VERSION ""

NS_ :

BS_:

BU_:

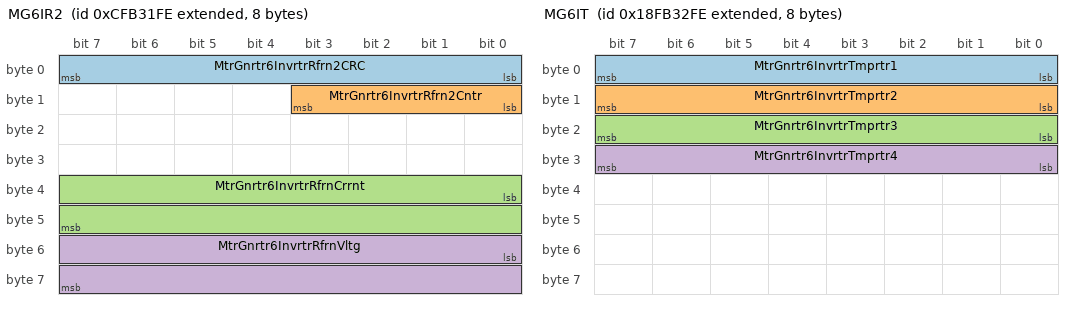
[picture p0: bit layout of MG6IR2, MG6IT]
BO_ 2365272574 MG6IR2: 8 Vector__XXX
 SG_ MtrGnrtr6InvrtrRfrn2CRC : 0|8@1+ (1,0) [0|255] "count" Vector__XXX
 SG_ MtrGnrtr6InvrtrRfrn2Cntr : 8|4@1+ (1,0) [0|15] "" Vector__XXX
 SG_ MtrGnrtr6InvrtrRfrnCrrnt : 32|16@1+ (0.125,0) [0|8031.875] "A" Vector__XXX
 SG_ MtrGnrtr6InvrtrRfrnVltg : 48|16@1+ (0.125,0) [0|8031.875] "V" Vector__XXX

BO_ 2566599422 MG6IT: 8 Vector__XXX
 SG_ MtrGnrtr6InvrtrTmprtr1 : 0|8@1+ (1,-40) [-40|210] "degC" Vector__XXX
 SG_ MtrGnrtr6InvrtrTmprtr2 : 8|8@1+ (1,-40) [-40|210] "degC" Vector__XXX
 SG_ MtrGnrtr6InvrtrTmprtr3 : 16|8@1+ (1,-40) [-40|210] "degC" Vector__XXX
 SG_ MtrGnrtr6InvrtrTmprtr4 : 24|8@1+ (1,-40) [-40|210] "degC" Vector__XXX

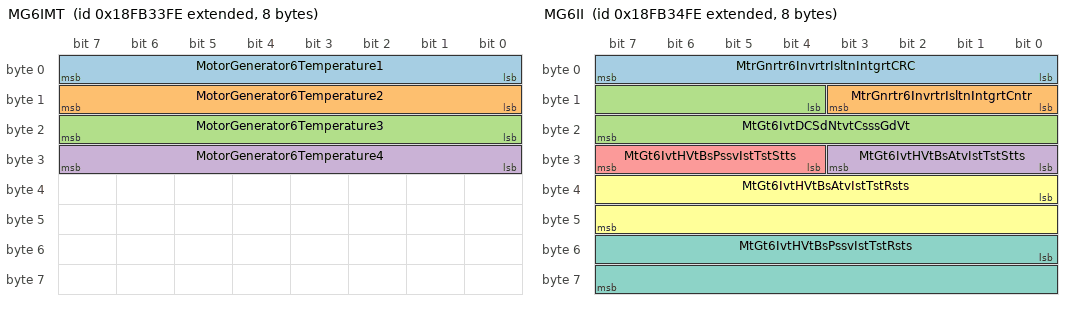
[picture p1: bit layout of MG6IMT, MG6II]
BO_ 2566599678 MG6IMT: 8 Vector__XXX
 SG_ MotorGenerator6Temperature1 : 0|8@1+ (1,-40) [-40|210] "degC" Vector__XXX
 SG_ MotorGenerator6Temperature2 : 8|8@1+ (1,-40) [-40|210] "degC" Vector__XXX
 SG_ MotorGenerator6Temperature3 : 16|8@1+ (1,-40) [-40|210] "degC" Vector__XXX
 SG_ MotorGenerator6Temperature4 : 24|8@1+ (1,-40) [-40|210] "degC" Vector__XXX

BO_ 2566599934 MG6II: 8 Vector__XXX
 SG_ MtrGnrtr6InvrtrIsltnIntgrtCRC : 0|8@1+ (1,0) [0|255] "count" Vector__XXX
 SG_ MtrGnrtr6InvrtrIsltnIntgrtCntr : 8|4@1+ (1,0) [0|15] "" Vector__XXX
 SG_ MtGt6IvtDCSdNtvtCsssGdVt : 12|12@1+ (42370,-125) [-125|125.9375] "%" Vector__XXX
 SG_ MtGt6IvtHVtBsAtvIstTstStts : 24|4@1+ (1,0) [0|15] "" Vector__XXX
 SG_ MtGt6IvtHVtBsPssvIstTstStts : 28|4@1+ (1,0) [0|15] "" Vector__XXX
 SG_ MtGt6IvtHVtBsAtvIstTstRsts : 32|16@1+ (0.1,0) [0|6425.5] "ohm/V" Vector__XXX
 SG_ MtGt6IvtHVtBsPssvIstTstRsts : 48|16@1+ (0.1,0) [0|6425.5] "ohm/V" Vector__XXX

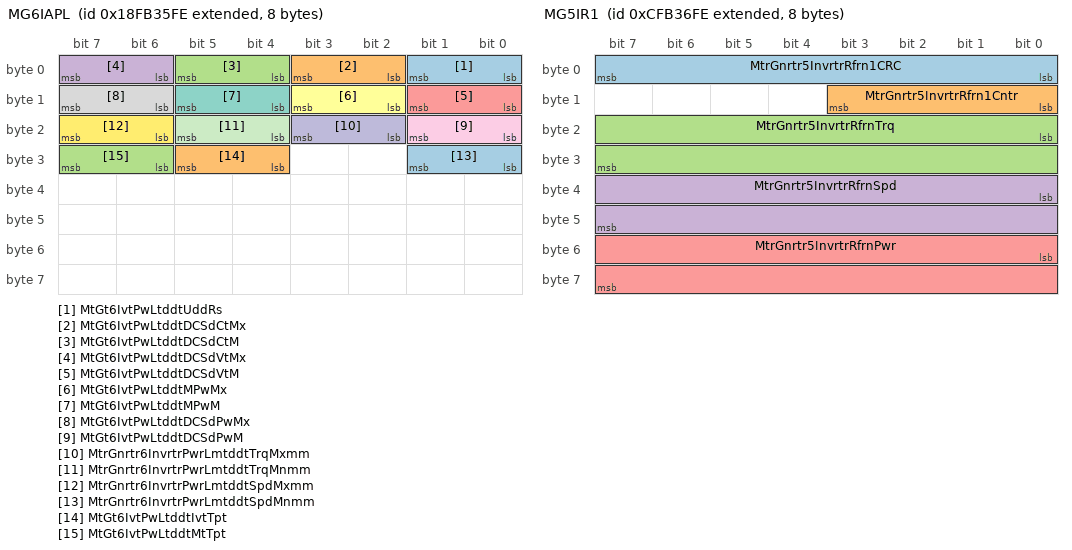
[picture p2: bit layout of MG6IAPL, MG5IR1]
BO_ 2566600190 MG6IAPL: 8 Vector__XXX
 SG_ MtGt6IvtPwLtddtUddRs : 0|2@1+ (1,0) [0|3] "" Vector__XXX
 SG_ MtGt6IvtPwLtddtDCSdCtMx : 2|2@1+ (1,0) [0|3] "" Vector__XXX
 SG_ MtGt6IvtPwLtddtDCSdCtM : 4|2@1+ (1,0) [0|3] "" Vector__XXX
 SG_ MtGt6IvtPwLtddtDCSdVtMx : 6|2@1+ (1,0) [0|3] "" Vector__XXX
 SG_ MtGt6IvtPwLtddtDCSdVtM : 8|2@1+ (1,0) [0|3] "" Vector__XXX
 SG_ MtGt6IvtPwLtddtMPwMx : 10|2@1+ (1,0) [0|3] "" Vector__XXX
 SG_ MtGt6IvtPwLtddtMPwM : 12|2@1+ (1,0) [0|3] "" Vector__XXX
 SG_ MtGt6IvtPwLtddtDCSdPwMx : 14|2@1+ (1,0) [0|3] "" Vector__XXX
 SG_ MtGt6IvtPwLtddtDCSdPwM : 16|2@1+ (1,0) [0|3] "" Vector__XXX
 SG_ MtrGnrtr6InvrtrPwrLmtddtTrqMxmm : 18|2@1+ (1,0) [0|3] "" Vector__XXX
 SG_ MtrGnrtr6InvrtrPwrLmtddtTrqMnmm : 20|2@1+ (1,0) [0|3] "" Vector__XXX
 SG_ MtrGnrtr6InvrtrPwrLmtddtSpdMxmm : 22|2@1+ (1,0) [0|3] "" Vector__XXX
 SG_ MtrGnrtr6InvrtrPwrLmtddtSpdMnmm : 24|2@1+ (1,0) [0|3] "" Vector__XXX
 SG_ MtGt6IvtPwLtddtIvtTpt : 28|2@1+ (1,0) [0|3] "" Vector__XXX
 SG_ MtGt6IvtPwLtddtMtTpt : 30|2@1+ (1,0) [0|3] "" Vector__XXX

BO_ 2365273854 MG5IR1: 8 Vector__XXX
 SG_ MtrGnrtr5InvrtrRfrn1CRC : 0|8@1+ (1,0) [0|255] "count" Vector__XXX
 SG_ MtrGnrtr5InvrtrRfrn1Cntr : 8|4@1+ (1,0) [0|15] "" Vector__XXX
 SG_ MtrGnrtr5InvrtrRfrnTrq : 16|16@1+ (0.5,0) [0|32127.5] "Nm" Vector__XXX
 SG_ MtrGnrtr5InvrtrRfrnSpd : 32|16@1+ (4,0) [0|257020] "rpm" Vector__XXX
 SG_ MtrGnrtr5InvrtrRfrnPwr : 48|16@1+ (0.0625,0) [0|4015.9375] "kW" Vector__XXX

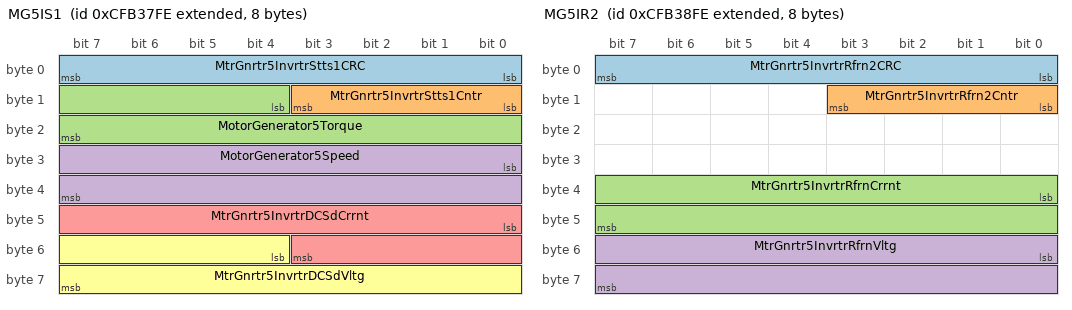
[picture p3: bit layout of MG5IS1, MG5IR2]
BO_ 2365274110 MG5IS1: 8 Vector__XXX
 SG_ MtrGnrtr5InvrtrStts1CRC : 0|8@1+ (1,0) [0|255] "count" Vector__XXX
 SG_ MtrGnrtr5InvrtrStts1Cntr : 8|4@1+ (1,0) [0|15] "" Vector__XXX
 SG_ MotorGenerator5Torque : 12|12@1+ (42370,-125) [-125|125.9375] "%" Vector__XXX
 SG_ MotorGenerator5Speed : 24|16@1+ (0.00390625,-125) [-125|125.99609375] "%" Vector__XXX
 SG_ MtrGnrtr5InvrtrDCSdCrrnt : 40|12@1+ (42370,-125) [-125|125.9375] "%" Vector__XXX
 SG_ MtrGnrtr5InvrtrDCSdVltg : 52|12@1+ (42370,-125) [-125|125.9375] "%" Vector__XXX

BO_ 2365274366 MG5IR2: 8 Vector__XXX
 SG_ MtrGnrtr5InvrtrRfrn2CRC : 0|8@1+ (1,0) [0|255] "count" Vector__XXX
 SG_ MtrGnrtr5InvrtrRfrn2Cntr : 8|4@1+ (1,0) [0|15] "" Vector__XXX
 SG_ MtrGnrtr5InvrtrRfrnCrrnt : 32|16@1+ (0.125,0) [0|8031.875] "A" Vector__XXX
 SG_ MtrGnrtr5InvrtrRfrnVltg : 48|16@1+ (0.125,0) [0|8031.875] "V" Vector__XXX

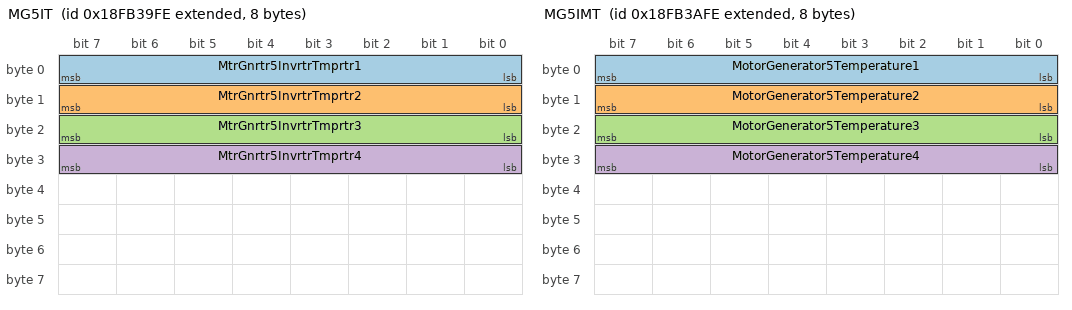
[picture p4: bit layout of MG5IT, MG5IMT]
BO_ 2566601214 MG5IT: 8 Vector__XXX
 SG_ MtrGnrtr5InvrtrTmprtr1 : 0|8@1+ (1,-40) [-40|210] "degC" Vector__XXX
 SG_ MtrGnrtr5InvrtrTmprtr2 : 8|8@1+ (1,-40) [-40|210] "degC" Vector__XXX
 SG_ MtrGnrtr5InvrtrTmprtr3 : 16|8@1+ (1,-40) [-40|210] "degC" Vector__XXX
 SG_ MtrGnrtr5InvrtrTmprtr4 : 24|8@1+ (1,-40) [-40|210] "degC" Vector__XXX

BO_ 2566601470 MG5IMT: 8 Vector__XXX
 SG_ MotorGenerator5Temperature1 : 0|8@1+ (1,-40) [-40|210] "degC" Vector__XXX
 SG_ MotorGenerator5Temperature2 : 8|8@1+ (1,-40) [-40|210] "degC" Vector__XXX
 SG_ MotorGenerator5Temperature3 : 16|8@1+ (1,-40) [-40|210] "degC" Vector__XXX
 SG_ MotorGenerator5Temperature4 : 24|8@1+ (1,-40) [-40|210] "degC" Vector__XXX

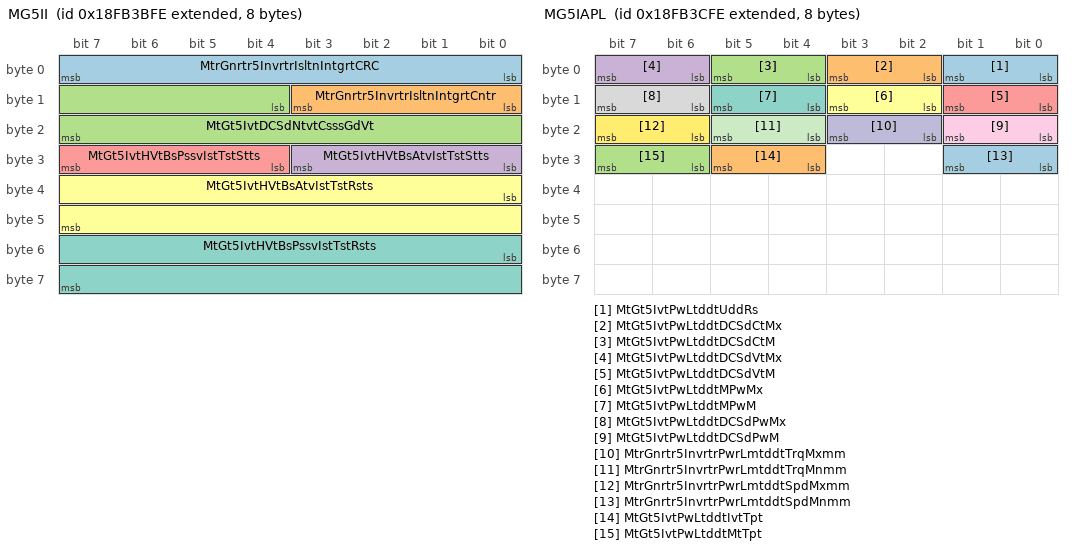
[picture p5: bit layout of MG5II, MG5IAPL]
BO_ 2566601726 MG5II: 8 Vector__XXX
 SG_ MtrGnrtr5InvrtrIsltnIntgrtCRC : 0|8@1+ (1,0) [0|255] "count" Vector__XXX
 SG_ MtrGnrtr5InvrtrIsltnIntgrtCntr : 8|4@1+ (1,0) [0|15] "" Vector__XXX
 SG_ MtGt5IvtDCSdNtvtCsssGdVt : 12|12@1+ (42370,-125) [-125|125.9375] "%" Vector__XXX
 SG_ MtGt5IvtHVtBsAtvIstTstStts : 24|4@1+ (1,0) [0|15] "" Vector__XXX
 SG_ MtGt5IvtHVtBsPssvIstTstStts : 28|4@1+ (1,0) [0|15] "" Vector__XXX
 SG_ MtGt5IvtHVtBsAtvIstTstRsts : 32|16@1+ (0.1,0) [0|6425.5] "ohm/V" Vector__XXX
 SG_ MtGt5IvtHVtBsPssvIstTstRsts : 48|16@1+ (0.1,0) [0|6425.5] "ohm/V" Vector__XXX

BO_ 2566601982 MG5IAPL: 8 Vector__XXX
 SG_ MtGt5IvtPwLtddtUddRs : 0|2@1+ (1,0) [0|3] "" Vector__XXX
 SG_ MtGt5IvtPwLtddtDCSdCtMx : 2|2@1+ (1,0) [0|3] "" Vector__XXX
 SG_ MtGt5IvtPwLtddtDCSdCtM : 4|2@1+ (1,0) [0|3] "" Vector__XXX
 SG_ MtGt5IvtPwLtddtDCSdVtMx : 6|2@1+ (1,0) [0|3] "" Vector__XXX
 SG_ MtGt5IvtPwLtddtDCSdVtM : 8|2@1+ (1,0) [0|3] "" Vector__XXX
 SG_ MtGt5IvtPwLtddtMPwMx : 10|2@1+ (1,0) [0|3] "" Vector__XXX
 SG_ MtGt5IvtPwLtddtMPwM : 12|2@1+ (1,0) [0|3] "" Vector__XXX
 SG_ MtGt5IvtPwLtddtDCSdPwMx : 14|2@1+ (1,0) [0|3] "" Vector__XXX
 SG_ MtGt5IvtPwLtddtDCSdPwM : 16|2@1+ (1,0) [0|3] "" Vector__XXX
 SG_ MtrGnrtr5InvrtrPwrLmtddtTrqMxmm : 18|2@1+ (1,0) [0|3] "" Vector__XXX
 SG_ MtrGnrtr5InvrtrPwrLmtddtTrqMnmm : 20|2@1+ (1,0) [0|3] "" Vector__XXX
 SG_ MtrGnrtr5InvrtrPwrLmtddtSpdMxmm : 22|2@1+ (1,0) [0|3] "" Vector__XXX
 SG_ MtrGnrtr5InvrtrPwrLmtddtSpdMnmm : 24|2@1+ (1,0) [0|3] "" Vector__XXX
 SG_ MtGt5IvtPwLtddtIvtTpt : 28|2@1+ (1,0) [0|3] "" Vector__XXX
 SG_ MtGt5IvtPwLtddtMtTpt : 30|2@1+ (1,0) [0|3] "" Vector__XXX

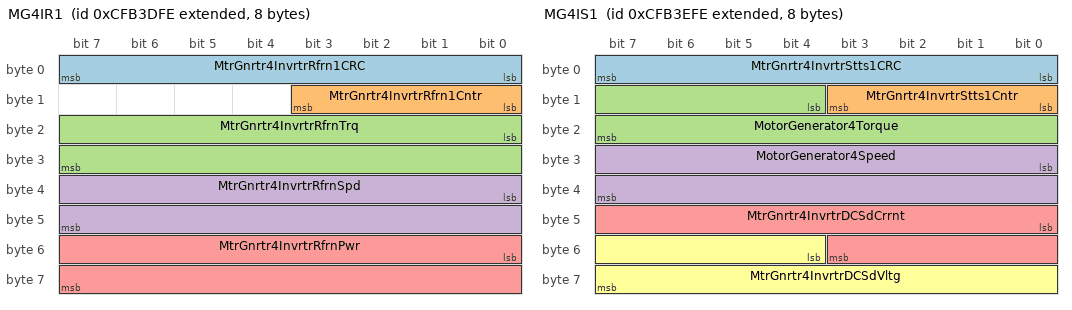
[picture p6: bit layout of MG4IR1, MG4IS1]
BO_ 2365275646 MG4IR1: 8 Vector__XXX
 SG_ MtrGnrtr4InvrtrRfrn1CRC : 0|8@1+ (1,0) [0|255] "count" Vector__XXX
 SG_ MtrGnrtr4InvrtrRfrn1Cntr : 8|4@1+ (1,0) [0|15] "" Vector__XXX
 SG_ MtrGnrtr4InvrtrRfrnTrq : 16|16@1+ (0.5,0) [0|32127.5] "Nm" Vector__XXX
 SG_ MtrGnrtr4InvrtrRfrnSpd : 32|16@1+ (4,0) [0|257020] "rpm" Vector__XXX
 SG_ MtrGnrtr4InvrtrRfrnPwr : 48|16@1+ (0.0625,0) [0|4015.9375] "kW" Vector__XXX

BO_ 2365275902 MG4IS1: 8 Vector__XXX
 SG_ MtrGnrtr4InvrtrStts1CRC : 0|8@1+ (1,0) [0|255] "count" Vector__XXX
 SG_ MtrGnrtr4InvrtrStts1Cntr : 8|4@1+ (1,0) [0|15] "" Vector__XXX
 SG_ MotorGenerator4Torque : 12|12@1+ (42370,-125) [-125|125.9375] "%" Vector__XXX
 SG_ MotorGenerator4Speed : 24|16@1+ (0.00390625,-125) [-125|125.99609375] "%" Vector__XXX
 SG_ MtrGnrtr4InvrtrDCSdCrrnt : 40|12@1+ (42370,-125) [-125|125.9375] "%" Vector__XXX
 SG_ MtrGnrtr4InvrtrDCSdVltg : 52|12@1+ (42370,-125) [-125|125.9375] "%" Vector__XXX

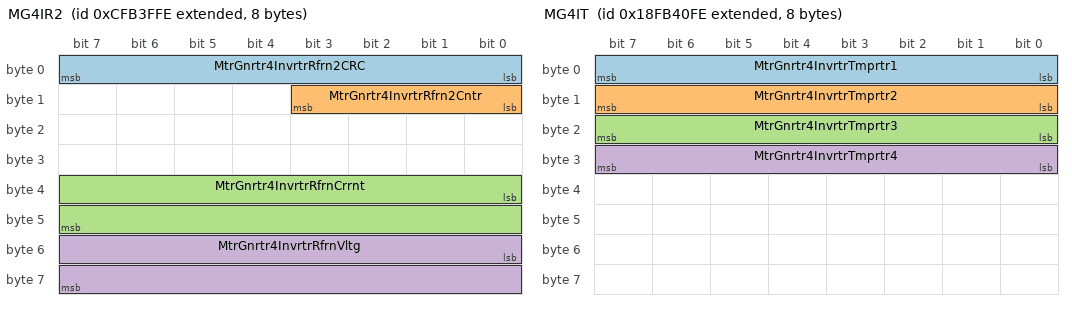
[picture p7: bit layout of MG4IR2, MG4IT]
BO_ 2365276158 MG4IR2: 8 Vector__XXX
 SG_ MtrGnrtr4InvrtrRfrn2CRC : 0|8@1+ (1,0) [0|255] "count" Vector__XXX
 SG_ MtrGnrtr4InvrtrRfrn2Cntr : 8|4@1+ (1,0) [0|15] "" Vector__XXX
 SG_ MtrGnrtr4InvrtrRfrnCrrnt : 32|16@1+ (0.125,0) [0|8031.875] "A" Vector__XXX
 SG_ MtrGnrtr4InvrtrRfrnVltg : 48|16@1+ (0.125,0) [0|8031.875] "V" Vector__XXX

BO_ 2566603006 MG4IT: 8 Vector__XXX
 SG_ MtrGnrtr4InvrtrTmprtr1 : 0|8@1+ (1,-40) [-40|210] "degC" Vector__XXX
 SG_ MtrGnrtr4InvrtrTmprtr2 : 8|8@1+ (1,-40) [-40|210] "degC" Vector__XXX
 SG_ MtrGnrtr4InvrtrTmprtr3 : 16|8@1+ (1,-40) [-40|210] "degC" Vector__XXX
 SG_ MtrGnrtr4InvrtrTmprtr4 : 24|8@1+ (1,-40) [-40|210] "degC" Vector__XXX

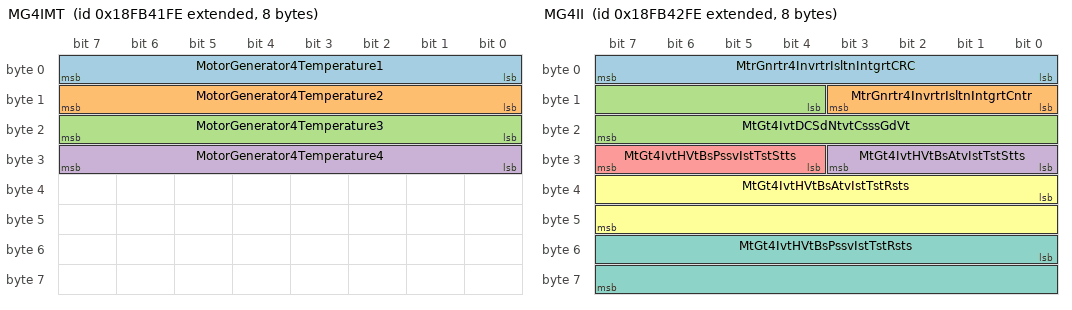
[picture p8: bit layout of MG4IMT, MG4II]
BO_ 2566603262 MG4IMT: 8 Vector__XXX
 SG_ MotorGenerator4Temperature1 : 0|8@1+ (1,-40) [-40|210] "degC" Vector__XXX
 SG_ MotorGenerator4Temperature2 : 8|8@1+ (1,-40) [-40|210] "degC" Vector__XXX
 SG_ MotorGenerator4Temperature3 : 16|8@1+ (1,-40) [-40|210] "degC" Vector__XXX
 SG_ MotorGenerator4Temperature4 : 24|8@1+ (1,-40) [-40|210] "degC" Vector__XXX

BO_ 2566603518 MG4II: 8 Vector__XXX
 SG_ MtrGnrtr4InvrtrIsltnIntgrtCRC : 0|8@1+ (1,0) [0|255] "count" Vector__XXX
 SG_ MtrGnrtr4InvrtrIsltnIntgrtCntr : 8|4@1+ (1,0) [0|15] "" Vector__XXX
 SG_ MtGt4IvtDCSdNtvtCsssGdVt : 12|12@1+ (42370,-125) [-125|125.9375] "%" Vector__XXX
 SG_ MtGt4IvtHVtBsAtvIstTstStts : 24|4@1+ (1,0) [0|15] "" Vector__XXX
 SG_ MtGt4IvtHVtBsPssvIstTstStts : 28|4@1+ (1,0) [0|15] "" Vector__XXX
 SG_ MtGt4IvtHVtBsAtvIstTstRsts : 32|16@1+ (0.1,0) [0|6425.5] "ohm/V" Vector__XXX
 SG_ MtGt4IvtHVtBsPssvIstTstRsts : 48|16@1+ (0.1,0) [0|6425.5] "ohm/V" Vector__XXX

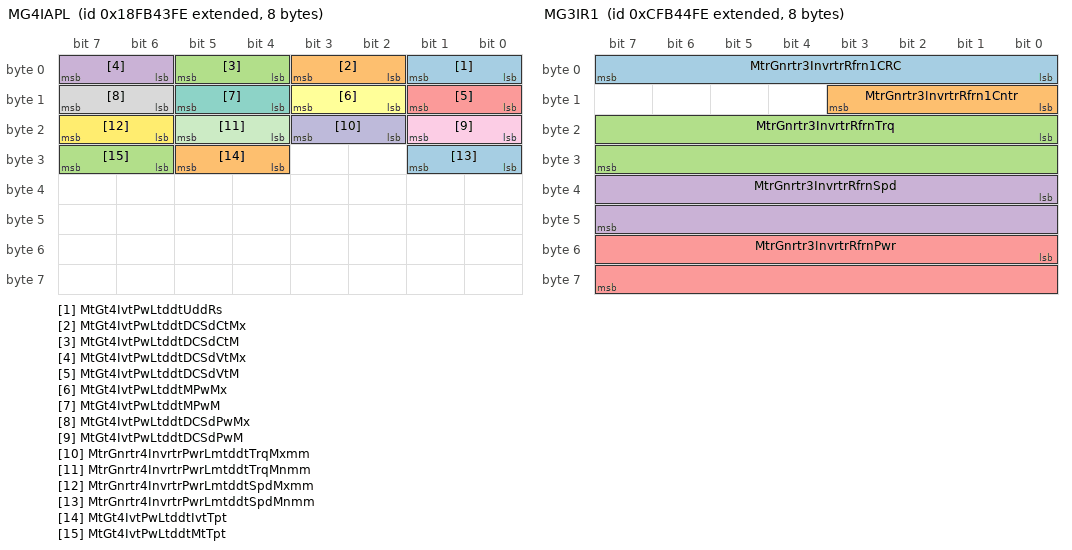
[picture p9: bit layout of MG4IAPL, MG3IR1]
BO_ 2566603774 MG4IAPL: 8 Vector__XXX
 SG_ MtGt4IvtPwLtddtUddRs : 0|2@1+ (1,0) [0|3] "" Vector__XXX
 SG_ MtGt4IvtPwLtddtDCSdCtMx : 2|2@1+ (1,0) [0|3] "" Vector__XXX
 SG_ MtGt4IvtPwLtddtDCSdCtM : 4|2@1+ (1,0) [0|3] "" Vector__XXX
 SG_ MtGt4IvtPwLtddtDCSdVtMx : 6|2@1+ (1,0) [0|3] "" Vector__XXX
 SG_ MtGt4IvtPwLtddtDCSdVtM : 8|2@1+ (1,0) [0|3] "" Vector__XXX
 SG_ MtGt4IvtPwLtddtMPwMx : 10|2@1+ (1,0) [0|3] "" Vector__XXX
 SG_ MtGt4IvtPwLtddtMPwM : 12|2@1+ (1,0) [0|3] "" Vector__XXX
 SG_ MtGt4IvtPwLtddtDCSdPwMx : 14|2@1+ (1,0) [0|3] "" Vector__XXX
 SG_ MtGt4IvtPwLtddtDCSdPwM : 16|2@1+ (1,0) [0|3] "" Vector__XXX
 SG_ MtrGnrtr4InvrtrPwrLmtddtTrqMxmm : 18|2@1+ (1,0) [0|3] "" Vector__XXX
 SG_ MtrGnrtr4InvrtrPwrLmtddtTrqMnmm : 20|2@1+ (1,0) [0|3] "" Vector__XXX
 SG_ MtrGnrtr4InvrtrPwrLmtddtSpdMxmm : 22|2@1+ (1,0) [0|3] "" Vector__XXX
 SG_ MtrGnrtr4InvrtrPwrLmtddtSpdMnmm : 24|2@1+ (1,0) [0|3] "" Vector__XXX
 SG_ MtGt4IvtPwLtddtIvtTpt : 28|2@1+ (1,0) [0|3] "" Vector__XXX
 SG_ MtGt4IvtPwLtddtMtTpt : 30|2@1+ (1,0) [0|3] "" Vector__XXX

BO_ 2365277438 MG3IR1: 8 Vector__XXX
 SG_ MtrGnrtr3InvrtrRfrn1CRC : 0|8@1+ (1,0) [0|255] "count" Vector__XXX
 SG_ MtrGnrtr3InvrtrRfrn1Cntr : 8|4@1+ (1,0) [0|15] "" Vector__XXX
 SG_ MtrGnrtr3InvrtrRfrnTrq : 16|16@1+ (0.5,0) [0|32127.5] "Nm" Vector__XXX
 SG_ MtrGnrtr3InvrtrRfrnSpd : 32|16@1+ (4,0) [0|257020] "rpm" Vector__XXX
 SG_ MtrGnrtr3InvrtrRfrnPwr : 48|16@1+ (0.0625,0) [0|4015.9375] "kW" Vector__XXX

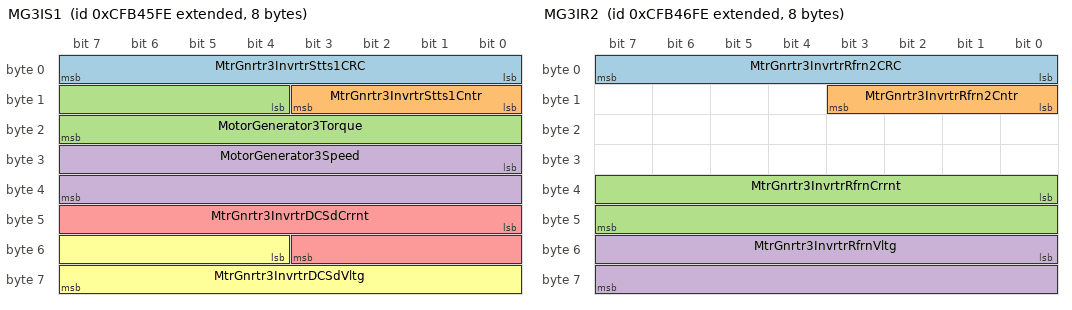
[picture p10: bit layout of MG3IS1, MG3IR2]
BO_ 2365277694 MG3IS1: 8 Vector__XXX
 SG_ MtrGnrtr3InvrtrStts1CRC : 0|8@1+ (1,0) [0|255] "count" Vector__XXX
 SG_ MtrGnrtr3InvrtrStts1Cntr : 8|4@1+ (1,0) [0|15] "" Vector__XXX
 SG_ MotorGenerator3Torque : 12|12@1+ (42370,-125) [-125|125.9375] "%" Vector__XXX
 SG_ MotorGenerator3Speed : 24|16@1+ (0.00390625,-125) [-125|125.99609375] "%" Vector__XXX
 SG_ MtrGnrtr3InvrtrDCSdCrrnt : 40|12@1+ (42370,-125) [-125|125.9375] "%" Vector__XXX
 SG_ MtrGnrtr3InvrtrDCSdVltg : 52|12@1+ (42370,-125) [-125|125.9375] "%" Vector__XXX

BO_ 2365277950 MG3IR2: 8 Vector__XXX
 SG_ MtrGnrtr3InvrtrRfrn2CRC : 0|8@1+ (1,0) [0|255] "count" Vector__XXX
 SG_ MtrGnrtr3InvrtrRfrn2Cntr : 8|4@1+ (1,0) [0|15] "" Vector__XXX
 SG_ MtrGnrtr3InvrtrRfrnCrrnt : 32|16@1+ (0.125,0) [0|8031.875] "A" Vector__XXX
 SG_ MtrGnrtr3InvrtrRfrnVltg : 48|16@1+ (0.125,0) [0|8031.875] "V" Vector__XXX

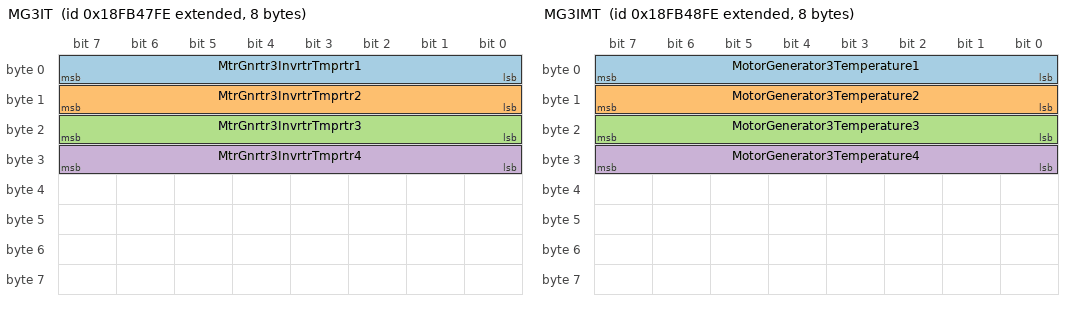
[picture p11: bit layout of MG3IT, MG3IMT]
BO_ 2566604798 MG3IT: 8 Vector__XXX
 SG_ MtrGnrtr3InvrtrTmprtr1 : 0|8@1+ (1,-40) [-40|210] "degC" Vector__XXX
 SG_ MtrGnrtr3InvrtrTmprtr2 : 8|8@1+ (1,-40) [-40|210] "degC" Vector__XXX
 SG_ MtrGnrtr3InvrtrTmprtr3 : 16|8@1+ (1,-40) [-40|210] "degC" Vector__XXX
 SG_ MtrGnrtr3InvrtrTmprtr4 : 24|8@1+ (1,-40) [-40|210] "degC" Vector__XXX

BO_ 2566605054 MG3IMT: 8 Vector__XXX
 SG_ MotorGenerator3Temperature1 : 0|8@1+ (1,-40) [-40|210] "degC" Vector__XXX
 SG_ MotorGenerator3Temperature2 : 8|8@1+ (1,-40) [-40|210] "degC" Vector__XXX
 SG_ MotorGenerator3Temperature3 : 16|8@1+ (1,-40) [-40|210] "degC" Vector__XXX
 SG_ MotorGenerator3Temperature4 : 24|8@1+ (1,-40) [-40|210] "degC" Vector__XXX

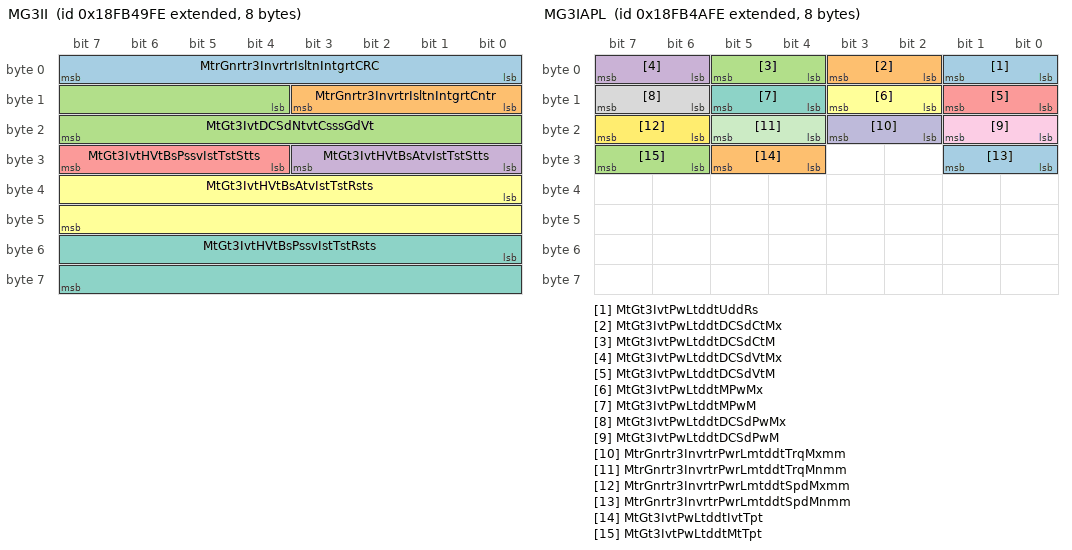
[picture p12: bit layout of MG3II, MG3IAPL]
BO_ 2566605310 MG3II: 8 Vector__XXX
 SG_ MtrGnrtr3InvrtrIsltnIntgrtCRC : 0|8@1+ (1,0) [0|255] "count" Vector__XXX
 SG_ MtrGnrtr3InvrtrIsltnIntgrtCntr : 8|4@1+ (1,0) [0|15] "" Vector__XXX
 SG_ MtGt3IvtDCSdNtvtCsssGdVt : 12|12@1+ (42370,-125) [-125|125.9375] "%" Vector__XXX
 SG_ MtGt3IvtHVtBsAtvIstTstStts : 24|4@1+ (1,0) [0|15] "" Vector__XXX
 SG_ MtGt3IvtHVtBsPssvIstTstStts : 28|4@1+ (1,0) [0|15] "" Vector__XXX
 SG_ MtGt3IvtHVtBsAtvIstTstRsts : 32|16@1+ (0.1,0) [0|6425.5] "ohm/V" Vector__XXX
 SG_ MtGt3IvtHVtBsPssvIstTstRsts : 48|16@1+ (0.1,0) [0|6425.5] "ohm/V" Vector__XXX

BO_ 2566605566 MG3IAPL: 8 Vector__XXX
 SG_ MtGt3IvtPwLtddtUddRs : 0|2@1+ (1,0) [0|3] "" Vector__XXX
 SG_ MtGt3IvtPwLtddtDCSdCtMx : 2|2@1+ (1,0) [0|3] "" Vector__XXX
 SG_ MtGt3IvtPwLtddtDCSdCtM : 4|2@1+ (1,0) [0|3] "" Vector__XXX
 SG_ MtGt3IvtPwLtddtDCSdVtMx : 6|2@1+ (1,0) [0|3] "" Vector__XXX
 SG_ MtGt3IvtPwLtddtDCSdVtM : 8|2@1+ (1,0) [0|3] "" Vector__XXX
 SG_ MtGt3IvtPwLtddtMPwMx : 10|2@1+ (1,0) [0|3] "" Vector__XXX
 SG_ MtGt3IvtPwLtddtMPwM : 12|2@1+ (1,0) [0|3] "" Vector__XXX
 SG_ MtGt3IvtPwLtddtDCSdPwMx : 14|2@1+ (1,0) [0|3] "" Vector__XXX
 SG_ MtGt3IvtPwLtddtDCSdPwM : 16|2@1+ (1,0) [0|3] "" Vector__XXX
 SG_ MtrGnrtr3InvrtrPwrLmtddtTrqMxmm : 18|2@1+ (1,0) [0|3] "" Vector__XXX
 SG_ MtrGnrtr3InvrtrPwrLmtddtTrqMnmm : 20|2@1+ (1,0) [0|3] "" Vector__XXX
 SG_ MtrGnrtr3InvrtrPwrLmtddtSpdMxmm : 22|2@1+ (1,0) [0|3] "" Vector__XXX
 SG_ MtrGnrtr3InvrtrPwrLmtddtSpdMnmm : 24|2@1+ (1,0) [0|3] "" Vector__XXX
 SG_ MtGt3IvtPwLtddtIvtTpt : 28|2@1+ (1,0) [0|3] "" Vector__XXX
 SG_ MtGt3IvtPwLtddtMtTpt : 30|2@1+ (1,0) [0|3] "" Vector__XXX

BO_ 2566605822 ADSF: 8 Vector__XXX
 SG_ SAddssCtDvTSC1CtPpsP7 : 0|8@1+ (1,0) [0|255] "SA" Vector__XXX
 SG_ TSC1CntrlPrpsP7RdnssStts : 8|2@1+ (1,0) [0|3] "" Vector__XXX

BO_ 2566606078 CCSI2: 8 Vector__XXX
 SG_ CabHeaterPower : 0|16@1+ (2,0) [0|128510] "W" Vector__XXX

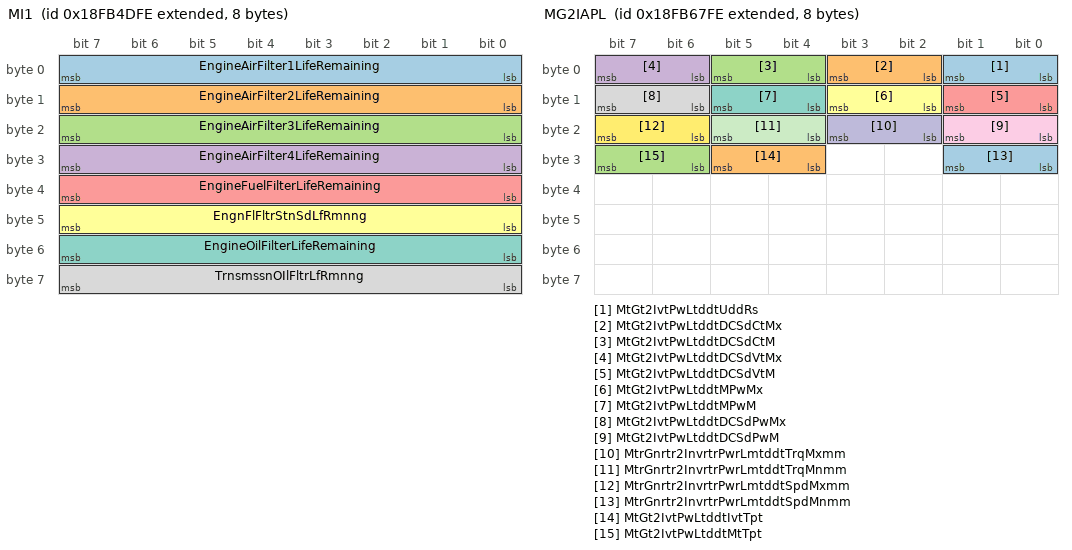
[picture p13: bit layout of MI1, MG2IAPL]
BO_ 2566606334 MI1: 8 Vector__XXX
 SG_ EngineAirFilter1LifeRemaining : 0|8@1+ (0.4,0) [0|100] "%" Vector__XXX
 SG_ EngineAirFilter2LifeRemaining : 8|8@1+ (0.4,0) [0|100] "%" Vector__XXX
 SG_ EngineAirFilter3LifeRemaining : 16|8@1+ (0.4,0) [0|100] "%" Vector__XXX
 SG_ EngineAirFilter4LifeRemaining : 24|8@1+ (0.4,0) [0|100] "%" Vector__XXX
 SG_ EngineFuelFilterLifeRemaining : 32|8@1+ (0.4,0) [0|100] "%" Vector__XXX
 SG_ EngnFlFltrStnSdLfRmnng : 40|8@1+ (0.4,0) [0|100] "%" Vector__XXX
 SG_ EngineOilFilterLifeRemaining : 48|8@1+ (0.4,0) [0|100] "%" Vector__XXX
 SG_ TrnsmssnOIlFltrLfRmnng : 56|8@1+ (0.4,0) [0|100] "%" Vector__XXX

BO_ 2499497726 HCI1: 8 Vector__XXX
 SG_ HoistLeverPosition : 0|16@1+ (0.005,-150) [-150|171.275] "%" Vector__XXX
 SG_ HoistLeverDetentPositionStatus : 16|2@1+ (1,0) [0|3] "" Vector__XXX

BO_ 2633715710 HVESP6HIST: 200 Vector__XXX
 SG_ HVESP6StateofHealth : 0|8@1+ (0.4,0) [0|100] "%" Vector__XXX
 SG_ HVESP6CnttrOpnUndrLdCnt : 8|16@1+ (1,0) [0|64255] "count" Vector__XXX
 SG_ HVESP6TotalEnergyThroughput : 24|32@1+ (100,0) [0|421108121500] "Watt-hour" Vector__XXX
 SG_ HVESP6TotalAccumulatedCharge : 56|32@1+ (100,0) [0|421108121500] "Ah" Vector__XXX

BO_ 2566607102 HVESP6CFG: 200 Vector__XXX
 SG_ HVESP6NominalVoltage : 0|16@1+ (0.05,0) [0|3212.75] "V" Vector__XXX
 SG_ HVESP6RmmnddMnmmOprtngVltg : 16|16@1+ (0.05,0) [0|3212.75] "V" Vector__XXX
 SG_ HVESP6RmmnddMxmmOprtngVltg : 32|16@1+ (0.05,0) [0|3212.75] "V" Vector__XXX
 SG_ HVESP6RmmnddMnmmSttOfChrg : 48|16@1+ (0.0015625,0) [0|100.3984375] "%" Vector__XXX
 SG_ HVESP6RmmnddMxmmSttOfChrg : 64|16@1+ (0.0015625,0) [0|100.3984375] "%" Vector__XXX
 SG_ HVESP6RmmnddMxmmOprtngTmprtr : 80|16@1+ (0.03125,-273) [-273|1734.96875] "degC" Vector__XXX
 SG_ HVESP6RmmnddMnmmOprtngTmprtr : 96|16@1+ (0.03125,-273) [-273|1734.96875] "degC" Vector__XXX
 SG_ HVESP6CellMaximumVoltageLimit : 112|8@1+ (0.02044,0) [0|5.11] "V" Vector__XXX
 SG_ HVESP6CellMinimumVoltageLimit : 120|8@1+ (0.02044,0) [0|5.11] "V" Vector__XXX

BO_ 2633716222 HVESP5HIST: 200 Vector__XXX
 SG_ HVESP5StateofHealth : 0|8@1+ (0.4,0) [0|100] "%" Vector__XXX
 SG_ HVESP5CnttrOpnUndrLdCnt : 8|16@1+ (1,0) [0|64255] "count" Vector__XXX
 SG_ HVESP5TotalEnergyThroughput : 24|32@1+ (100,0) [0|421108121500] "Watt-hour" Vector__XXX
 SG_ HVESP5TotalAccumulatedCharge : 56|32@1+ (100,0) [0|421108121500] "Ah" Vector__XXX

BO_ 2566607614 HVESP5CFG: 200 Vector__XXX
 SG_ HVESP5NominalVoltage : 0|16@1+ (0.05,0) [0|3212.75] "V" Vector__XXX
 SG_ HVESP5RmmnddMnmmOprtngVltg : 16|16@1+ (0.05,0) [0|3212.75] "V" Vector__XXX
 SG_ HVESP5RmmnddMxmmOprtngVltg : 32|16@1+ (0.05,0) [0|3212.75] "V" Vector__XXX
 SG_ HVESP5RmmnddMnmmSttOfChrg : 48|16@1+ (0.0015625,0) [0|100.3984375] "%" Vector__XXX
 SG_ HVESP5RmmnddMxmmSttOfChrg : 64|16@1+ (0.0015625,0) [0|100.3984375] "%" Vector__XXX
 SG_ HVESP5RmmnddMxmmOprtngTmprtr : 80|16@1+ (0.03125,-273) [-273|1734.96875] "degC" Vector__XXX
 SG_ HVESP5RmmnddMnmmOprtngTmprtr : 96|16@1+ (0.03125,-273) [-273|1734.96875] "degC" Vector__XXX
 SG_ HVESP5CellMaximumVoltageLimit : 112|8@1+ (0.02044,0) [0|5.11] "V" Vector__XXX
 SG_ HVESP5CellMinimumVoltageLimit : 120|8@1+ (0.02044,0) [0|5.11] "V" Vector__XXX

BO_ 2633716734 HVESP4HIST: 200 Vector__XXX
 SG_ HVESP4StateofHealth : 0|8@1+ (0.4,0) [0|100] "%" Vector__XXX
 SG_ HVESP4CnttrOpnUndrLdCnt : 8|16@1+ (1,0) [0|64255] "count" Vector__XXX
 SG_ HVESP4TotalEnergyThroughput : 24|32@1+ (100,0) [0|421108121500] "Watt-hour" Vector__XXX
 SG_ HVESP4TotalAccumulatedCharge : 56|32@1+ (100,0) [0|421108121500] "Ah" Vector__XXX

BO_ 2566608126 HVESP4CFG: 200 Vector__XXX
 SG_ HVESP4NominalVoltage : 0|16@1+ (0.05,0) [0|3212.75] "V" Vector__XXX
 SG_ HVESP4RmmnddMnmmOprtngVltg : 16|16@1+ (0.05,0) [0|3212.75] "V" Vector__XXX
 SG_ HVESP4RmmnddMxmmOprtngVltg : 32|16@1+ (0.05,0) [0|3212.75] "V" Vector__XXX
 SG_ HVESP4RmmnddMnmmSttOfChrg : 48|16@1+ (0.0015625,0) [0|100.3984375] "%" Vector__XXX
 SG_ HVESP4RmmnddMxmmSttOfChrg : 64|16@1+ (0.0015625,0) [0|100.3984375] "%" Vector__XXX
 SG_ HVESP4RmmnddMxmmOprtngTmprtr : 80|16@1+ (0.03125,-273) [-273|1734.96875] "degC" Vector__XXX
 SG_ HVESP4RmmnddMnmmOprtngTmprtr : 96|16@1+ (0.03125,-273) [-273|1734.96875] "degC" Vector__XXX
 SG_ HVESP4CellMaximumVoltageLimit : 112|8@1+ (0.02044,0) [0|5.11] "V" Vector__XXX
 SG_ HVESP4CellMinimumVoltageLimit : 120|8@1+ (0.02044,0) [0|5.11] "V" Vector__XXX

BO_ 2633717246 HVESP3HIST: 200 Vector__XXX
 SG_ HVESP3StateofHealth : 0|8@1+ (0.4,0) [0|100] "%" Vector__XXX
 SG_ HVESP3CnttrOpnUndrLdCnt : 8|16@1+ (1,0) [0|64255] "count" Vector__XXX
 SG_ HVESP3TotalEnergyThroughput : 24|32@1+ (100,0) [0|421108121500] "Watt-hour" Vector__XXX
 SG_ HVESP3TotalAccumulatedCharge : 56|32@1+ (100,0) [0|421108121500] "Ah" Vector__XXX

BO_ 2566608638 HVESP3CFG: 200 Vector__XXX
 SG_ HVESP3NominalVoltage : 0|16@1+ (0.05,0) [0|3212.75] "V" Vector__XXX
 SG_ HVESP3RmmnddMnmmOprtngVltg : 16|16@1+ (0.05,0) [0|3212.75] "V" Vector__XXX
 SG_ HVESP3RmmnddMxmmOprtngVltg : 32|16@1+ (0.05,0) [0|3212.75] "V" Vector__XXX
 SG_ HVESP3RmmnddMnmmSttOfChrg : 48|16@1+ (0.0015625,0) [0|100.3984375] "%" Vector__XXX
 SG_ HVESP3RmmnddMxmmSttOfChrg : 64|16@1+ (0.0015625,0) [0|100.3984375] "%" Vector__XXX
 SG_ HVESP3RmmnddMxmmOprtngTmprtr : 80|16@1+ (0.03125,-273) [-273|1734.96875] "degC" Vector__XXX
 SG_ HVESP3RmmnddMnmmOprtngTmprtr : 96|16@1+ (0.03125,-273) [-273|1734.96875] "degC" Vector__XXX
 SG_ HVESP3CellMaximumVoltageLimit : 112|8@1+ (0.02044,0) [0|5.11] "V" Vector__XXX
 SG_ HVESP3CellMinimumVoltageLimit : 120|8@1+ (0.02044,0) [0|5.11] "V" Vector__XXX

BO_ 2633717758 HVESP2HIST: 200 Vector__XXX
 SG_ HVESP2StateofHealth : 0|8@1+ (0.4,0) [0|100] "%" Vector__XXX
 SG_ HVESP2CnttrOpnUndrLdCnt : 8|16@1+ (1,0) [0|64255] "count" Vector__XXX
 SG_ HVESP2TotalEnergyThroughput : 24|32@1+ (100,0) [0|421108121500] "Watt-hour" Vector__XXX
 SG_ HVESP2TotalAccumulatedCharge : 56|32@1+ (100,0) [0|421108121500] "Ah" Vector__XXX

BO_ 2566609150 HVESP2CFG: 200 Vector__XXX
 SG_ HVESP2NominalVoltage : 0|16@1+ (0.05,0) [0|3212.75] "V" Vector__XXX
 SG_ HVESP2RmmnddMnmmOprtngVltg : 16|16@1+ (0.05,0) [0|3212.75] "V" Vector__XXX
 SG_ HVESP2RmmnddMxmmOprtngVltg : 32|16@1+ (0.05,0) [0|3212.75] "V" Vector__XXX
 SG_ HVESP2RmmnddMnmmSttOfChrg : 48|16@1+ (0.0015625,0) [0|100.3984375] "%" Vector__XXX
 SG_ HVESP2RmmnddMxmmSttOfChrg : 64|16@1+ (0.0015625,0) [0|100.3984375] "%" Vector__XXX
 SG_ HVESP2RmmnddMxmmOprtngTmprtr : 80|16@1+ (0.03125,-273) [-273|1734.96875] "degC" Vector__XXX
 SG_ HVESP2RmmnddMnmmOprtngTmprtr : 96|16@1+ (0.03125,-273) [-273|1734.96875] "degC" Vector__XXX
 SG_ HVESP2CellMaximumVoltageLimit : 112|8@1+ (0.02044,0) [0|5.11] "V" Vector__XXX
 SG_ HVESP2CellMinimumVoltageLimit : 120|8@1+ (0.02044,0) [0|5.11] "V" Vector__XXX

BO_ 2633718270 HVESP1HIST: 200 Vector__XXX
 SG_ HVESP1StateofHealth : 0|8@1+ (0.4,0) [0|100] "%" Vector__XXX
 SG_ HVESP1CnttrOpnUndrLdCnt : 8|16@1+ (1,0) [0|64255] "count" Vector__XXX
 SG_ HVESP1TotalEnergyThroughput : 24|32@1+ (100,0) [0|421108121500] "Watt-hour" Vector__XXX
 SG_ HVESP1TotalAccumulatedCharge : 56|32@1+ (100,0) [0|421108121500] "Ah" Vector__XXX

BO_ 2566609662 HVESP1CFG: 200 Vector__XXX
 SG_ HVESP1NominalVoltage : 0|16@1+ (0.05,0) [0|3212.75] "V" Vector__XXX
 SG_ HVESP1RmmnddMnmmOprtngVltg : 16|16@1+ (0.05,0) [0|3212.75] "V" Vector__XXX
 SG_ HVESP1RmmnddMxmmOprtngVltg : 32|16@1+ (0.05,0) [0|3212.75] "V" Vector__XXX
 SG_ HVESP1RmmnddMnmmSttOfChrg : 48|16@1+ (0.0015625,0) [0|100.3984375] "%" Vector__XXX
 SG_ HVESP1RmmnddMxmmSttOfChrg : 64|16@1+ (0.0015625,0) [0|100.3984375] "%" Vector__XXX
 SG_ HVESP1RmmnddMxmmOprtngTmprtr : 80|16@1+ (0.03125,-273) [-273|1734.96875] "degC" Vector__XXX
 SG_ HVESP1RmmnddMnmmOprtngTmprtr : 96|16@1+ (0.03125,-273) [-273|1734.96875] "degC" Vector__XXX
 SG_ HVESP1CellMaximumVoltageLimit : 112|8@1+ (0.02044,0) [0|5.11] "V" Vector__XXX
 SG_ HVESP1CellMinimumVoltageLimit : 120|8@1+ (0.02044,0) [0|5.11] "V" Vector__XXX

BO_ 2633718782 VFSSM1DET: 24 Vector__XXX
 SG_ VFSSMdl1Dttr1DttrTp : 0|4@1+ (1,0) [0|15] "" Vector__XXX
 SG_ VFSSMdl1Dttr1DttrDtSLOT : 4|4@1+ (1,0) [0|15] "" Vector__XXX
 SG_ VFSSMdl1Dttr2DttrTp : 24|4@1+ (1,0) [0|15] "" Vector__XXX
 SG_ VFSSMdl1Dttr2DttrDtSLOT : 28|4@1+ (1,0) [0|15] "" Vector__XXX
 SG_ VFSSMdl1Dttr3DttrTp : 48|4@1+ (1,0) [0|15] "" Vector__XXX
 SG_ VFSSMdl1Dttr3DttrDtSLOT : 52|4@1+ (1,0) [0|15] "" Vector__XXX
 SG_ VFSSMdl1Dttr4DttrTp : 72|4@1+ (1,0) [0|15] "" Vector__XXX
 SG_ VFSSMdl1Dttr4DttrDtSLOT : 76|4@1+ (1,0) [0|15] "" Vector__XXX
 SG_ VFSSMdl1Dttr5DttrTp : 96|4@1+ (1,0) [0|15] "" Vector__XXX
 SG_ VFSSMdl1Dttr5DttrDtSLOT : 100|4@1+ (1,0) [0|15] "" Vector__XXX
 SG_ VFSSMdl1Dttr6DttrTp : 120|4@1+ (1,0) [0|15] "" Vector__XXX
 SG_ VFSSMdl1Dttr6DttrDtSLOT : 124|4@1+ (1,0) [0|15] "" Vector__XXX
 SG_ VFSSMdl1Dttr7DttrTp : 144|4@1+ (1,0) [0|15] "" Vector__XXX
 SG_ VFSSMdl1Dttr7DttrDtSLOT : 148|4@1+ (1,0) [0|15] "" Vector__XXX
 SG_ VFSSMdl1Dttr8DttrTp : 168|4@1+ (1,0) [0|15] "" Vector__XXX
 SG_ VFSSMdl1Dttr8DttrDtSLOT : 172|4@1+ (1,0) [0|15] "" Vector__XXX

BO_ 2633719038 VFSSM2DET: 24 Vector__XXX
 SG_ VFSSMdl2Dttr1DttrTp : 0|4@1+ (1,0) [0|15] "" Vector__XXX
 SG_ VFSSMdl2Dttr1DttrDtSLOT : 4|4@1+ (1,0) [0|15] "" Vector__XXX
 SG_ VFSSMdl2Dttr2DttrTp : 24|4@1+ (1,0) [0|15] "" Vector__XXX
 SG_ VFSSMdl2Dttr2DttrDtSLOT : 28|4@1+ (1,0) [0|15] "" Vector__XXX
 SG_ VFSSMdl2Dttr3DttrTp : 48|4@1+ (1,0) [0|15] "" Vector__XXX
 SG_ VFSSMdl2Dttr3DttrDtSLOT : 52|4@1+ (1,0) [0|15] "" Vector__XXX
 SG_ VFSSMdl2Dttr4DttrTp : 72|4@1+ (1,0) [0|15] "" Vector__XXX
 SG_ VFSSMdl2Dttr4DttrDtSLOT : 76|4@1+ (1,0) [0|15] "" Vector__XXX
 SG_ VFSSMdl2Dttr5DttrTp : 96|4@1+ (1,0) [0|15] "" Vector__XXX
 SG_ VFSSMdl2Dttr5DttrDtSLOT : 100|4@1+ (1,0) [0|15] "" Vector__XXX
 SG_ VFSSMdl2Dttr6DttrTp : 120|4@1+ (1,0) [0|15] "" Vector__XXX
 SG_ VFSSMdl2Dttr6DttrDtSLOT : 124|4@1+ (1,0) [0|15] "" Vector__XXX
 SG_ VFSSMdl2Dttr7DttrTp : 144|4@1+ (1,0) [0|15] "" Vector__XXX
 SG_ VFSSMdl2Dttr7DttrDtSLOT : 148|4@1+ (1,0) [0|15] "" Vector__XXX
 SG_ VFSSMdl2Dttr8DttrTp : 168|4@1+ (1,0) [0|15] "" Vector__XXX
 SG_ VFSSMdl2Dttr8DttrDtSLOT : 172|4@1+ (1,0) [0|15] "" Vector__XXX

BO_ 2633719294 VFSSM3DET: 24 Vector__XXX
 SG_ VFSSMdl3Dttr1DttrTp : 0|4@1+ (1,0) [0|15] "" Vector__XXX
 SG_ VFSSMdl3Dttr1DttrDtSLOT : 4|4@1+ (1,0) [0|15] "" Vector__XXX
 SG_ VFSSMdl3Dttr2DttrTp : 24|4@1+ (1,0) [0|15] "" Vector__XXX
 SG_ VFSSMdl3Dttr2DttrDtSLOT : 28|4@1+ (1,0) [0|15] "" Vector__XXX
 SG_ VFSSMdl3Dttr3DttrTp : 48|4@1+ (1,0) [0|15] "" Vector__XXX
 SG_ VFSSMdl3Dttr3DttrDtSLOT : 52|4@1+ (1,0) [0|15] "" Vector__XXX
 SG_ VFSSMdl3Dttr4DttrTp : 72|4@1+ (1,0) [0|15] "" Vector__XXX
 SG_ VFSSMdl3Dttr4DttrDtSLOT : 76|4@1+ (1,0) [0|15] "" Vector__XXX
 SG_ VFSSMdl3Dttr5DttrTp : 96|4@1+ (1,0) [0|15] "" Vector__XXX
 SG_ VFSSMdl3Dttr5DttrDtSLOT : 100|4@1+ (1,0) [0|15] "" Vector__XXX
 SG_ VFSSMdl3Dttr6DttrTp : 120|4@1+ (1,0) [0|15] "" Vector__XXX
 SG_ VFSSMdl3Dttr6DttrDtSLOT : 124|4@1+ (1,0) [0|15] "" Vector__XXX
 SG_ VFSSMdl3Dttr7DttrTp : 144|4@1+ (1,0) [0|15] "" Vector__XXX
 SG_ VFSSMdl3Dttr7DttrDtSLOT : 148|4@1+ (1,0) [0|15] "" Vector__XXX
 SG_ VFSSMdl3Dttr8DttrTp : 168|4@1+ (1,0) [0|15] "" Vector__XXX
 SG_ VFSSMdl3Dttr8DttrDtSLOT : 172|4@1+ (1,0) [0|15] "" Vector__XXX

BO_ 2633719550 VFSSM4DET: 24 Vector__XXX
 SG_ VFSSMdl4Dttr1DttrTp : 0|4@1+ (1,0) [0|15] "" Vector__XXX
 SG_ VFSSMdl4Dttr1DttrDtSLOT : 4|4@1+ (1,0) [0|15] "" Vector__XXX
 SG_ VFSSMdl4Dttr2DttrTp : 24|4@1+ (1,0) [0|15] "" Vector__XXX
 SG_ VFSSMdl4Dttr2DttrDtSLOT : 28|4@1+ (1,0) [0|15] "" Vector__XXX
 SG_ VFSSMdl4Dttr3DttrTp : 48|4@1+ (1,0) [0|15] "" Vector__XXX
 SG_ VFSSMdl4Dttr3DttrDtSLOT : 52|4@1+ (1,0) [0|15] "" Vector__XXX
 SG_ VFSSMdl4Dttr4DttrTp : 72|4@1+ (1,0) [0|15] "" Vector__XXX
 SG_ VFSSMdl4Dttr4DttrDtSLOT : 76|4@1+ (1,0) [0|15] "" Vector__XXX
 SG_ VFSSMdl4Dttr5DttrTp : 96|4@1+ (1,0) [0|15] "" Vector__XXX
 SG_ VFSSMdl4Dttr5DttrDtSLOT : 100|4@1+ (1,0) [0|15] "" Vector__XXX
 SG_ VFSSMdl4Dttr6DttrTp : 120|4@1+ (1,0) [0|15] "" Vector__XXX
 SG_ VFSSMdl4Dttr6DttrDtSLOT : 124|4@1+ (1,0) [0|15] "" Vector__XXX
 SG_ VFSSMdl4Dttr7DttrTp : 144|4@1+ (1,0) [0|15] "" Vector__XXX
 SG_ VFSSMdl4Dttr7DttrDtSLOT : 148|4@1+ (1,0) [0|15] "" Vector__XXX
 SG_ VFSSMdl4Dttr8DttrTp : 168|4@1+ (1,0) [0|15] "" Vector__XXX
 SG_ VFSSMdl4Dttr8DttrDtSLOT : 172|4@1+ (1,0) [0|15] "" Vector__XXX

BO_ 2633719806 VFSSM1AUX: 16 Vector__XXX
 SG_ VFSSModule1HeatZone1Data : 0|16@1+ (0.01,0) [0|642.55] "V" Vector__XXX
 SG_ VFSSModule1HeatZone2Data : 16|16@1+ (0.01,0) [0|642.55] "V" Vector__XXX
 SG_ VFSSModule1ReleaseZone1Data : 32|16@1+ (0.01,0) [0|642.55] "V" Vector__XXX
 SG_ VFSSModule1ReleaseZone2Data : 48|16@1+ (0.01,0) [0|642.55] "V" Vector__XXX
 SG_ VFSSModule1PressureSwitch1Data : 64|16@1+ (0.01,0) [0|642.55] "V" Vector__XXX
 SG_ VFSSModule1PressureSwitch2Data : 80|16@1+ (0.01,0) [0|642.55] "V" Vector__XXX
 SG_ VFSSModule1PrimaryPowerVoltage : 96|16@1+ (0.01,0) [0|642.55] "V" Vector__XXX
 SG_ VFSSMdl1SndrPwrVltg : 112|16@1+ (0.01,0) [0|642.55] "V" Vector__XXX

BO_ 2633720062 VFSSM2AUX: 16 Vector__XXX
 SG_ VFSSModule2HeatZone1Data : 0|16@1+ (0.01,0) [0|642.55] "V" Vector__XXX
 SG_ VFSSModule2HeatZone2Data : 16|16@1+ (0.01,0) [0|642.55] "V" Vector__XXX
 SG_ VFSSModule2ReleaseZone1Data : 32|16@1+ (0.01,0) [0|642.55] "V" Vector__XXX
 SG_ VFSSModule2ReleaseZone2Data : 48|16@1+ (0.01,0) [0|642.55] "V" Vector__XXX
 SG_ VFSSModule2PressureSwitch1Data : 64|16@1+ (0.01,0) [0|642.55] "V" Vector__XXX
 SG_ VFSSModule2PressureSwitch2Data : 80|16@1+ (0.01,0) [0|642.55] "V" Vector__XXX
 SG_ VFSSModule2PrimaryPowerVoltage : 96|16@1+ (0.01,0) [0|642.55] "V" Vector__XXX
 SG_ VFSSMdl2SndrPwrVltg : 112|16@1+ (0.01,0) [0|642.55] "V" Vector__XXX

BO_ 2633720318 VFSSM3AUX: 16 Vector__XXX
 SG_ VFSSModule3HeatZone1Data : 0|16@1+ (0.01,0) [0|642.55] "V" Vector__XXX
 SG_ VFSSModule3HeatZone2Data : 16|16@1+ (0.01,0) [0|642.55] "V" Vector__XXX
 SG_ VFSSModule3ReleaseZone1Data : 32|16@1+ (0.01,0) [0|642.55] "V" Vector__XXX
 SG_ VFSSModule3ReleaseZone2Data : 48|16@1+ (0.01,0) [0|642.55] "V" Vector__XXX
 SG_ VFSSModule3PressureSwitch1Data : 64|16@1+ (0.01,0) [0|642.55] "V" Vector__XXX
 SG_ VFSSModule3PressureSwitch2Data : 80|16@1+ (0.01,0) [0|642.55] "V" Vector__XXX
 SG_ VFSSModule3PrimaryPowerVoltage : 96|16@1+ (0.01,0) [0|642.55] "V" Vector__XXX
 SG_ VFSSMdl3SndrPwrVltg : 112|16@1+ (0.01,0) [0|642.55] "V" Vector__XXX

BO_ 2633720574 VFSSM4AUX: 16 Vector__XXX
 SG_ VFSSModule4HeatZone1Data : 0|16@1+ (0.01,0) [0|642.55] "V" Vector__XXX
 SG_ VFSSModule4HeatZone2Data : 16|16@1+ (0.01,0) [0|642.55] "V" Vector__XXX
 SG_ VFSSModule4ReleaseZone1Data : 32|16@1+ (0.01,0) [0|642.55] "V" Vector__XXX
 SG_ VFSSModule4ReleaseZone2Data : 48|16@1+ (0.01,0) [0|642.55] "V" Vector__XXX
 SG_ VFSSModule4PressureSwitch1Data : 64|16@1+ (0.01,0) [0|642.55] "V" Vector__XXX
 SG_ VFSSModule4PressureSwitch2Data : 80|16@1+ (0.01,0) [0|642.55] "V" Vector__XXX
 SG_ VFSSModule4PrimaryPowerVoltage : 96|16@1+ (0.01,0) [0|642.55] "V" Vector__XXX
 SG_ VFSSMdl4SndrPwrVltg : 112|16@1+ (0.01,0) [0|642.55] "V" Vector__XXX

BO_ 2633720830 VFSSM1NAMES: 104 Vector__XXX
 SG_ VFSSModule1Name : 0|64@1+ (1,0) [0|255] "ASCII" Vector__XXX
 SG_ VFSSModule1DetectorZone1Name : 64|64@1+ (1,0) [0|255] "ASCII" Vector__XXX
 SG_ VFSSModule1DetectorZone2Name : 128|64@1+ (1,0) [0|255] "ASCII" Vector__XXX
 SG_ VFSSModule1DetectorZone3Name : 192|64@1+ (1,0) [0|255] "ASCII" Vector__XXX
 SG_ VFSSModule1DetectorZone4Name : 256|64@1+ (1,0) [0|255] "ASCII" Vector__XXX
 SG_ VFSSModule1DetectorZone5Name : 320|64@1+ (1,0) [0|255] "ASCII" Vector__XXX
 SG_ VFSSModule1DetectorZone6Name : 384|64@1+ (1,0) [0|255] "ASCII" Vector__XXX
 SG_ VFSSModule1DetectorZone7Name : 448|64@1+ (1,0) [0|255] "ASCII" Vector__XXX
 SG_ VFSSModule1DetectorZone8Name : 512|64@1+ (1,0) [0|255] "ASCII" Vector__XXX
 SG_ VFSSModule1HeatZone1Name : 576|64@1+ (1,0) [0|255] "ASCII" Vector__XXX
 SG_ VFSSModule1HeatZone2Name : 640|64@1+ (1,0) [0|255] "ASCII" Vector__XXX
 SG_ VFSSModule1ReleaseZone1Name : 704|64@1+ (1,0) [0|255] "ASCII" Vector__XXX
 SG_ VFSSModule1ReleaseZone2Name : 768|64@1+ (1,0) [0|255] "ASCII" Vector__XXX

BO_ 2633721086 VFSSM2NAMES: 104 Vector__XXX
 SG_ VFSSModule2Name : 0|64@1+ (1,0) [0|255] "ASCII" Vector__XXX
 SG_ VFSSModule2DetectorZone1Name : 64|64@1+ (1,0) [0|255] "ASCII" Vector__XXX
 SG_ VFSSModule2DetectorZone2Name : 128|64@1+ (1,0) [0|255] "ASCII" Vector__XXX
 SG_ VFSSModule2DetectorZone3Name : 192|64@1+ (1,0) [0|255] "ASCII" Vector__XXX
 SG_ VFSSModule2DetectorZone4Name : 256|64@1+ (1,0) [0|255] "ASCII" Vector__XXX
 SG_ VFSSModule2DetectorZone5Name : 320|64@1+ (1,0) [0|255] "ASCII" Vector__XXX
 SG_ VFSSModule2DetectorZone6Name : 384|64@1+ (1,0) [0|255] "ASCII" Vector__XXX
 SG_ VFSSModule2DetectorZone7Name : 448|64@1+ (1,0) [0|255] "ASCII" Vector__XXX
 SG_ VFSSModule2DetectorZone8Name : 512|64@1+ (1,0) [0|255] "ASCII" Vector__XXX
 SG_ VFSSModule2HeatZone1Name : 576|64@1+ (1,0) [0|255] "ASCII" Vector__XXX
 SG_ VFSSModule2HeatZone2Name : 640|64@1+ (1,0) [0|255] "ASCII" Vector__XXX
 SG_ VFSSModule2ReleaseZone1Name : 704|64@1+ (1,0) [0|255] "ASCII" Vector__XXX
 SG_ VFSSModule2ReleaseZone2Name : 768|64@1+ (1,0) [0|255] "ASCII" Vector__XXX

BO_ 2633721342 VFSSM3NAMES: 104 Vector__XXX
 SG_ VFSSModule3Name : 0|64@1+ (1,0) [0|255] "ASCII" Vector__XXX
 SG_ VFSSModule3DetectorZone1Name : 64|64@1+ (1,0) [0|255] "ASCII" Vector__XXX
 SG_ VFSSModule3DetectorZone2Name : 128|64@1+ (1,0) [0|255] "ASCII" Vector__XXX
 SG_ VFSSModule3DetectorZone3Name : 192|64@1+ (1,0) [0|255] "ASCII" Vector__XXX
 SG_ VFSSModule3DetectorZone4Name : 256|64@1+ (1,0) [0|255] "ASCII" Vector__XXX
 SG_ VFSSModule3DetectorZone5Name : 320|64@1+ (1,0) [0|255] "ASCII" Vector__XXX
 SG_ VFSSModule3DetectorZone6Name : 384|64@1+ (1,0) [0|255] "ASCII" Vector__XXX
 SG_ VFSSModule3DetectorZone7Name : 448|64@1+ (1,0) [0|255] "ASCII" Vector__XXX
 SG_ VFSSModule3DetectorZone8Name : 512|64@1+ (1,0) [0|255] "ASCII" Vector__XXX
 SG_ VFSSModule3HeatZone1Name : 576|64@1+ (1,0) [0|255] "ASCII" Vector__XXX
 SG_ VFSSModule3HeatZone2Name : 640|64@1+ (1,0) [0|255] "ASCII" Vector__XXX
 SG_ VFSSModule3ReleaseZone1Name : 704|64@1+ (1,0) [0|255] "ASCII" Vector__XXX
 SG_ VFSSModule3ReleaseZone2Name : 768|64@1+ (1,0) [0|255] "ASCII" Vector__XXX

BO_ 2633721598 VFSSM4NAMES: 104 Vector__XXX
 SG_ VFSSModule4Name : 0|64@1+ (1,0) [0|255] "ASCII" Vector__XXX
 SG_ VFSSModule4DetectorZone1Name : 64|64@1+ (1,0) [0|255] "ASCII" Vector__XXX
 SG_ VFSSModule4DetectorZone2Name : 128|64@1+ (1,0) [0|255] "ASCII" Vector__XXX
 SG_ VFSSModule4DetectorZone3Name : 192|64@1+ (1,0) [0|255] "ASCII" Vector__XXX
 SG_ VFSSModule4DetectorZone4Name : 256|64@1+ (1,0) [0|255] "ASCII" Vector__XXX
 SG_ VFSSModule4DetectorZone5Name : 320|64@1+ (1,0) [0|255] "ASCII" Vector__XXX
 SG_ VFSSModule4DetectorZone6Name : 384|64@1+ (1,0) [0|255] "ASCII" Vector__XXX
 SG_ VFSSModule4DetectorZone7Name : 448|64@1+ (1,0) [0|255] "ASCII" Vector__XXX
 SG_ VFSSModule4DetectorZone8Name : 512|64@1+ (1,0) [0|255] "ASCII" Vector__XXX
 SG_ VFSSModule4HeatZone1Name : 576|64@1+ (1,0) [0|255] "ASCII" Vector__XXX
 SG_ VFSSModule4HeatZone2Name : 640|64@1+ (1,0) [0|255] "ASCII" Vector__XXX
 SG_ VFSSModule4ReleaseZone1Name : 704|64@1+ (1,0) [0|255] "ASCII" Vector__XXX
 SG_ VFSSModule4ReleaseZone2Name : 768|64@1+ (1,0) [0|255] "ASCII" Vector__XXX

BO_ 2566612990 MG2IAPL: 8 Vector__XXX
 SG_ MtGt2IvtPwLtddtUddRs : 0|2@1+ (1,0) [0|3] "" Vector__XXX
 SG_ MtGt2IvtPwLtddtDCSdCtMx : 2|2@1+ (1,0) [0|3] "" Vector__XXX
 SG_ MtGt2IvtPwLtddtDCSdCtM : 4|2@1+ (1,0) [0|3] "" Vector__XXX
 SG_ MtGt2IvtPwLtddtDCSdVtMx : 6|2@1+ (1,0) [0|3] "" Vector__XXX
 SG_ MtGt2IvtPwLtddtDCSdVtM : 8|2@1+ (1,0) [0|3] "" Vector__XXX
 SG_ MtGt2IvtPwLtddtMPwMx : 10|2@1+ (1,0) [0|3] "" Vector__XXX
 SG_ MtGt2IvtPwLtddtMPwM : 12|2@1+ (1,0) [0|3] "" Vector__XXX
 SG_ MtGt2IvtPwLtddtDCSdPwMx : 14|2@1+ (1,0) [0|3] "" Vector__XXX
 SG_ MtGt2IvtPwLtddtDCSdPwM : 16|2@1+ (1,0) [0|3] "" Vector__XXX
 SG_ MtrGnrtr2InvrtrPwrLmtddtTrqMxmm : 18|2@1+ (1,0) [0|3] "" Vector__XXX
 SG_ MtrGnrtr2InvrtrPwrLmtddtTrqMnmm : 20|2@1+ (1,0) [0|3] "" Vector__XXX
 SG_ MtrGnrtr2InvrtrPwrLmtddtSpdMxmm : 22|2@1+ (1,0) [0|3] "" Vector__XXX
 SG_ MtrGnrtr2InvrtrPwrLmtddtSpdMnmm : 24|2@1+ (1,0) [0|3] "" Vector__XXX
 SG_ MtGt2IvtPwLtddtIvtTpt : 28|2@1+ (1,0) [0|3] "" Vector__XXX
 SG_ MtGt2IvtPwLtddtMtTpt : 30|2@1+ (1,0) [0|3] "" Vector__XXX

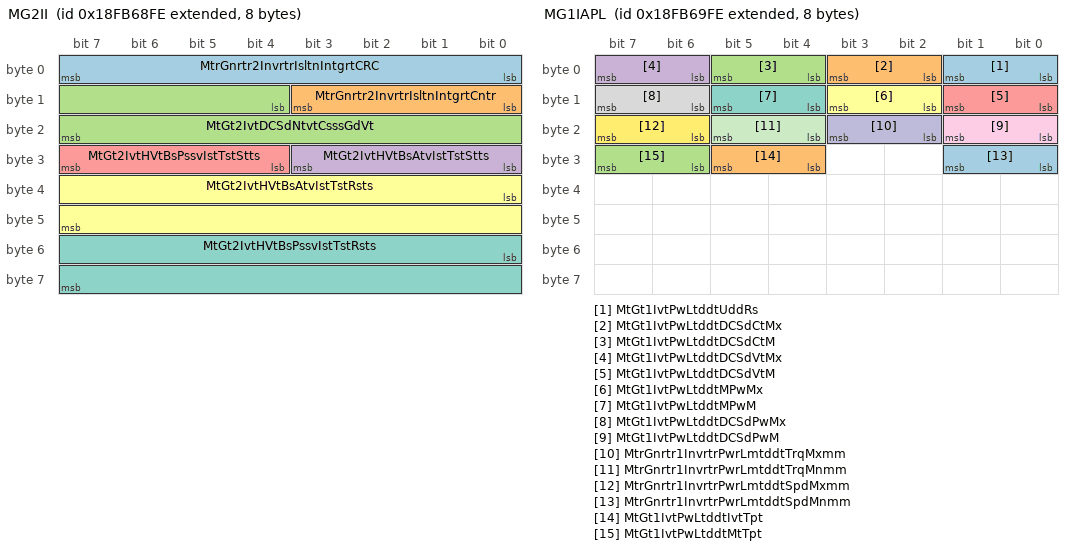
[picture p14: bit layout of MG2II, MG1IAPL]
BO_ 2566613246 MG2II: 8 Vector__XXX
 SG_ MtrGnrtr2InvrtrIsltnIntgrtCRC : 0|8@1+ (1,0) [0|255] "count" Vector__XXX
 SG_ MtrGnrtr2InvrtrIsltnIntgrtCntr : 8|4@1+ (1,0) [0|15] "" Vector__XXX
 SG_ MtGt2IvtDCSdNtvtCsssGdVt : 12|12@1+ (42370,-125) [-125|125.9375] "%" Vector__XXX
 SG_ MtGt2IvtHVtBsAtvIstTstStts : 24|4@1+ (1,0) [0|15] "" Vector__XXX
 SG_ MtGt2IvtHVtBsPssvIstTstStts : 28|4@1+ (1,0) [0|15] "" Vector__XXX
 SG_ MtGt2IvtHVtBsAtvIstTstRsts : 32|16@1+ (0.1,0) [0|6425.5] "ohm/V" Vector__XXX
 SG_ MtGt2IvtHVtBsPssvIstTstRsts : 48|16@1+ (0.1,0) [0|6425.5] "ohm/V" Vector__XXX

BO_ 2566613502 MG1IAPL: 8 Vector__XXX
 SG_ MtGt1IvtPwLtddtUddRs : 0|2@1+ (1,0) [0|3] "" Vector__XXX
 SG_ MtGt1IvtPwLtddtDCSdCtMx : 2|2@1+ (1,0) [0|3] "" Vector__XXX
 SG_ MtGt1IvtPwLtddtDCSdCtM : 4|2@1+ (1,0) [0|3] "" Vector__XXX
 SG_ MtGt1IvtPwLtddtDCSdVtMx : 6|2@1+ (1,0) [0|3] "" Vector__XXX
 SG_ MtGt1IvtPwLtddtDCSdVtM : 8|2@1+ (1,0) [0|3] "" Vector__XXX
 SG_ MtGt1IvtPwLtddtMPwMx : 10|2@1+ (1,0) [0|3] "" Vector__XXX
 SG_ MtGt1IvtPwLtddtMPwM : 12|2@1+ (1,0) [0|3] "" Vector__XXX
 SG_ MtGt1IvtPwLtddtDCSdPwMx : 14|2@1+ (1,0) [0|3] "" Vector__XXX
 SG_ MtGt1IvtPwLtddtDCSdPwM : 16|2@1+ (1,0) [0|3] "" Vector__XXX
 SG_ MtrGnrtr1InvrtrPwrLmtddtTrqMxmm : 18|2@1+ (1,0) [0|3] "" Vector__XXX
 SG_ MtrGnrtr1InvrtrPwrLmtddtTrqMnmm : 20|2@1+ (1,0) [0|3] "" Vector__XXX
 SG_ MtrGnrtr1InvrtrPwrLmtddtSpdMxmm : 22|2@1+ (1,0) [0|3] "" Vector__XXX
 SG_ MtrGnrtr1InvrtrPwrLmtddtSpdMnmm : 24|2@1+ (1,0) [0|3] "" Vector__XXX
 SG_ MtGt1IvtPwLtddtIvtTpt : 28|2@1+ (1,0) [0|3] "" Vector__XXX
 SG_ MtGt1IvtPwLtddtMtTpt : 30|2@1+ (1,0) [0|3] "" Vector__XXX

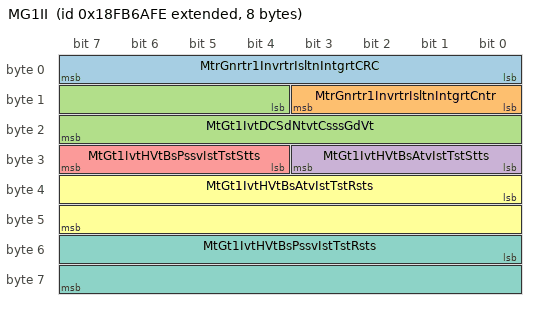
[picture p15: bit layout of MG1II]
BO_ 2566613758 MG1II: 8 Vector__XXX
 SG_ MtrGnrtr1InvrtrIsltnIntgrtCRC : 0|8@1+ (1,0) [0|255] "count" Vector__XXX
 SG_ MtrGnrtr1InvrtrIsltnIntgrtCntr : 8|4@1+ (1,0) [0|15] "" Vector__XXX
 SG_ MtGt1IvtDCSdNtvtCsssGdVt : 12|12@1+ (42370,-125) [-125|125.9375] "%" Vector__XXX
 SG_ MtGt1IvtHVtBsAtvIstTstStts : 24|4@1+ (1,0) [0|15] "" Vector__XXX
 SG_ MtGt1IvtHVtBsPssvIstTstStts : 28|4@1+ (1,0) [0|15] "" Vector__XXX
 SG_ MtGt1IvtHVtBsAtvIstTstRsts : 32|16@1+ (0.1,0) [0|6425.5] "ohm/V" Vector__XXX
 SG_ MtGt1IvtHVtBsPssvIstTstRsts : 48|16@1+ (0.1,0) [0|6425.5] "ohm/V" Vector__XXX

BO_ 2566614014 HVBI: 8 Vector__XXX
 SG_ HighVoltageDCBusAvailability : 0|4@1+ (1,0) [0|15] "" Vector__XXX

CM_ BO_ 2365272574 "Motor/Generator 6 Inverter Reference 2";
CM_ SG_ 2365272574 MtrGnrtr6InvrtrRfrn2CRC "Motor/Generator 6 Inverter Reference 2 CRC: The CRC is defined as follows: • Length: 8 bits • Polynomial: x^8+x^5+x^3+x^2+x+1 • Initial Value: FFh • Input Data Reflection: Not reflected • Result Data Reflection: Not reflected • XOR value: FFhSAE make...";
CM_ SG_ 2365272574 MtrGnrtr6InvrtrRfrn2Cntr "Motor/Generator 6 Inverter Reference 2 Counter: The message counter is used to detect situations where the transmitting ECU malfunction repeats the same frame all the time. The receiver of the information may use the counter parameter to detect this ...";
CM_ SG_ 2365272574 MtrGnrtr6InvrtrRfrnCrrnt "Motor/Generator 6 Inverter Reference Current: This value is used for converting inverter current in percent to units of Amps (RMS or DC).(Value in Amps) = (Percent Value)/(100%) * (Reference Current)For example, if this parameter has a value of 200 A...";
CM_ SG_ 2365272574 MtrGnrtr6InvrtrRfrnVltg "Motor/Generator 6 Inverter Reference Voltage: This value is used for converting inverter voltage in percent to units of Volts (RMS or DC).(Value in Volts) = (Percent Value)/(100%) * (Reference Voltage)For example, if this parameter has a value of 400...";
CM_ BO_ 2566599422 "Motor/Generator 6 Inverter Temperature";
CM_ SG_ 2566599422 MtrGnrtr6InvrtrTmprtr1 "Motor/Generator 6 Inverter Temperature 1: The exact location of this temperature can be defined by the manufacturer.  It is intended to be located somewhere on the inverter. ";
CM_ SG_ 2566599422 MtrGnrtr6InvrtrTmprtr2 "Motor/Generator 6 Inverter Temperature 2: The exact location of this temperature can be defined by the manufacturer.  It is intended to be located somewhere on the inverter. ";
CM_ SG_ 2566599422 MtrGnrtr6InvrtrTmprtr3 "Motor/Generator 6 Inverter Temperature 3: The exact location of this temperature can be defined by the manufacturer.  It is intended to be located somewhere on the inverter. ";
CM_ SG_ 2566599422 MtrGnrtr6InvrtrTmprtr4 "Motor/Generator 6 Inverter Temperature 4: The exact location of this temperature can be defined by the manufacturer.  It is intended to be located somewhere on the inverter. ";
CM_ BO_ 2566599678 "Motor/Generator 6 Inverter Motor Temperature";
CM_ SG_ 2566599678 MotorGenerator6Temperature1 "Motor/Generator 6 Temperature 1: The exact location of this temperature can be defined by the manufacturer.  It is intended to located somewhere on the motor.";
CM_ SG_ 2566599678 MotorGenerator6Temperature2 "Motor/Generator 6 Temperature 2: The exact location of this temperature can be defined by the manufacturer.  It is intended to located somewhere on the motor. ";
CM_ SG_ 2566599678 MotorGenerator6Temperature3 "Motor/Generator 6 Temperature 3: The exact location of this temperature can be defined by the manufacturer.  It is intended to located somewhere on the motor. ";
CM_ SG_ 2566599678 MotorGenerator6Temperature4 "Motor/Generator 6 Temperature 4: The exact location of this temperature can be defined by the manufacturer.  It is intended to located somewhere on the motor. ";
CM_ BO_ 2566599934 "Motor/Generator 6 Inverter Isolation Integrity";
CM_ SG_ 2566599934 MtrGnrtr6InvrtrIsltnIntgrtCRC "Motor/Generator 6 Inverter Isolation Integrity CRC: The CRC is defined as follows:• Length: 8 bits• Polynomial: x^8+x^5+x^3+x^2+x+1• Initial Value: FFh• Input Data Reflection: Not reflected• Result Data Reflection: Not reflected• XOR value: FFhSAE ma...";
CM_ SG_ 2566599934 MtrGnrtr6InvrtrIsltnIntgrtCntr "Motor/Generator 6 Inverter Isolation Integrity Counter: The message counter is used to detect situations where the transmitting ECU malfunction repeats the same frame all the time. The receiver of the information may use the counter parameter to dete...";
CM_ SG_ 2566599934 MtGt6IvtDCSdNtvtCsssGdVt "Motor/Generator 6 Inverter DC Side Negative to Chassis Ground Voltage: The voltage level of the high voltage DC side, as measured by the inverter between the negative side of the High Voltage DC Side input and the chassis of the inverter enclosure.  ...";
CM_ SG_ 2566599934 MtGt6IvtHVtBsAtvIstTstStts "Motor/Generator 6 Inverter High-Voltage Bus Active Isolation Test Status: Status of the high-voltage bus electrical active isolation test as performed by this instance of the Motor/Generator.0000b = No test requested / No test in process0001b = Test ...";
CM_ SG_ 2566599934 MtGt6IvtHVtBsPssvIstTstStts "Motor/Generator 6 Inverter High-Voltage Bus Passive Isolation Test Status: Status of the high-voltage bus electrical passive isolation test as performed by this instance of the Motor/Generator.0000b = No test requested / No test in process0001b = Tes...";
CM_ SG_ 2566599934 MtGt6IvtHVtBsAtvIstTstRsts "Motor/Generator 6 Inverter High-Voltage Bus Active Isolation Test Results: The isolation resistance that resulted from the High-Voltage Bus Active Isolation Test.See SPN 12239 [High-Voltage Bus Active Isolation Test Status] for test status and SPN 12...";
CM_ SG_ 2566599934 MtGt6IvtHVtBsPssvIstTstRsts "Motor/Generator 6 Inverter High-Voltage Bus Passive Isolation Test Results: The isolation resistance that resulted from the High-Voltage Bus Passive Isolation Test.See SPN 12240 [High-Voltage Bus Passive Isolation Test Status] for test status and SPN...";
CM_ BO_ 2566600190 "Motor/Generator 6 Inverter Active Power Limits";
CM_ SG_ 2566600190 MtGt6IvtPwLtddtUddRs "Motor/Generator 6 Inverter Power Limited due to Undefined Reason: Output power is being limited due to an undefined reason.00b = No power limit for this reason01b = Power limited for this reason10b = Error11b = Not Available";
CM_ SG_ 2566600190 MtGt6IvtPwLtddtDCSdCtMx "Motor/Generator 6 Inverter Power Limited due to DC Side Current Maximum: Output power is being limited due to SPN 12180 [Inverter DC Side Current] approaching or exceeding the SPN 12219 [Inverter Limits Active DC Side Current Maximum].00b = No power ...";
CM_ SG_ 2566600190 MtGt6IvtPwLtddtDCSdCtM "Motor/Generator 6 Inverter Power Limited due to DC Side Current Minimum: Output power is being limited due to SPN 12180 [Inverter DC Side Current] approaching or falling below the SPN 12220 [Inverter Limits Active DC Side Current Minimum].00b = No po...";
CM_ SG_ 2566600190 MtGt6IvtPwLtddtDCSdVtMx "Motor/Generator 6 Inverter Power Limited due to DC Side Voltage Maximum: Output power is being limited due to SPN 12158 [Inverter DC Side Voltage] approaching or exceeding the SPN 12217 [Inverter Limits Active DC Side Voltage Maximum].00b = No power ...";
CM_ SG_ 2566600190 MtGt6IvtPwLtddtDCSdVtM "Motor/Generator 6 Inverter Power Limited due to DC Side Voltage Minimum: Output power is being limited due to SPN 12158 [Inverter DC Side Voltage] approaching or falling below the SPN 12218 [Inverter Limits Active DC Side Voltage Minimum].00b = No po...";
CM_ SG_ 2566600190 MtGt6IvtPwLtddtMPwMx "Motor/Generator 6 Inverter Power Limited due to Mechanical Power Maximum: Output power is being limited due to Mechanical Power (product of SPN 12157 [Torque] and SPN 12155 [Speed]) approaching or exceeding the SPN 12189 [Inverter Limits Active Mecha...";
CM_ SG_ 2566600190 MtGt6IvtPwLtddtMPwM "Motor/Generator 6 Inverter Power Limited due to Mechanical Power Minimum: Output power is being limited due to Mechanical Power (product of SPN 12157 [Torque] and SPN 12155 [Speed]) approaching or falling below the SPN 12190 [Inverter Limits Active M...";
CM_ SG_ 2566600190 MtGt6IvtPwLtddtDCSdPwMx "Motor/Generator 6 Inverter Power Limited due to DC Side Power Maximum: Output power is being limited due to DC Side Power (product of SPN 12180 [Inverter DC Side Current] and SPN 12158 [Inverter DC Side Voltage]) approaching or exceeding the SPN 1219...";
CM_ SG_ 2566600190 MtGt6IvtPwLtddtDCSdPwM "Motor/Generator 6 Inverter Power Limited due to DC Side Power Minimum: Output power is being limited due to DC Side Power (product of SPN 12180 [Inverter DC Side Current] and SPN 12158 [Inverter DC Side Voltage]) approaching or falling below the SPN ...";
CM_ SG_ 2566600190 MtrGnrtr6InvrtrPwrLmtddtTrqMxmm "Motor/Generator 6 Inverter Power Limited due to Torque Maximum: Output power is being limited due to SPN 12157 [Torque] approaching or exceeding the SPN 12201 [Inverter Limits Active Torque Maximum].00b = No power limit for this reason01b = Power lim...";
CM_ SG_ 2566600190 MtrGnrtr6InvrtrPwrLmtddtTrqMnmm "Motor/Generator 6 Inverter Power Limited due to Torque Minimum: Output power is being limited due to SPN 12157 [Torque] approaching or falling below the SPN 12202 [Inverter Limits Active Torque Minimum].00b = No power limit for this reason01b = Power...";
CM_ SG_ 2566600190 MtrGnrtr6InvrtrPwrLmtddtSpdMxmm "Motor/Generator 6 Inverter Power Limited due to Speed Maximum: Output power is being limited due to SPN 12155 [Speed] approaching or exceeding the SPN 12203 [Inverter Limits Active Speed Maximum].00b = No power limit for this reason01b = Power limite...";
CM_ SG_ 2566600190 MtrGnrtr6InvrtrPwrLmtddtSpdMnmm "Motor/Generator 6 Inverter Power Limited due to Speed Minimum: Output power is being limited due to SPN 12155 [Speed] approaching or falling below the SPN 12204 [Inverter Limits Active Speed Minimum].00b = No power limit for this reason01b = Power li...";
CM_ SG_ 2566600190 MtGt6IvtPwLtddtIvtTpt "Motor/Generator 6 Inverter Power Limited due to Inverter Temperature: Output power is being limited due to one or more inverter temperature(s), see SPNs 12221 through 12224 [Inverter Temperature 1-4] approaching or exceeding internally defined limit(...";
CM_ SG_ 2566600190 MtGt6IvtPwLtddtMtTpt "Motor/Generator 6 Inverter Power Limited due to Motor Temperature: Output power is being limited due to one or more motor temperature(s), see SPNs 12156 and 12225 through 12227 [Motor Temperature 1-4] approaching or exceeding internally defined limit...";
CM_ BO_ 2365273854 "Motor/Generator 5 Inverter Reference 1";
CM_ SG_ 2365273854 MtrGnrtr5InvrtrRfrn1CRC "Motor/Generator 5 Inverter Reference 1 CRC: The CRC is defined as follows: • Length: 8 bits • Polynomial: x^8+x^5+x^3+x^2+x+1 • Initial Value: FFh • Input Data Reflection: Not reflected • Result Data Reflection: Not reflected • XOR value: FFhSAE make...";
CM_ SG_ 2365273854 MtrGnrtr5InvrtrRfrn1Cntr "Motor/Generator 5 Inverter Reference 1 Counter: The message counter is used to detect situations where the transmitting ECU malfunction repeats the same frame all the time. The receiver of the information may use the counter parameter to detect this ...";
CM_ SG_ 2365273854 MtrGnrtr5InvrtrRfrnTrq "Motor/Generator 5 Inverter Reference Torque: This value is used for converting torque in percent to units of Nm.Value in Nm = (Percent Value)/(100%) * (Reference Torque)For example, if this parameter has a value of 400 Nm and the percent value is equ...";
CM_ SG_ 2365273854 MtrGnrtr5InvrtrRfrnSpd "Motor/Generator 5 Inverter Reference Speed: This value is used for converting Speed in percent to units of rpm.Value in rpm = (Percent Value)/(100%) * (Reference Speed)For example, if this parameter has a value of 8192 rpm and the percent value is eq...";
CM_ SG_ 2365273854 MtrGnrtr5InvrtrRfrnPwr "Motor/Generator 5 Inverter Reference Power: This value is used for converting power in percent to units of kW.  It is applicable to both mechanical and electrical power.(Value in kW) = (Percent Value)/(100%) * (Reference Power)For example, if this pa...";
CM_ BO_ 2365274110 "Motor/Generator 5 Inverter Status 1";
CM_ SG_ 2365274110 MtrGnrtr5InvrtrStts1CRC "Motor/Generator 5 Inverter Status 1 CRC: The CRC is defined as follows: • Length: 8 bits • Polynomial: x^8+x^5+x^3+x^2+x+1 • Initial Value: FFh • Input Data Reflection: Not reflected • Result Data Reflection: Not reflected • XOR value: FFhSAE makes n...";
CM_ SG_ 2365274110 MtrGnrtr5InvrtrStts1Cntr "Motor/Generator 5 Inverter Status 1 Counter: The message counter is used to detect situations where the transmitting ECU malfunction repeats the same frame all the time. The receiver of the information may use the counter parameter to detect this sit...";
CM_ SG_ 2365274110 MotorGenerator5Torque "Motor/Generator 5 Torque: The measured or estimated motor torque.  This refers to the motor rotor output and excludes any gearbox that may be attached to the motor.Refer to SPN 12057 [Reference Torque] to convert % to Nm.The motor is generating when ...";
CM_ SG_ 2365274110 MotorGenerator5Speed "Motor/Generator 5 Speed: The measured or estimated motor speed.  This refers to the motor rotor output and excludes any gearbox that may be attached to the motor.   Refer to SPN 12058 [Reference Speed] to convert % to rpm.";
CM_ SG_ 2365274110 MtrGnrtr5InvrtrDCSdCrrnt "Motor/Generator 5 Inverter DC Side Current: This is the DC side current of the inverter.Refer to SPN 12089 [Reference Current] to convert % to Amps.While motoring, the current is defined as positive.  For example, in a hybrid propulsion system, posit...";
CM_ SG_ 2365274110 MtrGnrtr5InvrtrDCSdVltg "Motor/Generator 5 Inverter DC Side Voltage: The measured or estimated DC side voltage.  Refer to SPN 12090 [Reference Voltage] to convert % to Volts.";
CM_ BO_ 2365274366 "Motor/Generator 5 Inverter Reference 2";
CM_ SG_ 2365274366 MtrGnrtr5InvrtrRfrn2CRC "Motor/Generator 5 Inverter Reference 2 CRC: The CRC is defined as follows: • Length: 8 bits • Polynomial: x^8+x^5+x^3+x^2+x+1 • Initial Value: FFh • Input Data Reflection: Not reflected • Result Data Reflection: Not reflected • XOR value: FFhSAE make...";
CM_ SG_ 2365274366 MtrGnrtr5InvrtrRfrn2Cntr "Motor/Generator 5 Inverter Reference 2 Counter: The message counter is used to detect situations where the transmitting ECU malfunction repeats the same frame all the time. The receiver of the information may use the counter parameter to detect this ...";
CM_ SG_ 2365274366 MtrGnrtr5InvrtrRfrnCrrnt "Motor/Generator 5 Inverter Reference Current: This value is used for converting inverter current in percent to units of Amps (RMS or DC).(Value in Amps) = (Percent Value)/(100%) * (Reference Current)For example, if this parameter has a value of 200 A...";
CM_ SG_ 2365274366 MtrGnrtr5InvrtrRfrnVltg "Motor/Generator 5 Inverter Reference Voltage: This value is used for converting inverter voltage in percent to units of Volts (RMS or DC).(Value in Volts) = (Percent Value)/(100%) * (Reference Voltage)For example, if this parameter has a value of 400...";
CM_ BO_ 2566601214 "Motor/Generator 5 Inverter Temperature";
CM_ SG_ 2566601214 MtrGnrtr5InvrtrTmprtr1 "Motor/Generator 5 Inverter Temperature 1: The exact location of this temperature can be defined by the manufacturer.  It is intended to be located somewhere on the inverter. ";
CM_ SG_ 2566601214 MtrGnrtr5InvrtrTmprtr2 "Motor/Generator 5 Inverter Temperature 2: The exact location of this temperature can be defined by the manufacturer.  It is intended to be located somewhere on the inverter. ";
CM_ SG_ 2566601214 MtrGnrtr5InvrtrTmprtr3 "Motor/Generator 5 Inverter Temperature 3: The exact location of this temperature can be defined by the manufacturer.  It is intended to be located somewhere on the inverter. ";
CM_ SG_ 2566601214 MtrGnrtr5InvrtrTmprtr4 "Motor/Generator 5 Inverter Temperature 4: The exact location of this temperature can be defined by the manufacturer.  It is intended to be located somewhere on the inverter. ";
CM_ BO_ 2566601470 "Motor/Generator 5 Inverter Motor Temperature";
CM_ SG_ 2566601470 MotorGenerator5Temperature1 "Motor/Generator 5 Temperature 1: The exact location of this temperature can be defined by the manufacturer.  It is intended to located somewhere on the motor.";
CM_ SG_ 2566601470 MotorGenerator5Temperature2 "Motor/Generator 5 Temperature 2: The exact location of this temperature can be defined by the manufacturer.  It is intended to located somewhere on the motor. ";
CM_ SG_ 2566601470 MotorGenerator5Temperature3 "Motor/Generator 5 Temperature 3: The exact location of this temperature can be defined by the manufacturer.  It is intended to located somewhere on the motor. ";
CM_ SG_ 2566601470 MotorGenerator5Temperature4 "Motor/Generator 5 Temperature 4: The exact location of this temperature can be defined by the manufacturer.  It is intended to located somewhere on the motor. ";
CM_ BO_ 2566601726 "Motor/Generator 5 Inverter Isolation Integrity";
CM_ SG_ 2566601726 MtrGnrtr5InvrtrIsltnIntgrtCRC "Motor/Generator 5 Inverter Isolation Integrity CRC: The CRC is defined as follows:• Length: 8 bits• Polynomial: x^8+x^5+x^3+x^2+x+1• Initial Value: FFh• Input Data Reflection: Not reflected• Result Data Reflection: Not reflected• XOR value: FFhSAE ma...";
CM_ SG_ 2566601726 MtrGnrtr5InvrtrIsltnIntgrtCntr "Motor/Generator 5 Inverter Isolation Integrity Counter: The message counter is used to detect situations where the transmitting ECU malfunction repeats the same frame all the time. The receiver of the information may use the counter parameter to dete...";
CM_ SG_ 2566601726 MtGt5IvtDCSdNtvtCsssGdVt "Motor/Generator 5 Inverter DC Side Negative to Chassis Ground Voltage: The voltage level of the high voltage DC side, as measured by the inverter between the negative side of the High Voltage DC Side input and the chassis of the inverter enclosure.  ...";
CM_ SG_ 2566601726 MtGt5IvtHVtBsAtvIstTstStts "Motor/Generator 5 Inverter High-Voltage Bus Active Isolation Test Status: Status of the high-voltage bus electrical active isolation test as performed by this instance of the Motor/Generator.0000b = No test requested / No test in process0001b = Test ...";
CM_ SG_ 2566601726 MtGt5IvtHVtBsPssvIstTstStts "Motor/Generator 5 Inverter High-Voltage Bus Passive Isolation Test Status: Status of the high-voltage bus electrical passive isolation test as performed by this instance of the Motor/Generator.0000b = No test requested / No test in process0001b = Tes...";
CM_ SG_ 2566601726 MtGt5IvtHVtBsAtvIstTstRsts "Motor/Generator 5 Inverter High-Voltage Bus Active Isolation Test Results: The isolation resistance that resulted from the High-Voltage Bus Active Isolation Test.See SPN 12121 [High-Voltage Bus Active Isolation Test Status] for test status and SPN 12...";
CM_ SG_ 2566601726 MtGt5IvtHVtBsPssvIstTstRsts "Motor/Generator 5 Inverter High-Voltage Bus Passive Isolation Test Results: The isolation resistance that resulted from the High-Voltage Bus Passive Isolation Test.See SPN 12122 [High-Voltage Bus Passive Isolation Test Status] for test status and SPN...";
CM_ BO_ 2566601982 "Motor/Generator 5 Inverter Active Power Limits";
CM_ SG_ 2566601982 MtGt5IvtPwLtddtUddRs "Motor/Generator 5 Inverter Power Limited due to Undefined Reason: Output power is being limited due to an undefined reason.00b = No power limit for this reason01b = Power limited for this reason10b = Error11b = Not Available";
CM_ SG_ 2566601982 MtGt5IvtPwLtddtDCSdCtMx "Motor/Generator 5 Inverter Power Limited due to DC Side Current Maximum: Output power is being limited due to SPN 12062 [Inverter DC Side Current] approaching or exceeding the SPN 12101 [Inverter Limits Active DC Side Current Maximum].00b = No power ...";
CM_ SG_ 2566601982 MtGt5IvtPwLtddtDCSdCtM "Motor/Generator 5 Inverter Power Limited due to DC Side Current Minimum: Output power is being limited due to SPN 12062 [Inverter DC Side Current] approaching or falling below the SPN 12102 [Inverter Limits Active DC Side Current Minimum].00b = No po...";
CM_ SG_ 2566601982 MtGt5IvtPwLtddtDCSdVtMx "Motor/Generator 5 Inverter Power Limited due to DC Side Voltage Maximum: Output power is being limited due to SPN 12040 [Inverter DC Side Voltage] approaching or exceeding the SPN 12099 [Inverter Limits Active DC Side Voltage Maximum].00b = No power ...";
CM_ SG_ 2566601982 MtGt5IvtPwLtddtDCSdVtM "Motor/Generator 5 Inverter Power Limited due to DC Side Voltage Minimum: Output power is being limited due to SPN 12040 [Inverter DC Side Voltage] approaching or falling below the SPN 12100 [Inverter Limits Active DC Side Voltage Minimum].00b = No po...";
CM_ SG_ 2566601982 MtGt5IvtPwLtddtMPwMx "Motor/Generator 5 Inverter Power Limited due to Mechanical Power Maximum: Output power is being limited due to Mechanical Power (product of SPN 12039 [Torque] and SPN 12037 [Speed]) approaching or exceeding the SPN 12071 [Inverter Limits Active Mecha...";
CM_ SG_ 2566601982 MtGt5IvtPwLtddtMPwM "Motor/Generator 5 Inverter Power Limited due to Mechanical Power Minimum: Output power is being limited due to Mechanical Power (product of SPN 12039 [Torque] and SPN 12037 [Speed]) approaching or falling below the SPN 12072 [Inverter Limits Active M...";
CM_ SG_ 2566601982 MtGt5IvtPwLtddtDCSdPwMx "Motor/Generator 5 Inverter Power Limited due to DC Side Power Maximum: Output power is being limited due to DC Side Power (product of SPN 12062 [Inverter DC Side Current] and SPN 12040 [Inverter DC Side Voltage]) approaching or exceeding the SPN 1207...";
CM_ SG_ 2566601982 MtGt5IvtPwLtddtDCSdPwM "Motor/Generator 5 Inverter Power Limited due to DC Side Power Minimum: Output power is being limited due to DC Side Power (product of SPN 12062 [Inverter DC Side Current] and SPN 12040 [Inverter DC Side Voltage]) approaching or falling below the SPN ...";
CM_ SG_ 2566601982 MtrGnrtr5InvrtrPwrLmtddtTrqMxmm "Motor/Generator 5 Inverter Power Limited due to Torque Maximum: Output power is being limited due to SPN 12039 [Torque] approaching or exceeding the SPN 12083 [Inverter Limits Active Torque Maximum].00b = No power limit for this reason01b = Power lim...";
CM_ SG_ 2566601982 MtrGnrtr5InvrtrPwrLmtddtTrqMnmm "Motor/Generator 5 Inverter Power Limited due to Torque Minimum: Output power is being limited due to SPN 12039 [Torque] approaching or falling below the SPN 12084 [Inverter Limits Active Torque Minimum].00b = No power limit for this reason01b = Power...";
CM_ SG_ 2566601982 MtrGnrtr5InvrtrPwrLmtddtSpdMxmm "Motor/Generator 5 Inverter Power Limited due to Speed Maximum: Output power is being limited due to SPN 12037 [Speed] approaching or exceeding the SPN 12085 [Inverter Limits Active Speed Maximum].00b = No power limit for this reason01b = Power limite...";
CM_ SG_ 2566601982 MtrGnrtr5InvrtrPwrLmtddtSpdMnmm "Motor/Generator 5 Inverter Power Limited due to Speed Minimum: Output power is being limited due to SPN 12037 [Speed] approaching or falling below the SPN 12086 [Inverter Limits Active Speed Minimum].00b = No power limit for this reason01b = Power li...";
CM_ SG_ 2566601982 MtGt5IvtPwLtddtIvtTpt "Motor/Generator 5 Inverter Power Limited due to Inverter Temperature: Output power is being limited due to one or more inverter temperature(s), see SPNs 12103 through 12106 [Inverter Temperature 1-4] approaching or exceeding internally defined limit(...";
CM_ SG_ 2566601982 MtGt5IvtPwLtddtMtTpt "Motor/Generator 5 Inverter Power Limited due to Motor Temperature: Output power is being limited due to one or more motor temperature(s), see SPNs 12038 and 12107 through 12109 [Motor Temperature 1-4] approaching or exceeding internally defined limit...";
CM_ BO_ 2365275646 "Motor/Generator 4 Inverter Reference 1";
CM_ SG_ 2365275646 MtrGnrtr4InvrtrRfrn1CRC "Motor/Generator 4 Inverter Reference 1 CRC: The CRC is defined as follows: • Length: 8 bits • Polynomial: x^8+x^5+x^3+x^2+x+1 • Initial Value: FFh • Input Data Reflection: Not reflected • Result Data Reflection: Not reflected • XOR value: FFhSAE make...";
CM_ SG_ 2365275646 MtrGnrtr4InvrtrRfrn1Cntr "Motor/Generator 4 Inverter Reference 1 Counter: The message counter is used to detect situations where the transmitting ECU malfunction repeats the same frame all the time. The receiver of the information may use the counter parameter to detect this ...";
CM_ SG_ 2365275646 MtrGnrtr4InvrtrRfrnTrq "Motor/Generator 4 Inverter Reference Torque: This value is used for converting torque in percent to units of Nm.Value in Nm = (Percent Value)/(100%) * (Reference Torque)For example, if this parameter has a value of 400 Nm and the percent value is equ...";
CM_ SG_ 2365275646 MtrGnrtr4InvrtrRfrnSpd "Motor/Generator 4 Inverter Reference Speed: This value is used for converting Speed in percent to units of rpm.Value in rpm = (Percent Value)/(100%) * (Reference Speed)For example, if this parameter has a value of 8192 rpm and the percent value is eq...";
CM_ SG_ 2365275646 MtrGnrtr4InvrtrRfrnPwr "Motor/Generator 4 Inverter Reference Power: This value is used for converting power in percent to units of kW.  It is applicable to both mechanical and electrical power.(Value in kW) = (Percent Value)/(100%) * (Reference Power)For example, if this pa...";
CM_ BO_ 2365275902 "Motor/Generator 4 Inverter Status 1";
CM_ SG_ 2365275902 MtrGnrtr4InvrtrStts1CRC "Motor/Generator 4 Inverter Status 1 CRC: The CRC is defined as follows: • Length: 8 bits • Polynomial: x^8+x^5+x^3+x^2+x+1 • Initial Value: FFh • Input Data Reflection: Not reflected • Result Data Reflection: Not reflected • XOR value: FFhSAE makes n...";
CM_ SG_ 2365275902 MtrGnrtr4InvrtrStts1Cntr "Motor/Generator 4 Inverter Status 1 Counter: The message counter is used to detect situations where the transmitting ECU malfunction repeats the same frame all the time. The receiver of the information may use the counter parameter to detect this sit...";
CM_ SG_ 2365275902 MotorGenerator4Torque "Motor/Generator 4 Torque: The measured or estimated motor torque.  This refers to the motor rotor output and excludes any gearbox that may be attached to the motor.Refer to SPN 11939 [Reference Torque] to convert % to Nm.The motor is generating when ...";
CM_ SG_ 2365275902 MotorGenerator4Speed "Motor/Generator 4 Speed: The measured or estimated motor speed.  This refers to the motor rotor output and excludes any gearbox that may be attached to the motor.   Refer to SPN 11940 [Reference Speed] to convert % to rpm.";
CM_ SG_ 2365275902 MtrGnrtr4InvrtrDCSdCrrnt "Motor/Generator 4 Inverter DC Side Current: This is the DC side current of the inverter.Refer to SPN 11971 [Reference Current] to convert % to Amps.While motoring, the current is defined as positive.  For example, in a hybrid propulsion system, posit...";
CM_ SG_ 2365275902 MtrGnrtr4InvrtrDCSdVltg "Motor/Generator 4 Inverter DC Side Voltage: The measured or estimated DC side voltage.  Refer to SPN 11972 [Reference Voltage] to convert % to Volts.";
CM_ BO_ 2365276158 "Motor/Generator 4 Inverter Reference 2";
CM_ SG_ 2365276158 MtrGnrtr4InvrtrRfrn2CRC "Motor/Generator 4 Inverter Reference 2 CRC: The CRC is defined as follows: • Length: 8 bits • Polynomial: x^8+x^5+x^3+x^2+x+1 • Initial Value: FFh • Input Data Reflection: Not reflected • Result Data Reflection: Not reflected • XOR value: FFhSAE make...";
CM_ SG_ 2365276158 MtrGnrtr4InvrtrRfrn2Cntr "Motor/Generator 4 Inverter Reference 2 Counter: The message counter is used to detect situations where the transmitting ECU malfunction repeats the same frame all the time. The receiver of the information may use the counter parameter to detect this ...";
CM_ SG_ 2365276158 MtrGnrtr4InvrtrRfrnCrrnt "Motor/Generator 4 Inverter Reference Current: This value is used for converting inverter current in percent to units of Amps (RMS or DC).(Value in Amps) = (Percent Value)/(100%) * (Reference Current)For example, if this parameter has a value of 200 A...";
CM_ SG_ 2365276158 MtrGnrtr4InvrtrRfrnVltg "Motor/Generator 4 Inverter Reference Voltage: This value is used for converting inverter voltage in percent to units of Volts (RMS or DC).(Value in Volts) = (Percent Value)/(100%) * (Reference Voltage)For example, if this parameter has a value of 400...";
CM_ BO_ 2566603006 "Motor/Generator 4 Inverter Temperature";
CM_ SG_ 2566603006 MtrGnrtr4InvrtrTmprtr1 "Motor/Generator 4 Inverter Temperature 1: The exact location of this temperature can be defined by the manufacturer.  It is intended to be located somewhere on the inverter. ";
CM_ SG_ 2566603006 MtrGnrtr4InvrtrTmprtr2 "Motor/Generator 4 Inverter Temperature 2: The exact location of this temperature can be defined by the manufacturer.  It is intended to be located somewhere on the inverter. ";
CM_ SG_ 2566603006 MtrGnrtr4InvrtrTmprtr3 "Motor/Generator 4 Inverter Temperature 3: The exact location of this temperature can be defined by the manufacturer.  It is intended to be located somewhere on the inverter. ";
CM_ SG_ 2566603006 MtrGnrtr4InvrtrTmprtr4 "Motor/Generator 4 Inverter Temperature 4: The exact location of this temperature can be defined by the manufacturer.  It is intended to be located somewhere on the inverter. ";
CM_ BO_ 2566603262 "Motor/Generator 4 Inverter Motor Temperature";
CM_ SG_ 2566603262 MotorGenerator4Temperature1 "Motor/Generator 4 Temperature 1: The exact location of this temperature can be defined by the manufacturer.  It is intended to located somewhere on the motor.";
CM_ SG_ 2566603262 MotorGenerator4Temperature2 "Motor/Generator 4 Temperature 2: The exact location of this temperature can be defined by the manufacturer.  It is intended to located somewhere on the motor. ";
CM_ SG_ 2566603262 MotorGenerator4Temperature3 "Motor/Generator 4 Temperature 3: The exact location of this temperature can be defined by the manufacturer.  It is intended to located somewhere on the motor. ";
CM_ SG_ 2566603262 MotorGenerator4Temperature4 "Motor/Generator 4 Temperature 4: The exact location of this temperature can be defined by the manufacturer.  It is intended to located somewhere on the motor. ";
CM_ BO_ 2566603518 "Motor/Generator 4 Inverter Isolation Integrity";
CM_ SG_ 2566603518 MtrGnrtr4InvrtrIsltnIntgrtCRC "Motor/Generator 4 Inverter Isolation Integrity CRC: The CRC is defined as follows:• Length: 8 bits• Polynomial: x^8+x^5+x^3+x^2+x+1• Initial Value: FFh• Input Data Reflection: Not reflected• Result Data Reflection: Not reflected• XOR value: FFhSAE ma...";
CM_ SG_ 2566603518 MtrGnrtr4InvrtrIsltnIntgrtCntr "Motor/Generator 4 Inverter Isolation Integrity Counter: The message counter is used to detect situations where the transmitting ECU malfunction repeats the same frame all the time. The receiver of the information may use the counter parameter to dete...";
CM_ SG_ 2566603518 MtGt4IvtDCSdNtvtCsssGdVt "Motor/Generator 4 Inverter DC Side Negative to Chassis Ground Voltage: The voltage level of the high voltage DC side, as measured by the inverter between the negative side of the High Voltage DC Side input and the chassis of the inverter enclosure.  ...";
CM_ SG_ 2566603518 MtGt4IvtHVtBsAtvIstTstStts "Motor/Generator 4 Inverter High-Voltage Bus Active Isolation Test Status: Status of the high-voltage bus electrical active isolation test as performed by this instance of the Motor/Generator.0000b = No test requested / No test in process0001b = Test ...";
CM_ SG_ 2566603518 MtGt4IvtHVtBsPssvIstTstStts "Motor/Generator 4 Inverter High-Voltage Bus Passive Isolation Test Status: Status of the high-voltage bus electrical passive isolation test as performed by this instance of the Motor/Generator.0000b = No test requested / No test in process0001b = Tes...";
CM_ SG_ 2566603518 MtGt4IvtHVtBsAtvIstTstRsts "Motor/Generator 4 Inverter High-Voltage Bus Active Isolation Test Results: The isolation resistance that resulted from the High-Voltage Bus Active Isolation Test.See SPN 12003 [High-Voltage Bus Active Isolation Test Status] for test status and SPN 11...";
CM_ SG_ 2566603518 MtGt4IvtHVtBsPssvIstTstRsts "Motor/Generator 4 Inverter High-Voltage Bus Passive Isolation Test Results: The isolation resistance that resulted from the High-Voltage Bus Passive Isolation Test.See SPN 12004 [High-Voltage Bus Passive Isolation Test Status] for test status and SPN...";
CM_ BO_ 2566603774 "Motor/Generator 4 Inverter Active Power Limits";
CM_ SG_ 2566603774 MtGt4IvtPwLtddtUddRs "Motor/Generator 4 Inverter Power Limited due to Undefined Reason: Output power is being limited due to an undefined reason.00b = No power limit for this reason01b = Power limited for this reason10b = Error11b = Not Available";
CM_ SG_ 2566603774 MtGt4IvtPwLtddtDCSdCtMx "Motor/Generator 4 Inverter Power Limited due to DC Side Current Maximum: Output power is being limited due to SPN 11944 [Inverter DC Side Current] approaching or exceeding the SPN 11983 [Inverter Limits Active DC Side Current Maximum].00b = No power ...";
CM_ SG_ 2566603774 MtGt4IvtPwLtddtDCSdCtM "Motor/Generator 4 Inverter Power Limited due to DC Side Current Minimum: Output power is being limited due to SPN 11944 [Inverter DC Side Current] approaching or falling below the SPN 11984 [Inverter Limits Active DC Side Current Minimum].00b = No po...";
CM_ SG_ 2566603774 MtGt4IvtPwLtddtDCSdVtMx "Motor/Generator 4 Inverter Power Limited due to DC Side Voltage Maximum: Output power is being limited due to SPN 11922 [Inverter DC Side Voltage] approaching or exceeding the SPN 11981 [Inverter Limits Active DC Side Voltage Maximum].00b = No power ...";
CM_ SG_ 2566603774 MtGt4IvtPwLtddtDCSdVtM "Motor/Generator 4 Inverter Power Limited due to DC Side Voltage Minimum: Output power is being limited due to SPN 11922 [Inverter DC Side Voltage] approaching or falling below the SPN 11982 [Inverter Limits Active DC Side Voltage Minimum].00b = No po...";
CM_ SG_ 2566603774 MtGt4IvtPwLtddtMPwMx "Motor/Generator 4 Inverter Power Limited due to Mechanical Power Maximum: Output power is being limited due to Mechanical Power (product of SPN 11921 [Torque] and SPN 11919 [Speed]) approaching or exceeding the SPN 11953 [Inverter Limits Active Mecha...";
CM_ SG_ 2566603774 MtGt4IvtPwLtddtMPwM "Motor/Generator 4 Inverter Power Limited due to Mechanical Power Minimum: Output power is being limited due to Mechanical Power (product of SPN 11921 [Torque] and SPN 11919 [Speed]) approaching or falling below the SPN 11954 [Inverter Limits Active M...";
CM_ SG_ 2566603774 MtGt4IvtPwLtddtDCSdPwMx "Motor/Generator 4 Inverter Power Limited due to DC Side Power Maximum: Output power is being limited due to DC Side Power (product of SPN 11944 [Inverter DC Side Current] and SPN 11922 [Inverter DC Side Voltage]) approaching or exceeding the SPN 1195...";
CM_ SG_ 2566603774 MtGt4IvtPwLtddtDCSdPwM "Motor/Generator 4 Inverter Power Limited due to DC Side Power Minimum: Output power is being limited due to DC Side Power (product of SPN 11944 [Inverter DC Side Current] and SPN 11922 [Inverter DC Side Voltage]) approaching or falling below the SPN ...";
CM_ SG_ 2566603774 MtrGnrtr4InvrtrPwrLmtddtTrqMxmm "Motor/Generator 4 Inverter Power Limited due to Torque Maximum: Output power is being limited due to SPN 11921 [Torque] approaching or exceeding the SPN 11965 [Inverter Limits Active Torque Maximum].00b = No power limit for this reason01b = Power lim...";
CM_ SG_ 2566603774 MtrGnrtr4InvrtrPwrLmtddtTrqMnmm "Motor/Generator 4 Inverter Power Limited due to Torque Minimum: Output power is being limited due to SPN 11921 [Torque] approaching or falling below the SPN 11966 [Inverter Limits Active Torque Minimum].00b = No power limit for this reason01b = Power...";
CM_ SG_ 2566603774 MtrGnrtr4InvrtrPwrLmtddtSpdMxmm "Motor/Generator 4 Inverter Power Limited due to Speed Maximum: Output power is being limited due to SPN 11919 [Speed] approaching or exceeding the SPN 11967 [Inverter Limits Active Speed Maximum].00b = No power limit for this reason01b = Power limite...";
CM_ SG_ 2566603774 MtrGnrtr4InvrtrPwrLmtddtSpdMnmm "Motor/Generator 4 Inverter Power Limited due to Speed Minimum: Output power is being limited due to SPN 11919 [Speed] approaching or falling below the SPN 11968 [Inverter Limits Active Speed Minimum].00b = No power limit for this reason01b = Power li...";
CM_ SG_ 2566603774 MtGt4IvtPwLtddtIvtTpt "Motor/Generator 4 Inverter Power Limited due to Inverter Temperature: Output power is being limited due to one or more inverter temperature(s), see SPNs 11985 through 11988 [Inverter Temperature 1-4] approaching or exceeding internally defined limit(...";
CM_ SG_ 2566603774 MtGt4IvtPwLtddtMtTpt "Motor/Generator 4 Inverter Power Limited due to Motor Temperature: Output power is being limited due to one or more motor temperature(s), see SPNs 11920 and 11989 through 11991 [Motor Temperature 1-4] approaching or exceeding internally defined limit...";
CM_ BO_ 2365277438 "Motor/Generator 3 Inverter Reference 1";
CM_ SG_ 2365277438 MtrGnrtr3InvrtrRfrn1CRC "Motor/Generator 3 Inverter Reference 1 CRC: The CRC is defined as follows: • Length: 8 bits • Polynomial: x^8+x^5+x^3+x^2+x+1 • Initial Value: FFh • Input Data Reflection: Not reflected • Result Data Reflection: Not reflected • XOR value: FFhSAE make...";
CM_ SG_ 2365277438 MtrGnrtr3InvrtrRfrn1Cntr "Motor/Generator 3 Inverter Reference 1 Counter: The message counter is used to detect situations where the transmitting ECU malfunction repeats the same frame all the time. The receiver of the information may use the counter parameter to detect this ...";
CM_ SG_ 2365277438 MtrGnrtr3InvrtrRfrnTrq "Motor/Generator 3 Inverter Reference Torque: This value is used for converting torque in percent to units of Nm.Value in Nm = (Percent Value)/(100%) * (Reference Torque)For example, if this parameter has a value of 400 Nm and the percent value is equ...";
CM_ SG_ 2365277438 MtrGnrtr3InvrtrRfrnSpd "Motor/Generator 3 Inverter Reference Speed: This value is used for converting Speed in percent to units of rpm.Value in rpm = (Percent Value)/(100%) * (Reference Speed)For example, if this parameter has a value of 8192 rpm and the percent value is eq...";
CM_ SG_ 2365277438 MtrGnrtr3InvrtrRfrnPwr "Motor/Generator 3 Inverter Reference Power: This value is used for converting power in percent to units of kW.  It is applicable to both mechanical and electrical power.(Value in kW) = (Percent Value)/(100%) * (Reference Power)For example, if this pa...";
CM_ BO_ 2365277694 "Motor/Generator 3 Inverter Status 1";
CM_ SG_ 2365277694 MtrGnrtr3InvrtrStts1CRC "Motor/Generator 3 Inverter Status 1 CRC: The CRC is defined as follows: • Length: 8 bits • Polynomial: x^8+x^5+x^3+x^2+x+1 • Initial Value: FFh • Input Data Reflection: Not reflected • Result Data Reflection: Not reflected • XOR value: FFhSAE makes n...";
CM_ SG_ 2365277694 MtrGnrtr3InvrtrStts1Cntr "Motor/Generator 3 Inverter Status 1 Counter: The message counter is used to detect situations where the transmitting ECU malfunction repeats the same frame all the time. The receiver of the information may use the counter parameter to detect this sit...";
CM_ SG_ 2365277694 MotorGenerator3Torque "Motor/Generator 3 Torque: The measured or estimated motor torque.  This refers to the motor rotor output and excludes any gearbox that may be attached to the motor.Refer to SPN 11821 [Reference Torque] to convert % to Nm.The motor is generating when ...";
CM_ SG_ 2365277694 MotorGenerator3Speed "Motor/Generator 3 Speed: The measured or estimated motor speed.  This refers to the motor rotor output and excludes any gearbox that may be attached to the motor.   Refer to SPN 11822 [Reference Speed] to convert % to rpm.";
CM_ SG_ 2365277694 MtrGnrtr3InvrtrDCSdCrrnt "Motor/Generator 3 Inverter DC Side Current: This is the DC side current of the inverter.Refer to SPN 11853 [Reference Current] to convert % to Amps.While motoring, the current is defined as positive.  For example, in a hybrid propulsion system, posit...";
CM_ SG_ 2365277694 MtrGnrtr3InvrtrDCSdVltg "Motor/Generator 3 Inverter DC Side Voltage: The measured or estimated DC side voltage.  Refer to SPN 11854 [Reference Voltage] to convert % to Volts.";
CM_ BO_ 2365277950 "Motor/Generator 3 Inverter Reference 2";
CM_ SG_ 2365277950 MtrGnrtr3InvrtrRfrn2CRC "Motor/Generator 3 Inverter Reference 2 CRC: The CRC is defined as follows: • Length: 8 bits • Polynomial: x^8+x^5+x^3+x^2+x+1 • Initial Value: FFh • Input Data Reflection: Not reflected • Result Data Reflection: Not reflected • XOR value: FFhSAE make...";
CM_ SG_ 2365277950 MtrGnrtr3InvrtrRfrn2Cntr "Motor/Generator 3 Inverter Reference 2 Counter: The message counter is used to detect situations where the transmitting ECU malfunction repeats the same frame all the time. The receiver of the information may use the counter parameter to detect this ...";
CM_ SG_ 2365277950 MtrGnrtr3InvrtrRfrnCrrnt "Motor/Generator 3 Inverter Reference Current: This value is used for converting inverter current in percent to units of Amps (RMS or DC).(Value in Amps) = (Percent Value)/(100%) * (Reference Current)For example, if this parameter has a value of 200 A...";
CM_ SG_ 2365277950 MtrGnrtr3InvrtrRfrnVltg "Motor/Generator 3 Inverter Reference Voltage: This value is used for converting inverter voltage in percent to units of Volts (RMS or DC).(Value in Volts) = (Percent Value)/(100%) * (Reference Voltage)For example, if this parameter has a value of 400...";
CM_ BO_ 2566604798 "Motor/Generator 3 Inverter Temperature";
CM_ SG_ 2566604798 MtrGnrtr3InvrtrTmprtr1 "Motor/Generator 3 Inverter Temperature 1: The exact location of this temperature can be defined by the manufacturer.  It is intended to be located somewhere on the inverter. ";
CM_ SG_ 2566604798 MtrGnrtr3InvrtrTmprtr2 "Motor/Generator 3 Inverter Temperature 2: The exact location of this temperature can be defined by the manufacturer.  It is intended to be located somewhere on the inverter. ";
CM_ SG_ 2566604798 MtrGnrtr3InvrtrTmprtr3 "Motor/Generator 3 Inverter Temperature 3: The exact location of this temperature can be defined by the manufacturer.  It is intended to be located somewhere on the inverter. ";
CM_ SG_ 2566604798 MtrGnrtr3InvrtrTmprtr4 "Motor/Generator 3 Inverter Temperature 4: The exact location of this temperature can be defined by the manufacturer.  It is intended to be located somewhere on the inverter. ";
CM_ BO_ 2566605054 "Motor/Generator 3 Inverter Motor Temperature";
CM_ SG_ 2566605054 MotorGenerator3Temperature1 "Motor/Generator 3 Temperature 1: The exact location of this temperature can be defined by the manufacturer.  It is intended to located somewhere on the motor.";
CM_ SG_ 2566605054 MotorGenerator3Temperature2 "Motor/Generator 3 Temperature 2: The exact location of this temperature can be defined by the manufacturer.  It is intended to located somewhere on the motor. ";
CM_ SG_ 2566605054 MotorGenerator3Temperature3 "Motor/Generator 3 Temperature 3: The exact location of this temperature can be defined by the manufacturer.  It is intended to located somewhere on the motor. ";
CM_ SG_ 2566605054 MotorGenerator3Temperature4 "Motor/Generator 3 Temperature 4: The exact location of this temperature can be defined by the manufacturer.  It is intended to located somewhere on the motor. ";
CM_ BO_ 2566605310 "Motor/Generator 3 Inverter Isolation Integrity";
CM_ SG_ 2566605310 MtrGnrtr3InvrtrIsltnIntgrtCRC "Motor/Generator 3 Inverter Isolation Integrity CRC: The CRC is defined as follows:• Length: 8 bits• Polynomial: x^8+x^5+x^3+x^2+x+1• Initial Value: FFh• Input Data Reflection: Not reflected• Result Data Reflection: Not reflected• XOR value: FFhSAE ma...";
CM_ SG_ 2566605310 MtrGnrtr3InvrtrIsltnIntgrtCntr "Motor/Generator 3 Inverter Isolation Integrity Counter: The message counter is used to detect situations where the transmitting ECU malfunction repeats the same frame all the time. The receiver of the information may use the counter parameter to dete...";
CM_ SG_ 2566605310 MtGt3IvtDCSdNtvtCsssGdVt "Motor/Generator 3 Inverter DC Side Negative to Chassis Ground Voltage: The voltage level of the high voltage DC side, as measured by the inverter between the negative side of the High Voltage DC Side input and the chassis of the inverter enclosure.  ...";
CM_ SG_ 2566605310 MtGt3IvtHVtBsAtvIstTstStts "Motor/Generator 3 Inverter High-Voltage Bus Active Isolation Test Status: Status of the high-voltage bus electrical active isolation test as performed by this instance of the Motor/Generator.0000b = No test requested / No test in process0001b = Test ...";
CM_ SG_ 2566605310 MtGt3IvtHVtBsPssvIstTstStts "Motor/Generator 3 Inverter High-Voltage Bus Passive Isolation Test Status: Status of the high-voltage bus electrical passive isolation test as performed by this instance of the Motor/Generator.0000b = No test requested / No test in process0001b = Tes...";
CM_ SG_ 2566605310 MtGt3IvtHVtBsAtvIstTstRsts "Motor/Generator 3 Inverter High-Voltage Bus Active Isolation Test Results: The isolation resistance that resulted from the High-Voltage Bus Active Isolation Test.See SPN 11885 [High-Voltage Bus Active Isolation Test Status] for test status and SPN 11...";
CM_ SG_ 2566605310 MtGt3IvtHVtBsPssvIstTstRsts "Motor/Generator 3 Inverter High-Voltage Bus Passive Isolation Test Results: The isolation resistance that resulted from the High-Voltage Bus Passive Isolation Test.See SPN 11886 [High-Voltage Bus Passive Isolation Test Status] for test status and SPN...";
CM_ BO_ 2566605566 "Motor/Generator 3 Inverter Active Power Limits";
CM_ SG_ 2566605566 MtGt3IvtPwLtddtUddRs "Motor/Generator 3 Inverter Power Limited due to Undefined Reason: Output power is being limited due to an undefined reason.00b = No power limit for this reason01b = Power limited for this reason10b = Error11b = Not Available";
CM_ SG_ 2566605566 MtGt3IvtPwLtddtDCSdCtMx "Motor/Generator 3 Inverter Power Limited due to DC Side Current Maximum: Output power is being limited due to SPN 11826 [Inverter DC Side Current] approaching or exceeding the SPN 11865 [Inverter Limits Active DC Side Current Maximum].00b = No power ...";
CM_ SG_ 2566605566 MtGt3IvtPwLtddtDCSdCtM "Motor/Generator 3 Inverter Power Limited due to DC Side Current Minimum: Output power is being limited due to SPN 11826 [Inverter DC Side Current] approaching or falling below the SPN 11866 [Inverter Limits Active DC Side Current Minimum].00b = No po...";
CM_ SG_ 2566605566 MtGt3IvtPwLtddtDCSdVtMx "Motor/Generator 3 Inverter Power Limited due to DC Side Voltage Maximum: Output power is being limited due to SPN 11804 [Inverter DC Side Voltage] approaching or exceeding the SPN 11863 [Inverter Limits Active DC Side Voltage Maximum].00b = No power ...";
CM_ SG_ 2566605566 MtGt3IvtPwLtddtDCSdVtM "Motor/Generator 3 Inverter Power Limited due to DC Side Voltage Minimum: Output power is being limited due to SPN 11804 [Inverter DC Side Voltage] approaching or falling below the SPN 11864 [Inverter Limits Active DC Side Voltage Minimum].00b = No po...";
CM_ SG_ 2566605566 MtGt3IvtPwLtddtMPwMx "Motor/Generator 3 Inverter Power Limited due to Mechanical Power Maximum: Output power is being limited due to Mechanical Power (product of SPN 11803 [Torque] and SPN 11801 [Speed]) approaching or exceeding the SPN 11835 [Inverter Limits Active Mecha...";
CM_ SG_ 2566605566 MtGt3IvtPwLtddtMPwM "Motor/Generator 3 Inverter Power Limited due to Mechanical Power Minimum: Output power is being limited due to Mechanical Power (product of SPN 11803 [Torque] and SPN 11801 [Speed]) approaching or falling below the SPN 11836 [Inverter Limits Active M...";
CM_ SG_ 2566605566 MtGt3IvtPwLtddtDCSdPwMx "Motor/Generator 3 Inverter Power Limited due to DC Side Power Maximum: Output power is being limited due to DC Side Power (product of SPN 11826 [Inverter DC Side Current] and SPN 11804 [Inverter DC Side Voltage]) approaching or exceeding the SPN 1183...";
CM_ SG_ 2566605566 MtGt3IvtPwLtddtDCSdPwM "Motor/Generator 3 Inverter Power Limited due to DC Side Power Minimum: Output power is being limited due to DC Side Power (product of SPN 11826 [Inverter DC Side Current] and SPN 11804 [Inverter DC Side Voltage]) approaching or falling below the SPN ...";
CM_ SG_ 2566605566 MtrGnrtr3InvrtrPwrLmtddtTrqMxmm "Motor/Generator 3 Inverter Power Limited due to Torque Maximum: Output power is being limited due to SPN 11803 [Torque] approaching or exceeding the SPN 11847 [Inverter Limits Active Torque Maximum].00b = No power limit for this reason01b = Power lim...";
CM_ SG_ 2566605566 MtrGnrtr3InvrtrPwrLmtddtTrqMnmm "Motor/Generator 3 Inverter Power Limited due to Torque Minimum: Output power is being limited due to SPN 11803 [Torque] approaching or falling below the SPN 11848 [Inverter Limits Active Torque Minimum].00b = No power limit for this reason01b = Power...";
CM_ SG_ 2566605566 MtrGnrtr3InvrtrPwrLmtddtSpdMxmm "Motor/Generator 3 Inverter Power Limited due to Speed Maximum: Output power is being limited due to SPN 11801 [Speed] approaching or exceeding the SPN 11849 [Inverter Limits Active Speed Maximum].00b = No power limit for this reason01b = Power limite...";
CM_ SG_ 2566605566 MtrGnrtr3InvrtrPwrLmtddtSpdMnmm "Motor/Generator 3 Inverter Power Limited due to Speed Minimum: Output power is being limited due to SPN 11801 [Speed] approaching or falling below the SPN 11850 [Inverter Limits Active Speed Minimum].00b = No power limit for this reason01b = Power li...";
CM_ SG_ 2566605566 MtGt3IvtPwLtddtIvtTpt "Motor/Generator 3 Inverter Power Limited due to Inverter Temperature: Output power is being limited due to one or more inverter temperature(s), see SPNs 11867 through 11870 [Inverter Temperature 1-4] approaching or exceeding internally defined limit(...";
CM_ SG_ 2566605566 MtGt3IvtPwLtddtMtTpt "Motor/Generator 3 Inverter Power Limited due to Motor Temperature: Output power is being limited due to one or more motor temperature(s), see SPNs 11802 and 11871 through 11873 [Motor Temperature 1-4] approaching or exceeding internally defined limit...";
CM_ BO_ 2566605822 "Automated Driving System Feedback";
CM_ SG_ 2566605822 SAddssCtDvTSC1CtPpsP7 "Source Address of Controlling Device for TSC1 Control Purpose P7: The source address of the SAE J1939 device that is currently sending a TSC1 message with control purpose P7 that is actively controlling or limitting the power system output.254 (FEh) ...";
CM_ SG_ 2566605822 TSC1CntrlPrpsP7RdnssStts "TSC1 Control Purpose P7 Readiness Status: This parameter is used to indicate an application's state of readiness for responding to TSC1 Control Purpose P7 (see SPN 3350) messages.00b = Not Ready01b = Ready10b = Error11b = Not Available/Not Supported....";
CM_ BO_ 2566606078 "Cab Climate System Information 2";
CM_ SG_ 2566606078 CabHeaterPower "Cab Heater Power: Electrical power consumed by the cab heater.";
CM_ BO_ 2566606334 "Maintenance Information";
CM_ SG_ 2566606334 EngineAirFilter1LifeRemaining "Engine Air Filter 1 Life Remaining: Signal which indicates an actual life remaining in percent of the engine air filter #1. 0% represents no life remaining in the filter and 100% represents a new filter with full life remaining.";
CM_ SG_ 2566606334 EngineAirFilter2LifeRemaining "Engine Air Filter 2 Life Remaining: Signal which indicates an actual life remaining in percent of the engine air filter #2. 0% represents no life remaining in the filter and 100% represents a new filter with full life remaining.";
CM_ SG_ 2566606334 EngineAirFilter3LifeRemaining "Engine Air Filter 3 Life Remaining: Signal which indicates an actual life remaining in percent of the engine air filter #3. 0% represents no life remaining in the filter and 100% represents a new filter with full life remaining.";
CM_ SG_ 2566606334 EngineAirFilter4LifeRemaining "Engine Air Filter 4 Life Remaining: Signal which indicates an actual life remaining in percent of the engine air filter #4. 0% represents no life remaining in the filter and 100% represents a new filter with full life remaining.";
CM_ SG_ 2566606334 EngineFuelFilterLifeRemaining "Engine Fuel Filter Life Remaining: Signal which indicates an actual life remaining in percent of the engine fuel filter.  0% represents no life remaining in the filter and 100% represents a new filter with full life remaining.";
CM_ SG_ 2566606334 EngnFlFltrStnSdLfRmnng "Engine Fuel Filter (Suction Side) Life Remaining: Signal which indicates an actual life remaining in percent of the engine suction side fuel filter.  0% represents no life remaining in the filter and 100% represents a new filter with full life remain...";
CM_ SG_ 2566606334 EngineOilFilterLifeRemaining "Engine Oil Filter Life Remaining: Signal which indicates an actual life remaining in percent of the engine oil filter.  0% represents no life remaining in the filter and 100% represents a new filter with full life remaining.";
CM_ SG_ 2566606334 TrnsmssnOIlFltrLfRmnng "Transmission OIl Filter Life Remaining: Signal which indicates an actual life remaining in percent of the transmission oil filter.  0% represents no life remaining in the filter and 100% represents a new filter with full life remaining.";
CM_ BO_ 2499497726 "Hoist Control Information";
CM_ SG_ 2499497726 HoistLeverPosition "Hoist Lever Position: The position of the operator's hoist control lever (used for a dump body) relative to travel from a neutral (center) position.  Position value of 0 indicates the lever is in the neutral (central) position where no hoist movement...";
CM_ SG_ 2499497726 HoistLeverDetentPositionStatus "Hoist Lever Detent Position Status: The status of the hoist lever (used for a dump body) in the detent position for either direction of travel.  00b = Not in the Detent Position01b = In the Detent Position10b = Error Indicator11b = Not Available...";
CM_ BO_ 2633715710 "High Voltage Energy Storage Pack 6 History";
CM_ SG_ 2633715710 HVESP6StateofHealth "HVESP6 State of Health: This signal represents the expected remaining Life of this High Voltage Energy Storage Pack instance, in percent.  Battery life is a manufacturer-specific measure of how well the energy storage system is functioning relative t...";
CM_ SG_ 2633715710 HVESP6CnttrOpnUndrLdCnt "HVESP6 Contactor Open Under Load Count: This signal represents the number of times the contactors inside this High Voltage Energy Storage Pack instance have opened while current is flowing through them.  The current level (that determines if an openi...";
CM_ SG_ 2633715710 HVESP6TotalEnergyThroughput "HVESP6 Total Energy Throughput: The total energy throughput which has flowed through this High Voltage Energy Storage Pack instance.  This parameter is the sum of the absolute values of the Energy into and out of this HVES instance.  This parameter i...";
CM_ SG_ 2633715710 HVESP6TotalAccumulatedCharge "HVESP6 Total Accumulated Charge: The total accumulated amp hours which have flowed through this High Voltage Energy Storage Pack instance.  This parameter is the sum of the absolute values of the Ampere hours into and out of this HVES instance.  This...";
CM_ BO_ 2566607102 "High Voltage Energy Storage Pack 6 Configuration";
CM_ SG_ 2566607102 HVESP6NominalVoltage "HVESP6 Nominal Voltage: Per the HVES manufacturer, this is the nominal operating voltage of this High Voltage Energy Storage Pack instance, e.g. “300V” or “600V”.This parameter is for one of multiple packs in an HVESS.  If there is only one pack in t...";
CM_ SG_ 2566607102 HVESP6RmmnddMnmmOprtngVltg "HVESP6 Recommended Minimum Operating Voltage: Per the HVES manufacturer, this is the minimum recommended voltage level for this High Voltage Energy Storage Pack instance operation.  Operating below this value may compromise HVES life.This parameter i...";
CM_ SG_ 2566607102 HVESP6RmmnddMxmmOprtngVltg "HVESP6 Recommended Maximum Operating Voltage: Per the HVES manufacturer, this is the maximum recommended voltage level for this High Voltage Energy Storage Pack instance operation.  Operating above this value may compromise HVES life.This parameter i...";
CM_ SG_ 2566607102 HVESP6RmmnddMnmmSttOfChrg "HVESP6 Recommended Minimum State Of Charge: Per the HVES manufacturer, this is the recommended minimum state of charge for this High Voltage Energy Storage Pack instance operation.  Operating below this value may compromise HVES life.This parameter i...";
CM_ SG_ 2566607102 HVESP6RmmnddMxmmSttOfChrg "HVESP6 Recommended Maximum State Of Charge: Per the HVES manufacturer, this is the recommended maximum state of charge for this High Voltage Energy Storage Pack instance operation.  Operating above this value may compromise HVES life.This parameter i...";
CM_ SG_ 2566607102 HVESP6RmmnddMxmmOprtngTmprtr "HVESP6 Recommended Maximum Operating Temperature: Per the HVES manufacturer, this is the recommended maximum temperature for this High Voltage Energy Storage Pack instance operation.  Operating above this value may damage HVES hardware, or compromise...";
CM_ SG_ 2566607102 HVESP6RmmnddMnmmOprtngTmprtr "HVESP6 Recommended Minimum Operating Temperature: Per the HVES manufacturer, this is the recommended minimum temperature for this High Voltage Energy Storage Pack instance operation.  Operating below this value may damage HVES hardware, or compromise...";
CM_ SG_ 2566607102 HVESP6CellMaximumVoltageLimit "HVESP6 Cell Maximum Voltage Limit: Per the HVES manufacturer, this is the maximum cell voltage for this High Voltage Energy Storage Pack instance operation.  Operating above this value may damage HVES hardware, or compromise HVES life.This parameter ...";
CM_ SG_ 2566607102 HVESP6CellMinimumVoltageLimit "HVESP6 Cell Minimum Voltage Limit: Per the HVES manufacturer, this is the minimum cell voltage for this High Voltage Energy Storage Pack instance operation.  Operating below this value may damage HVES hardware, or compromise HVES life.This parameter ...";
CM_ BO_ 2633716222 "High Voltage Energy Storage Pack 5 History";
CM_ SG_ 2633716222 HVESP5StateofHealth "HVESP5 State of Health: This signal represents the expected remaining Life of this High Voltage Energy Storage Pack instance, in percent.  Battery life is a manufacturer-specific measure of how well the energy storage system is functioning relative t...";
CM_ SG_ 2633716222 HVESP5CnttrOpnUndrLdCnt "HVESP5 Contactor Open Under Load Count: This signal represents the number of times the contactors inside this High Voltage Energy Storage Pack instance have opened while current is flowing through them.  The current level (that determines if an openi...";
CM_ SG_ 2633716222 HVESP5TotalEnergyThroughput "HVESP5 Total Energy Throughput: The total energy throughput which has flowed through this High Voltage Energy Storage Pack instance.  This parameter is the sum of the absolute values of the Energy into and out of this HVES instance.  This parameter i...";
CM_ SG_ 2633716222 HVESP5TotalAccumulatedCharge "HVESP5 Total Accumulated Charge: The total accumulated amp hours which have flowed through this High Voltage Energy Storage Pack instance.  This parameter is the sum of the absolute values of the Ampere hours into and out of this HVES instance.  This...";
CM_ BO_ 2566607614 "High Voltage Energy Storage Pack 5 Configuration";
CM_ SG_ 2566607614 HVESP5NominalVoltage "HVESP5 Nominal Voltage: Per the HVES manufacturer, this is the nominal operating voltage of this High Voltage Energy Storage Pack instance, e.g. “300V” or “600V”.This parameter is for one of multiple packs in an HVESS.  If there is only one pack in t...";
CM_ SG_ 2566607614 HVESP5RmmnddMnmmOprtngVltg "HVESP5 Recommended Minimum Operating Voltage: Per the HVES manufacturer, this is the minimum recommended voltage level for this High Voltage Energy Storage Pack instance operation.  Operating below this value may compromise HVES life.This parameter i...";
CM_ SG_ 2566607614 HVESP5RmmnddMxmmOprtngVltg "HVESP5 Recommended Maximum Operating Voltage: Per the HVES manufacturer, this is the maximum recommended voltage level for this High Voltage Energy Storage Pack instance operation.  Operating above this value may compromise HVES life.This parameter i...";
CM_ SG_ 2566607614 HVESP5RmmnddMnmmSttOfChrg "HVESP5 Recommended Minimum State Of Charge: Per the HVES manufacturer, this is the recommended minimum state of charge for this High Voltage Energy Storage Pack instance operation.  Operating below this value may compromise HVES life.This parameter i...";
CM_ SG_ 2566607614 HVESP5RmmnddMxmmSttOfChrg "HVESP5 Recommended Maximum State Of Charge: Per the HVES manufacturer, this is the recommended maximum state of charge for this High Voltage Energy Storage Pack instance operation.  Operating above this value may compromise HVES life.This parameter i...";
CM_ SG_ 2566607614 HVESP5RmmnddMxmmOprtngTmprtr "HVESP5 Recommended Maximum Operating Temperature: Per the HVES manufacturer, this is the recommended maximum temperature for this High Voltage Energy Storage Pack instance operation.  Operating above this value may damage HVES hardware, or compromise...";
CM_ SG_ 2566607614 HVESP5RmmnddMnmmOprtngTmprtr "HVESP5 Recommended Minimum Operating Temperature: Per the HVES manufacturer, this is the recommended minimum temperature for this High Voltage Energy Storage Pack instance operation.  Operating below this value may damage HVES hardware, or compromise...";
CM_ SG_ 2566607614 HVESP5CellMaximumVoltageLimit "HVESP5 Cell Maximum Voltage Limit: Per the HVES manufacturer, this is the maximum cell voltage for this High Voltage Energy Storage Pack instance operation.  Operating above this value may damage HVES hardware, or compromise HVES life.This parameter ...";
CM_ SG_ 2566607614 HVESP5CellMinimumVoltageLimit "HVESP5 Cell Minimum Voltage Limit: Per the HVES manufacturer, this is the minimum cell voltage for this High Voltage Energy Storage Pack instance operation.  Operating below this value may damage HVES hardware, or compromise HVES life.This parameter ...";
CM_ BO_ 2633716734 "High Voltage Energy Storage Pack 4 History";
CM_ SG_ 2633716734 HVESP4StateofHealth "HVESP4 State of Health: This signal represents the expected remaining Life of this High Voltage Energy Storage Pack instance, in percent.  Battery life is a manufacturer-specific measure of how well the energy storage system is functioning relative t...";
CM_ SG_ 2633716734 HVESP4CnttrOpnUndrLdCnt "HVESP4 Contactor Open Under Load Count: This signal represents the number of times the contactors inside this High Voltage Energy Storage Pack instance have opened while current is flowing through them.  The current level (that determines if an openi...";
CM_ SG_ 2633716734 HVESP4TotalEnergyThroughput "HVESP4 Total Energy Throughput: The total energy throughput which has flowed through this High Voltage Energy Storage Pack instance.  This parameter is the sum of the absolute values of the Energy into and out of this HVES instance.  This parameter i...";
CM_ SG_ 2633716734 HVESP4TotalAccumulatedCharge "HVESP4 Total Accumulated Charge: The total accumulated amp hours which have flowed through this High Voltage Energy Storage Pack instance.  This parameter is the sum of the absolute values of the Ampere hours into and out of this HVES instance.  This...";
CM_ BO_ 2566608126 "High Voltage Energy Storage Pack 4 Configuration";
CM_ SG_ 2566608126 HVESP4NominalVoltage "HVESP4 Nominal Voltage: Per the HVES manufacturer, this is the nominal operating voltage of this High Voltage Energy Storage Pack instance, e.g. “300V” or “600V”.This parameter is for one of multiple packs in an HVESS.  If there is only one pack in t...";
CM_ SG_ 2566608126 HVESP4RmmnddMnmmOprtngVltg "HVESP4 Recommended Minimum Operating Voltage: Per the HVES manufacturer, this is the minimum recommended voltage level for this High Voltage Energy Storage Pack instance operation.  Operating below this value may compromise HVES life.This parameter i...";
CM_ SG_ 2566608126 HVESP4RmmnddMxmmOprtngVltg "HVESP4 Recommended Maximum Operating Voltage: Per the HVES manufacturer, this is the maximum recommended voltage level for this High Voltage Energy Storage Pack instance operation.  Operating above this value may compromise HVES life.This parameter i...";
CM_ SG_ 2566608126 HVESP4RmmnddMnmmSttOfChrg "HVESP4 Recommended Minimum State Of Charge: Per the HVES manufacturer, this is the recommended minimum state of charge for this High Voltage Energy Storage Pack instance operation.  Operating below this value may compromise HVES life.This parameter i...";
CM_ SG_ 2566608126 HVESP4RmmnddMxmmSttOfChrg "HVESP4 Recommended Maximum State Of Charge: Per the HVES manufacturer, this is the recommended maximum state of charge for this High Voltage Energy Storage Pack instance operation.  Operating above this value may compromise HVES life.This parameter i...";
CM_ SG_ 2566608126 HVESP4RmmnddMxmmOprtngTmprtr "HVESP4 Recommended Maximum Operating Temperature: Per the HVES manufacturer, this is the recommended maximum temperature for this High Voltage Energy Storage Pack instance operation.  Operating above this value may damage HVES hardware, or compromise...";
CM_ SG_ 2566608126 HVESP4RmmnddMnmmOprtngTmprtr "HVESP4 Recommended Minimum Operating Temperature: Per the HVES manufacturer, this is the recommended minimum temperature for this High Voltage Energy Storage Pack instance operation.  Operating below this value may damage HVES hardware, or compromise...";
CM_ SG_ 2566608126 HVESP4CellMaximumVoltageLimit "HVESP4 Cell Maximum Voltage Limit: Per the HVES manufacturer, this is the maximum cell voltage for this High Voltage Energy Storage Pack instance operation.  Operating above this value may damage HVES hardware, or compromise HVES life.This parameter ...";
CM_ SG_ 2566608126 HVESP4CellMinimumVoltageLimit "HVESP4 Cell Minimum Voltage Limit: Per the HVES manufacturer, this is the minimum cell voltage for this High Voltage Energy Storage Pack instance operation.  Operating below this value may damage HVES hardware, or compromise HVES life.This parameter ...";
CM_ BO_ 2633717246 "High Voltage Energy Storage Pack 3 History";
CM_ SG_ 2633717246 HVESP3StateofHealth "HVESP3 State of Health: This signal represents the expected remaining Life of this High Voltage Energy Storage Pack instance, in percent.  Battery life is a manufacturer-specific measure of how well the energy storage system is functioning relative t...";
CM_ SG_ 2633717246 HVESP3CnttrOpnUndrLdCnt "HVESP3 Contactor Open Under Load Count: This signal represents the number of times the contactors inside this High Voltage Energy Storage Pack instance have opened while current is flowing through them.  The current level (that determines if an openi...";
CM_ SG_ 2633717246 HVESP3TotalEnergyThroughput "HVESP3 Total Energy Throughput: The total energy throughput which has flowed through this High Voltage Energy Storage Pack instance.  This parameter is the sum of the absolute values of the Energy into and out of this HVES instance.  This parameter i...";
CM_ SG_ 2633717246 HVESP3TotalAccumulatedCharge "HVESP3 Total Accumulated Charge: The total accumulated amp hours which have flowed through this High Voltage Energy Storage Pack instance.  This parameter is the sum of the absolute values of the Ampere hours into and out of this HVES instance.  This...";
CM_ BO_ 2566608638 "High Voltage Energy Storage Pack 3 Configuration";
CM_ SG_ 2566608638 HVESP3NominalVoltage "HVESP3 Nominal Voltage: Per the HVES manufacturer, this is the nominal operating voltage of this High Voltage Energy Storage Pack instance, e.g. “300V” or “600V”.This parameter is for one of multiple packs in an HVESS.  If there is only one pack in t...";
CM_ SG_ 2566608638 HVESP3RmmnddMnmmOprtngVltg "HVESP3 Recommended Minimum Operating Voltage: Per the HVES manufacturer, this is the minimum recommended voltage level for this High Voltage Energy Storage Pack instance operation.  Operating below this value may compromise HVES life.This parameter i...";
CM_ SG_ 2566608638 HVESP3RmmnddMxmmOprtngVltg "HVESP3 Recommended Maximum Operating Voltage: Per the HVES manufacturer, this is the maximum recommended voltage level for this High Voltage Energy Storage Pack instance operation.  Operating above this value may compromise HVES life.This parameter i...";
CM_ SG_ 2566608638 HVESP3RmmnddMnmmSttOfChrg "HVESP3 Recommended Minimum State Of Charge: Per the HVES manufacturer, this is the recommended minimum state of charge for this High Voltage Energy Storage Pack instance operation.  Operating below this value may compromise HVES life.This parameter i...";
CM_ SG_ 2566608638 HVESP3RmmnddMxmmSttOfChrg "HVESP3 Recommended Maximum State Of Charge: Per the HVES manufacturer, this is the recommended maximum state of charge for this High Voltage Energy Storage Pack instance operation.  Operating above this value may compromise HVES life.This parameter i...";
CM_ SG_ 2566608638 HVESP3RmmnddMxmmOprtngTmprtr "HVESP3 Recommended Maximum Operating Temperature: Per the HVES manufacturer, this is the recommended maximum temperature for this High Voltage Energy Storage Pack instance operation.  Operating above this value may damage HVES hardware, or compromise...";
CM_ SG_ 2566608638 HVESP3RmmnddMnmmOprtngTmprtr "HVESP3 Recommended Minimum Operating Temperature: Per the HVES manufacturer, this is the recommended minimum temperature for this High Voltage Energy Storage Pack instance operation.  Operating below this value may damage HVES hardware, or compromise...";
CM_ SG_ 2566608638 HVESP3CellMaximumVoltageLimit "HVESP3 Cell Maximum Voltage Limit: Per the HVES manufacturer, this is the maximum cell voltage for this High Voltage Energy Storage Pack instance operation.  Operating above this value may damage HVES hardware, or compromise HVES life.This parameter ...";
CM_ SG_ 2566608638 HVESP3CellMinimumVoltageLimit "HVESP3 Cell Minimum Voltage Limit: Per the HVES manufacturer, this is the minimum cell voltage for this High Voltage Energy Storage Pack instance operation.  Operating below this value may damage HVES hardware, or compromise HVES life.This parameter ...";
CM_ BO_ 2633717758 "High Voltage Energy Storage Pack 2 History";
CM_ SG_ 2633717758 HVESP2StateofHealth "HVESP2 State of Health: This signal represents the expected remaining Life of this High Voltage Energy Storage Pack instance, in percent.  Battery life is a manufacturer-specific measure of how well the energy storage system is functioning relative t...";
CM_ SG_ 2633717758 HVESP2CnttrOpnUndrLdCnt "HVESP2 Contactor Open Under Load Count: This signal represents the number of times the contactors inside this High Voltage Energy Storage Pack instance have opened while current is flowing through them.  The current level (that determines if an openi...";
CM_ SG_ 2633717758 HVESP2TotalEnergyThroughput "HVESP2 Total Energy Throughput: The total energy throughput which has flowed through this High Voltage Energy Storage Pack instance.  This parameter is the sum of the absolute values of the Energy into and out of this HVES instance.  This parameter i...";
CM_ SG_ 2633717758 HVESP2TotalAccumulatedCharge "HVESP2 Total Accumulated Charge: The total accumulated amp hours which have flowed through this High Voltage Energy Storage Pack instance.  This parameter is the sum of the absolute values of the Ampere hours into and out of this HVES instance.  This...";
CM_ BO_ 2566609150 "High Voltage Energy Storage Pack 2 Configuration";
CM_ SG_ 2566609150 HVESP2NominalVoltage "HVESP2 Nominal Voltage: Per the HVES manufacturer, this is the nominal operating voltage of this High Voltage Energy Storage Pack instance, e.g. “300V” or “600V”.This parameter is for one of multiple packs in an HVESS.  If there is only one pack in t...";
CM_ SG_ 2566609150 HVESP2RmmnddMnmmOprtngVltg "HVESP2 Recommended Minimum Operating Voltage: Per the HVES manufacturer, this is the minimum recommended voltage level for this High Voltage Energy Storage Pack instance operation.  Operating below this value may compromise HVES life.This parameter i...";
CM_ SG_ 2566609150 HVESP2RmmnddMxmmOprtngVltg "HVESP2 Recommended Maximum Operating Voltage: Per the HVES manufacturer, this is the maximum recommended voltage level for this High Voltage Energy Storage Pack instance operation.  Operating above this value may compromise HVES life.This parameter i...";
CM_ SG_ 2566609150 HVESP2RmmnddMnmmSttOfChrg "HVESP2 Recommended Minimum State Of Charge: Per the HVES manufacturer, this is the recommended minimum state of charge for this High Voltage Energy Storage Pack instance operation.  Operating below this value may compromise HVES life.This parameter i...";
CM_ SG_ 2566609150 HVESP2RmmnddMxmmSttOfChrg "HVESP2 Recommended Maximum State Of Charge: Per the HVES manufacturer, this is the recommended maximum state of charge for this High Voltage Energy Storage Pack instance operation.  Operating above this value may compromise HVES life.This parameter i...";
CM_ SG_ 2566609150 HVESP2RmmnddMxmmOprtngTmprtr "HVESP2 Recommended Maximum Operating Temperature: Per the HVES manufacturer, this is the recommended maximum temperature for this High Voltage Energy Storage Pack instance operation.  Operating above this value may damage HVES hardware, or compromise...";
CM_ SG_ 2566609150 HVESP2RmmnddMnmmOprtngTmprtr "HVESP2 Recommended Minimum Operating Temperature: Per the HVES manufacturer, this is the recommended minimum temperature for this High Voltage Energy Storage Pack instance operation.  Operating below this value may damage HVES hardware, or compromise...";
CM_ SG_ 2566609150 HVESP2CellMaximumVoltageLimit "HVESP2 Cell Maximum Voltage Limit: Per the HVES manufacturer, this is the maximum cell voltage for this High Voltage Energy Storage Pack instance operation.  Operating above this value may damage HVES hardware, or compromise HVES life.This parameter ...";
CM_ SG_ 2566609150 HVESP2CellMinimumVoltageLimit "HVESP2 Cell Minimum Voltage Limit: Per the HVES manufacturer, this is the minimum cell voltage for this High Voltage Energy Storage Pack instance operation.  Operating below this value may damage HVES hardware, or compromise HVES life.This parameter ...";
CM_ BO_ 2633718270 "High Voltage Energy Storage Pack 1 History";
CM_ SG_ 2633718270 HVESP1StateofHealth "HVESP1 State of Health: This signal represents the expected remaining Life of this High Voltage Energy Storage Pack instance, in percent.  Battery life is a manufacturer-specific measure of how well the energy storage system is functioning relative t...";
CM_ SG_ 2633718270 HVESP1CnttrOpnUndrLdCnt "HVESP1 Contactor Open Under Load Count: This signal represents the number of times the contactors inside this High Voltage Energy Storage Pack instance have opened while current is flowing through them.  The current level (that determines if an openi...";
CM_ SG_ 2633718270 HVESP1TotalEnergyThroughput "HVESP1 Total Energy Throughput: The total energy throughput which has flowed through this High Voltage Energy Storage Pack instance.  This parameter is the sum of the absolute values of the Energy into and out of this HVES instance.  This parameter i...";
CM_ SG_ 2633718270 HVESP1TotalAccumulatedCharge "HVESP1 Total Accumulated Charge: The total accumulated amp hours which have flowed through this High Voltage Energy Storage Pack instance.  This parameter is the sum of the absolute values of the Ampere hours into and out of this HVES instance.  This...";
CM_ BO_ 2566609662 "High Voltage Energy Storage Pack 1 Configuration";
CM_ SG_ 2566609662 HVESP1NominalVoltage "HVESP1 Nominal Voltage: Per the HVES manufacturer, this is the nominal operating voltage of this High Voltage Energy Storage Pack instance, e.g. “300V” or “600V”.This parameter is for one of multiple packs in an HVESS.  If there is only one pack in t...";
CM_ SG_ 2566609662 HVESP1RmmnddMnmmOprtngVltg "HVESP1 Recommended Minimum Operating Voltage: Per the HVES manufacturer, this is the minimum recommended voltage level for this High Voltage Energy Storage Pack instance operation.  Operating below this value may compromise HVES life.This parameter i...";
CM_ SG_ 2566609662 HVESP1RmmnddMxmmOprtngVltg "HVESP1 Recommended Maximum Operating Voltage: Per the HVES manufacturer, this is the maximum recommended voltage level for this High Voltage Energy Storage Pack instance operation.  Operating above this value may compromise HVES life.This parameter i...";
CM_ SG_ 2566609662 HVESP1RmmnddMnmmSttOfChrg "HVESP1 Recommended Minimum State Of Charge: Per the HVES manufacturer, this is the recommended minimum state of charge for this High Voltage Energy Storage Pack instance operation.  Operating below this value may compromise HVES life.This parameter i...";
CM_ SG_ 2566609662 HVESP1RmmnddMxmmSttOfChrg "HVESP1 Recommended Maximum State Of Charge: Per the HVES manufacturer, this is the recommended maximum state of charge for this High Voltage Energy Storage Pack instance operation.  Operating above this value may compromise HVES life.This parameter i...";
CM_ SG_ 2566609662 HVESP1RmmnddMxmmOprtngTmprtr "HVESP1 Recommended Maximum Operating Temperature: Per the HVES manufacturer, this is the recommended maximum temperature for this High Voltage Energy Storage Pack instance operation.  Operating above this value may damage HVES hardware, or compromise...";
CM_ SG_ 2566609662 HVESP1RmmnddMnmmOprtngTmprtr "HVESP1 Recommended Minimum Operating Temperature: Per the HVES manufacturer, this is the recommended minimum temperature for this High Voltage Energy Storage Pack instance operation.  Operating below this value may damage HVES hardware, or compromise...";
CM_ SG_ 2566609662 HVESP1CellMaximumVoltageLimit "HVESP1 Cell Maximum Voltage Limit: Per the HVES manufacturer, this is the maximum cell voltage for this High Voltage Energy Storage Pack instance operation.  Operating above this value may damage HVES hardware, or compromise HVES life.This parameter ...";
CM_ SG_ 2566609662 HVESP1CellMinimumVoltageLimit "HVESP1 Cell Minimum Voltage Limit: Per the HVES manufacturer, this is the minimum cell voltage for this High Voltage Energy Storage Pack instance operation.  Operating below this value may damage HVES hardware, or compromise HVES life.This parameter ...";
CM_ BO_ 2633718782 "Vehicle Fire Suppression System Module 1 Detector Data";
CM_ SG_ 2633718782 VFSSMdl1Dttr1DttrTp "VFSS Module 1 Detector 1 Detector Type: The type of detector for detector 1 of module 1.0 = Analog thermal sensor1 = Analog gas sensor2 = Analog optical sensor3 = Heat detector4 = Manual release switch5 = SAE Reserved6 = SAE Reserved7 = SAE Reserved8...";
CM_ SG_ 2633718782 VFSSMdl1Dttr1DttrDtSLOT "VFSS Module 1 Detector 1 Detector Data SLOT: The SAE SLOT encoding used for data reported in SPN 10847 (VFSS Module 1 Detector 1 Data) for this detector instance of this module.0 = SAEev03 (voltage)1 = SAEpc07 (percent)2 = SAEtp02 (temperature)3 = SA...";
CM_ SG_ 2633718782 VFSSMdl1Dttr2DttrTp "VFSS Module 1 Detector 2 Detector Type: The type of detector for detector 2 of module 1.0 = Analog thermal sensor1 = Analog gas sensor2 = Analog optical sensor3 = Heat detector4 = Manual release switch5 = SAE Reserved6 = SAE Reserved7 = SAE Reserved8...";
CM_ SG_ 2633718782 VFSSMdl1Dttr2DttrDtSLOT "VFSS Module 1 Detector 2 Detector Data SLOT: The SAE SLOT encoding used for data reported in SPN 10848 (VFSS Module 1 Detector 2 Data) for this detector instance of this module.0 = SAEev03 (voltage)1 = SAEpc07 (percent)2 = SAEtp02 (temperature)3 = SA...";
CM_ SG_ 2633718782 VFSSMdl1Dttr3DttrTp "VFSS Module 1 Detector 3 Detector Type: The type of detector for detector 3 of module 1.0 = Analog thermal sensor1 = Analog gas sensor2 = Analog optical sensor3 = Heat detector4 = Manual release switch5 = SAE Reserved6 = SAE Reserved7 = SAE Reserved8...";
CM_ SG_ 2633718782 VFSSMdl1Dttr3DttrDtSLOT "VFSS Module 1 Detector 3 Detector Data SLOT: The SAE SLOT encoding used for data reported in SPN 10853 (VFSS Module 1 Detector 3 Data) for this detector instance of this module.0 = SAEev03 (voltage)1 = SAEpc07 (percent)2 = SAEtp02 (temperature)3 = SA...";
CM_ SG_ 2633718782 VFSSMdl1Dttr4DttrTp "VFSS Module 1 Detector 4 Detector Type: The type of detector for detector 4 of module 1.0 = Analog thermal sensor1 = Analog gas sensor2 = Analog optical sensor3 = Heat detector4 = Manual release switch5 = SAE Reserved6 = SAE Reserved7 = SAE Reserved8...";
CM_ SG_ 2633718782 VFSSMdl1Dttr4DttrDtSLOT "VFSS Module 1 Detector 4 Detector Data SLOT: The SAE SLOT encoding used for data reported in SPN 10856 (VFSS Module 1 Detector 4 Data) for this detector instance of this module.0 = SAEev03 (voltage)1 = SAEpc07 (percent)2 = SAEtp02 (temperature)3 = SA...";
CM_ SG_ 2633718782 VFSSMdl1Dttr5DttrTp "VFSS Module 1 Detector 5 Detector Type: The type of detector for detector 5 of module 1.0 = Analog thermal sensor1 = Analog gas sensor2 = Analog optical sensor3 = Heat detector4 = Manual release switch5 = SAE Reserved6 = SAE Reserved7 = SAE Reserved8...";
CM_ SG_ 2633718782 VFSSMdl1Dttr5DttrDtSLOT "VFSS Module 1 Detector 5 Detector Data SLOT: The SAE SLOT encoding used for data reported in SPN 10859 (VFSS Module 1 Detector 5 Data) for this detector instance of this module.0 = SAEev03 (voltage)1 = SAEpc07 (percent)2 = SAEtp02 (temperature)3 = SA...";
CM_ SG_ 2633718782 VFSSMdl1Dttr6DttrTp "VFSS Module 1 Detector 6 Detector Type: The type of detector for detector 6 of module 1.0 = Analog thermal sensor1 = Analog gas sensor2 = Analog optical sensor3 = Heat detector4 = Manual release switch5 = SAE Reserved6 = SAE Reserved7 = SAE Reserved8...";
CM_ SG_ 2633718782 VFSSMdl1Dttr6DttrDtSLOT "VFSS Module 1 Detector 6 Detector Data SLOT: The SAE SLOT encoding used for data reported in SPN 10861 (VFSS Module 1 Detector 6 Data) for this detector instance of this module.0 = SAEev03 (voltage)1 = SAEpc07 (percent)2 = SAEtp02 (temperature)3 = SA...";
CM_ SG_ 2633718782 VFSSMdl1Dttr7DttrTp "VFSS Module 1 Detector 7 Detector Type: The type of detector for detector 7 of module 1.0 = Analog thermal sensor1 = Analog gas sensor2 = Analog optical sensor3 = Heat detector4 = Manual release switch5 = SAE Reserved6 = SAE Reserved7 = SAE Reserved8...";
CM_ SG_ 2633718782 VFSSMdl1Dttr7DttrDtSLOT "VFSS Module 1 Detector 7 Detector Data SLOT: The SAE SLOT encoding used for data reported in SPN 10865 (VFSS Module 1 Detector 7 Data) for this detector instance of this module.0 = SAEev03 (voltage)1 = SAEpc07 (percent)2 = SAEtp02 (temperature)3 = SA...";
CM_ SG_ 2633718782 VFSSMdl1Dttr8DttrTp "VFSS Module 1 Detector 8 Detector Type: The type of detector for detector 8 of module 1.0 = Analog thermal sensor1 = Analog gas sensor2 = Analog optical sensor3 = Heat detector4 = Manual release switch5 = SAE Reserved6 = SAE Reserved7 = SAE Reserved8...";
CM_ SG_ 2633718782 VFSSMdl1Dttr8DttrDtSLOT "VFSS Module 1 Detector 8 Detector Data SLOT: The SAE SLOT encoding used for data reported in SPN 10868 (VFSS Module 1 Detector 8 Data) for this detector instance of this module.0 = SAEev03 (voltage)1 = SAEpc07 (percent)2 = SAEtp02 (temperature)3 = SA...";
CM_ BO_ 2633719038 "Vehicle Fire Suppression System Module 2 Detector Data";
CM_ SG_ 2633719038 VFSSMdl2Dttr1DttrTp "VFSS Module 2 Detector 1 Detector Type: The type of detector for detector 1 of module 2.0 = Analog thermal sensor1 = Analog gas sensor2 = Analog optical sensor3 = Heat detector4 = Manual release switch5 = SAE Reserved6 = SAE Reserved7 = SAE Reserved8...";
CM_ SG_ 2633719038 VFSSMdl2Dttr1DttrDtSLOT "VFSS Module 2 Detector 1 Detector Data SLOT: The SAE SLOT encoding used for data reported in SPN 10871 (VFSS Module 2 Detector 1 Data) for this detector instance of this module.0 = SAEev03 (voltage)1 = SAEpc07 (percent)2 = SAEtp02 (temperature)3 = SA...";
CM_ SG_ 2633719038 VFSSMdl2Dttr2DttrTp "VFSS Module 2 Detector 2 Detector Type: The type of detector for detector 2 of module 2.0 = Analog thermal sensor1 = Analog gas sensor2 = Analog optical sensor3 = Heat detector4 = Manual release switch5 = SAE Reserved6 = SAE Reserved7 = SAE Reserved8...";
CM_ SG_ 2633719038 VFSSMdl2Dttr2DttrDtSLOT "VFSS Module 2 Detector 2 Detector Data SLOT: The SAE SLOT encoding used for data reported in SPN 10871 (VFSS Module 2 Detector 2 Data) for this detector instance of this module.0 = SAEev03 (voltage)1 = SAEpc07 (percent)2 = SAEtp02 (temperature)3 = SA...";
CM_ SG_ 2633719038 VFSSMdl2Dttr3DttrTp "VFSS Module 2 Detector 3 Detector Type: The type of detector for detector 3 of module 2.0 = Analog thermal sensor1 = Analog gas sensor2 = Analog optical sensor3 = Heat detector4 = Manual release switch5 = SAE Reserved6 = SAE Reserved7 = SAE Reserved8...";
CM_ SG_ 2633719038 VFSSMdl2Dttr3DttrDtSLOT "VFSS Module 2 Detector 3 Detector Data SLOT: The SAE SLOT encoding used for data reported in SPN 10871 (VFSS Module 2 Detector 3 Data) for this detector instance of this module.0 = SAEev03 (voltage)1 = SAEpc07 (percent)2 = SAEtp02 (temperature)3 = SA...";
CM_ SG_ 2633719038 VFSSMdl2Dttr4DttrTp "VFSS Module 2 Detector 4 Detector Type: The type of detector for detector 4 of module 2.0 = Analog thermal sensor1 = Analog gas sensor2 = Analog optical sensor3 = Heat detector4 = Manual release switch5 = SAE Reserved6 = SAE Reserved7 = SAE Reserved8...";
CM_ SG_ 2633719038 VFSSMdl2Dttr4DttrDtSLOT "VFSS Module 2 Detector 4 Detector Data SLOT: The SAE SLOT encoding used for data reported in SPN 10871 (VFSS Module 2 Detector 4 Data) for this detector instance of this module.0 = SAEev03 (voltage)1 = SAEpc07 (percent)2 = SAEtp02 (temperature)3 = SA...";
CM_ SG_ 2633719038 VFSSMdl2Dttr5DttrTp "VFSS Module 2 Detector 5 Detector Type: The type of detector for detector 5 of module 2.0 = Analog thermal sensor1 = Analog gas sensor2 = Analog optical sensor3 = Heat detector4 = Manual release switch5 = SAE Reserved6 = SAE Reserved7 = SAE Reserved8...";
CM_ SG_ 2633719038 VFSSMdl2Dttr5DttrDtSLOT "VFSS Module 2 Detector 5 Detector Data SLOT: The SAE SLOT encoding used for data reported in SPN 10871 (VFSS Module 2 Detector 5 Data) for this detector instance of this module.0 = SAEev03 (voltage)1 = SAEpc07 (percent)2 = SAEtp02 (temperature)3 = SA...";
CM_ SG_ 2633719038 VFSSMdl2Dttr6DttrTp "VFSS Module 2 Detector 6 Detector Type: The type of detector for detector 6 of module 2.0 = Analog thermal sensor1 = Analog gas sensor2 = Analog optical sensor3 = Heat detector4 = Manual release switch5 = SAE Reserved6 = SAE Reserved7 = SAE Reserved8...";
CM_ SG_ 2633719038 VFSSMdl2Dttr6DttrDtSLOT "VFSS Module 2 Detector 6 Detector Data SLOT: The SAE SLOT encoding used for data reported in SPN 10871 (VFSS Module 2 Detector 6 Data) for this detector instance of this module.0 = SAEev03 (voltage)1 = SAEpc07 (percent)2 = SAEtp02 (temperature)3 = SA...";
CM_ SG_ 2633719038 VFSSMdl2Dttr7DttrTp "VFSS Module 2 Detector 7 Detector Type: The type of detector for detector 7 of module 2.0 = Analog thermal sensor1 = Analog gas sensor2 = Analog optical sensor3 = Heat detector4 = Manual release switch5 = SAE Reserved6 = SAE Reserved7 = SAE Reserved8...";
CM_ SG_ 2633719038 VFSSMdl2Dttr7DttrDtSLOT "VFSS Module 2 Detector 7 Detector Data SLOT: The SAE SLOT encoding used for data reported in SPN 10871 (VFSS Module 2 Detector 7 Data) for this detector instance of this module.0 = SAEev03 (voltage)1 = SAEpc07 (percent)2 = SAEtp02 (temperature)3 = SA...";
CM_ SG_ 2633719038 VFSSMdl2Dttr8DttrTp "VFSS Module 2 Detector 8 Detector Type: The type of detector for detector 8 of module 2.0 = Analog thermal sensor1 = Analog gas sensor2 = Analog optical sensor3 = Heat detector4 = Manual release switch5 = SAE Reserved6 = SAE Reserved7 = SAE Reserved8...";
CM_ SG_ 2633719038 VFSSMdl2Dttr8DttrDtSLOT "VFSS Module 2 Detector 8 Detector Data SLOT: The SAE SLOT encoding used for data reported in SPN 10871 (VFSS Module 2 Detector 8 Data) for this detector instance of this module.0 = SAEev03 (voltage)1 = SAEpc07 (percent)2 = SAEtp02 (temperature)3 = SA...";
CM_ BO_ 2633719294 "Vehicle Fire Suppression System Module 3 Detector Data";
CM_ SG_ 2633719294 VFSSMdl3Dttr1DttrTp "VFSS Module 3 Detector 1 Detector Type: The type of detector for detector 1 of module 3.0 = Analog thermal sensor1 = Analog gas sensor2 = Analog optical sensor3 = Heat detector4 = Manual release switch5 = SAE Reserved6 = SAE Reserved7 = SAE Reserved8...";
CM_ SG_ 2633719294 VFSSMdl3Dttr1DttrDtSLOT "VFSS Module 3 Detector 1 Detector Data SLOT: The SAE SLOT encoding used for data reported in SPN 10871 (VFSS Module 3 Detector 1 Data) for this detector instance of this module.0 = SAEev03 (voltage)1 = SAEpc07 (percent)2 = SAEtp02 (temperature)3 = SA...";
CM_ SG_ 2633719294 VFSSMdl3Dttr2DttrTp "VFSS Module 3 Detector 2 Detector Type: The type of detector for detector 2 of module 3.0 = Analog thermal sensor1 = Analog gas sensor2 = Analog optical sensor3 = Heat detector4 = Manual release switch5 = SAE Reserved6 = SAE Reserved7 = SAE Reserved8...";
CM_ SG_ 2633719294 VFSSMdl3Dttr2DttrDtSLOT "VFSS Module 3 Detector 2 Detector Data SLOT: The SAE SLOT encoding used for data reported in SPN 10871 (VFSS Module 3 Detector 2 Data) for this detector instance of this module.0 = SAEev03 (voltage)1 = SAEpc07 (percent)2 = SAEtp02 (temperature)3 = SA...";
CM_ SG_ 2633719294 VFSSMdl3Dttr3DttrTp "VFSS Module 3 Detector 3 Detector Type: The type of detector for detector 3 of module 3.0 = Analog thermal sensor1 = Analog gas sensor2 = Analog optical sensor3 = Heat detector4 = Manual release switch5 = SAE Reserved6 = SAE Reserved7 = SAE Reserved8...";
CM_ SG_ 2633719294 VFSSMdl3Dttr3DttrDtSLOT "VFSS Module 3 Detector 3 Detector Data SLOT: The SAE SLOT encoding used for data reported in SPN 10871 (VFSS Module 3 Detector 3 Data) for this detector instance of this module.0 = SAEev03 (voltage)1 = SAEpc07 (percent)2 = SAEtp02 (temperature)3 = SA...";
CM_ SG_ 2633719294 VFSSMdl3Dttr4DttrTp "VFSS Module 3 Detector 4 Detector Type: The type of detector for detector 4 of module 3.0 = Analog thermal sensor1 = Analog gas sensor2 = Analog optical sensor3 = Heat detector4 = Manual release switch5 = SAE Reserved6 = SAE Reserved7 = SAE Reserved8...";
CM_ SG_ 2633719294 VFSSMdl3Dttr4DttrDtSLOT "VFSS Module 3 Detector 4 Detector Data SLOT: The SAE SLOT encoding used for data reported in SPN 10871 (VFSS Module 3 Detector 4 Data) for this detector instance of this module.0 = SAEev03 (voltage)1 = SAEpc07 (percent)2 = SAEtp02 (temperature)3 = SA...";
CM_ SG_ 2633719294 VFSSMdl3Dttr5DttrTp "VFSS Module 3 Detector 5 Detector Type: The type of detector for detector 5 of module 3.0 = Analog thermal sensor1 = Analog gas sensor2 = Analog optical sensor3 = Heat detector4 = Manual release switch5 = SAE Reserved6 = SAE Reserved7 = SAE Reserved8...";
CM_ SG_ 2633719294 VFSSMdl3Dttr5DttrDtSLOT "VFSS Module 3 Detector 5 Detector Data SLOT: The SAE SLOT encoding used for data reported in SPN 10871 (VFSS Module 3 Detector 5 Data) for this detector instance of this module.0 = SAEev03 (voltage)1 = SAEpc07 (percent)2 = SAEtp02 (temperature)3 = SA...";
CM_ SG_ 2633719294 VFSSMdl3Dttr6DttrTp "VFSS Module 3 Detector 6 Detector Type: The type of detector for detector 6 of module 3.0 = Analog thermal sensor1 = Analog gas sensor2 = Analog optical sensor3 = Heat detector4 = Manual release switch5 = SAE Reserved6 = SAE Reserved7 = SAE Reserved8...";
CM_ SG_ 2633719294 VFSSMdl3Dttr6DttrDtSLOT "VFSS Module 3 Detector 6 Detector Data SLOT: The SAE SLOT encoding used for data reported in SPN 10871 (VFSS Module 3 Detector 6 Data) for this detector instance of this module.0 = SAEev03 (voltage)1 = SAEpc07 (percent)2 = SAEtp02 (temperature)3 = SA...";
CM_ SG_ 2633719294 VFSSMdl3Dttr7DttrTp "VFSS Module 3 Detector 7 Detector Type: The type of detector for detector 7 of module 3.0 = Analog thermal sensor1 = Analog gas sensor2 = Analog optical sensor3 = Heat detector4 = Manual release switch5 = SAE Reserved6 = SAE Reserved7 = SAE Reserved8...";
CM_ SG_ 2633719294 VFSSMdl3Dttr7DttrDtSLOT "VFSS Module 3 Detector 7 Detector Data SLOT: The SAE SLOT encoding used for data reported in SPN 10871 (VFSS Module 3 Detector 7 Data) for this detector instance of this module.0 = SAEev03 (voltage)1 = SAEpc07 (percent)2 = SAEtp02 (temperature)3 = SA...";
CM_ SG_ 2633719294 VFSSMdl3Dttr8DttrTp "VFSS Module 3 Detector 8 Detector Type: The type of detector for detector 8 of module 3.0 = Analog thermal sensor1 = Analog gas sensor2 = Analog optical sensor3 = Heat detector4 = Manual release switch5 = SAE Reserved6 = SAE Reserved7 = SAE Reserved8...";
CM_ SG_ 2633719294 VFSSMdl3Dttr8DttrDtSLOT "VFSS Module 3 Detector 8 Detector Data SLOT: The SAE SLOT encoding used for data reported in SPN 10871 (VFSS Module 3 Detector 8 Data) for this detector instance of this module.0 = SAEev03 (voltage)1 = SAEpc07 (percent)2 = SAEtp02 (temperature)3 = SA...";
CM_ BO_ 2633719550 "Vehicle Fire Suppression System Module 4 Detector Data";
CM_ SG_ 2633719550 VFSSMdl4Dttr1DttrTp "VFSS Module 4 Detector 1 Detector Type: The type of detector for detector 1 of module 4.0 = Analog thermal sensor1 = Analog gas sensor2 = Analog optical sensor3 = Heat detector4 = Manual release switch5 = SAE Reserved6 = SAE Reserved7 = SAE Reserved8...";
CM_ SG_ 2633719550 VFSSMdl4Dttr1DttrDtSLOT "VFSS Module 4 Detector 1 Detector Data SLOT: The SAE SLOT encoding used for data reported in SPN 10871 (VFSS Module 4 Detector 1 Data) for this detector instance of this module.0 = SAEev03 (voltage)1 = SAEpc07 (percent)2 = SAEtp02 (temperature)3 = SA...";
CM_ SG_ 2633719550 VFSSMdl4Dttr2DttrTp "VFSS Module 4 Detector 2 Detector Type: The type of detector for detector 2 of module 4.0 = Analog thermal sensor1 = Analog gas sensor2 = Analog optical sensor3 = Heat detector4 = Manual release switch5 = SAE Reserved6 = SAE Reserved7 = SAE Reserved8...";
CM_ SG_ 2633719550 VFSSMdl4Dttr2DttrDtSLOT "VFSS Module 4 Detector 2 Detector Data SLOT: The SAE SLOT encoding used for data reported in SPN 10871 (VFSS Module 4 Detector 2 Data) for this detector instance of this module.0 = SAEev03 (voltage)1 = SAEpc07 (percent)2 = SAEtp02 (temperature)3 = SA...";
CM_ SG_ 2633719550 VFSSMdl4Dttr3DttrTp "VFSS Module 4 Detector 3 Detector Type: The type of detector for detector 3 of module 4.0 = Analog thermal sensor1 = Analog gas sensor2 = Analog optical sensor3 = Heat detector4 = Manual release switch5 = SAE Reserved6 = SAE Reserved7 = SAE Reserved8...";
CM_ SG_ 2633719550 VFSSMdl4Dttr3DttrDtSLOT "VFSS Module 4 Detector 3 Detector Data SLOT: The SAE SLOT encoding used for data reported in SPN 10871 (VFSS Module 4 Detector 3 Data) for this detector instance of this module.0 = SAEev03 (voltage)1 = SAEpc07 (percent)2 = SAEtp02 (temperature)3 = SA...";
CM_ SG_ 2633719550 VFSSMdl4Dttr4DttrTp "VFSS Module 4 Detector 4 Detector Type: The type of detector for detector 4 of module 4.0 = Analog thermal sensor1 = Analog gas sensor2 = Analog optical sensor3 = Heat detector4 = Manual release switch5 = SAE Reserved6 = SAE Reserved7 = SAE Reserved8...";
CM_ SG_ 2633719550 VFSSMdl4Dttr4DttrDtSLOT "VFSS Module 4 Detector 4 Detector Data SLOT: The SAE SLOT encoding used for data reported in SPN 10871 (VFSS Module 4 Detector 4 Data) for this detector instance of this module.0 = SAEev03 (voltage)1 = SAEpc07 (percent)2 = SAEtp02 (temperature)3 = SA...";
CM_ SG_ 2633719550 VFSSMdl4Dttr5DttrTp "VFSS Module 4 Detector 5 Detector Type: The type of detector for detector 5 of module 4.0 = Analog thermal sensor1 = Analog gas sensor2 = Analog optical sensor3 = Heat detector4 = Manual release switch5 = SAE Reserved6 = SAE Reserved7 = SAE Reserved8...";
CM_ SG_ 2633719550 VFSSMdl4Dttr5DttrDtSLOT "VFSS Module 4 Detector 5 Detector Data SLOT: The SAE SLOT encoding used for data reported in SPN 10871 (VFSS Module 4 Detector 5 Data) for this detector instance of this module.0 = SAEev03 (voltage)1 = SAEpc07 (percent)2 = SAEtp02 (temperature)3 = SA...";
CM_ SG_ 2633719550 VFSSMdl4Dttr6DttrTp "VFSS Module 4 Detector 6 Detector Type: The type of detector for detector 6 of module 4.0 = Analog thermal sensor1 = Analog gas sensor2 = Analog optical sensor3 = Heat detector4 = Manual release switch5 = SAE Reserved6 = SAE Reserved7 = SAE Reserved8...";
CM_ SG_ 2633719550 VFSSMdl4Dttr6DttrDtSLOT "VFSS Module 4 Detector 6 Detector Data SLOT: The SAE SLOT encoding used for data reported in SPN 10871 (VFSS Module 4 Detector 6 Data) for this detector instance of this module.0 = SAEev03 (voltage)1 = SAEpc07 (percent)2 = SAEtp02 (temperature)3 = SA...";
CM_ SG_ 2633719550 VFSSMdl4Dttr7DttrTp "VFSS Module 4 Detector 7 Detector Type: The type of detector for detector 7 of module 4.0 = Analog thermal sensor1 = Analog gas sensor2 = Analog optical sensor3 = Heat detector4 = Manual release switch5 = SAE Reserved6 = SAE Reserved7 = SAE Reserved8...";
CM_ SG_ 2633719550 VFSSMdl4Dttr7DttrDtSLOT "VFSS Module 4 Detector 7 Detector Data SLOT: The SAE SLOT encoding used for data reported in SPN 10871 (VFSS Module 4 Detector 7 Data) for this detector instance of this module.0 = SAEev03 (voltage)1 = SAEpc07 (percent)2 = SAEtp02 (temperature)3 = SA...";
CM_ SG_ 2633719550 VFSSMdl4Dttr8DttrTp "VFSS Module 4 Detector 8 Detector Type: The type of detector for detector 8 of module 4.0 = Analog thermal sensor1 = Analog gas sensor2 = Analog optical sensor3 = Heat detector4 = Manual release switch5 = SAE Reserved6 = SAE Reserved7 = SAE Reserved8...";
CM_ SG_ 2633719550 VFSSMdl4Dttr8DttrDtSLOT "VFSS Module 4 Detector 8 Detector Data SLOT: The SAE SLOT encoding used for data reported in SPN 10871 (VFSS Module 4 Detector 8 Data) for this detector instance of this module.0 = SAEev03 (voltage)1 = SAEpc07 (percent)2 = SAEtp02 (temperature)3 = SA...";
CM_ BO_ 2633719806 "Vehicle Fire Suppression System Module 1 Auxilliary Data";
CM_ SG_ 2633719806 VFSSModule1HeatZone1Data "VFSS Module 1 Heat Zone 1 Data: Current measured value for heat zone 1 of module 1.";
CM_ SG_ 2633719806 VFSSModule1HeatZone2Data "VFSS Module 1 Heat Zone 2 Data: Current measured value for heat zone 2 of module 1.";
CM_ SG_ 2633719806 VFSSModule1ReleaseZone1Data "VFSS Module 1 Release Zone 1 Data: Current measured value for release zone 1 of module 1.";
CM_ SG_ 2633719806 VFSSModule1ReleaseZone2Data "VFSS Module 1 Release Zone 2 Data: Current measured value for release zone 2 of module 1.";
CM_ SG_ 2633719806 VFSSModule1PressureSwitch1Data "VFSS Module 1 Pressure Switch 1 Data: Current measured value for pressure switch 1 of module 1.";
CM_ SG_ 2633719806 VFSSModule1PressureSwitch2Data "VFSS Module 1 Pressure Switch 2 Data: Current measured value for pressure switch 2 of module 1.";
CM_ SG_ 2633719806 VFSSModule1PrimaryPowerVoltage "VFSS Module 1 Primary Power Voltage: Current measured value for primary power voltage of module 1.";
CM_ SG_ 2633719806 VFSSMdl1SndrPwrVltg "VFSS Module 1 Secondary Power Voltage: Current measured value for secondary power voltage of module 1.";
CM_ BO_ 2633720062 "Vehicle Fire Suppression System Module 2 Auxilliary Data";
CM_ SG_ 2633720062 VFSSModule2HeatZone1Data "VFSS Module 2 Heat Zone 1 Data: Current measured value for heat zone 1 of module 2.";
CM_ SG_ 2633720062 VFSSModule2HeatZone2Data "VFSS Module 2 Heat Zone 2 Data: Current measured value for heat zone 2 of module 2.";
CM_ SG_ 2633720062 VFSSModule2ReleaseZone1Data "VFSS Module 2 Release Zone 1 Data: Current measured value for release zone 1 of module 2.";
CM_ SG_ 2633720062 VFSSModule2ReleaseZone2Data "VFSS Module 2 Release Zone 2 Data: Current measured value for release zone 2 of module 2.";
CM_ SG_ 2633720062 VFSSModule2PressureSwitch1Data "VFSS Module 2 Pressure Switch 1 Data: Current measured value for pressure switch 1 of module 2.";
CM_ SG_ 2633720062 VFSSModule2PressureSwitch2Data "VFSS Module 2 Pressure Switch 2 Data: Current measured value for pressure switch 2 of module 2.";
CM_ SG_ 2633720062 VFSSModule2PrimaryPowerVoltage "VFSS Module 2 Primary Power Voltage: Current measured value for primary power voltage of module 2.";
CM_ SG_ 2633720062 VFSSMdl2SndrPwrVltg "VFSS Module 2 Secondary Power Voltage: Current measured value for secondary power voltage of module 2.";
CM_ BO_ 2633720318 "Vehicle Fire Suppression System Module 3 Auxilliary Data";
CM_ SG_ 2633720318 VFSSModule3HeatZone1Data "VFSS Module 3 Heat Zone 1 Data: Current measured value for heat zone 1 of module 3.";
CM_ SG_ 2633720318 VFSSModule3HeatZone2Data "VFSS Module 3 Heat Zone 2 Data: Current measured value for heat zone 2 of module 3.";
CM_ SG_ 2633720318 VFSSModule3ReleaseZone1Data "VFSS Module 3 Release Zone 1 Data: Current measured value for release zone 1 of module 3.";
CM_ SG_ 2633720318 VFSSModule3ReleaseZone2Data "VFSS Module 3 Release Zone 2 Data: Current measured value for release zone 2 of module 3.";
CM_ SG_ 2633720318 VFSSModule3PressureSwitch1Data "VFSS Module 3 Pressure Switch 1 Data: Current measured value for pressure switch 1 of module 3.";
CM_ SG_ 2633720318 VFSSModule3PressureSwitch2Data "VFSS Module 3 Pressure Switch 2 Data: Current measured value for pressure switch 2 of module 3.";
CM_ SG_ 2633720318 VFSSModule3PrimaryPowerVoltage "VFSS Module 3 Primary Power Voltage: Current measured value for primary power voltage of module 3.";
CM_ SG_ 2633720318 VFSSMdl3SndrPwrVltg "VFSS Module 3 Secondary Power Voltage: Current measured value for secondary power voltage of module 3.";
CM_ BO_ 2633720574 "Vehicle Fire Suppression System Module 4 Auxilliary Data";
CM_ SG_ 2633720574 VFSSModule4HeatZone1Data "VFSS Module 4 Heat Zone 1 Data: Current measured value for heat zone 1 of module 4.";
CM_ SG_ 2633720574 VFSSModule4HeatZone2Data "VFSS Module 4 Heat Zone 2 Data: Current measured value for heat zone 2 of module 4.";
CM_ SG_ 2633720574 VFSSModule4ReleaseZone1Data "VFSS Module 4 Release Zone 1 Data: Current measured value for release zone 1 of module 4.";
CM_ SG_ 2633720574 VFSSModule4ReleaseZone2Data "VFSS Module 4 Release Zone 2 Data: Current measured value for release zone 2 of module 4.";
CM_ SG_ 2633720574 VFSSModule4PressureSwitch1Data "VFSS Module 4 Pressure Switch 1 Data: Current measured value for pressure switch 1 of module 4.";
CM_ SG_ 2633720574 VFSSModule4PressureSwitch2Data "VFSS Module 4 Pressure Switch 2 Data: Current measured value for pressure switch 2 of module 4.";
CM_ SG_ 2633720574 VFSSModule4PrimaryPowerVoltage "VFSS Module 4 Primary Power Voltage: Current measured value for primary power voltage of module 4.";
CM_ SG_ 2633720574 VFSSMdl4SndrPwrVltg "VFSS Module 4 Secondary Power Voltage: Current measured value for secondary power voltage of module 4.";
CM_ BO_ 2633720830 "Vehicle Fire Suppression System Module 1 Names";
CM_ SG_ 2633720830 VFSSModule1Name "VFSS Module 1 Name: Descriptive name for the VFSS module/zone 1.";
CM_ SG_ 2633720830 VFSSModule1DetectorZone1Name "VFSS Module 1 Detector Zone 1 Name: Descriptive name for detector zone 1 of module 1.";
CM_ SG_ 2633720830 VFSSModule1DetectorZone2Name "VFSS Module 1 Detector Zone 2 Name: Descriptive name for detector zone 2 of module 1.";
CM_ SG_ 2633720830 VFSSModule1DetectorZone3Name "VFSS Module 1 Detector Zone 3 Name: Descriptive name for detector zone 3 of module 1.";
CM_ SG_ 2633720830 VFSSModule1DetectorZone4Name "VFSS Module 1 Detector Zone 4 Name: Descriptive name for detector zone 4 of module 1.";
CM_ SG_ 2633720830 VFSSModule1DetectorZone5Name "VFSS Module 1 Detector Zone 5 Name: Descriptive name for detector zone 5 of module 1.";
CM_ SG_ 2633720830 VFSSModule1DetectorZone6Name "VFSS Module 1 Detector Zone 6 Name: Descriptive name for detector zone 6 of module 1.";
CM_ SG_ 2633720830 VFSSModule1DetectorZone7Name "VFSS Module 1 Detector Zone 7 Name: Descriptive name for detector zone 7 of module 1.";
CM_ SG_ 2633720830 VFSSModule1DetectorZone8Name "VFSS Module 1 Detector Zone 8 Name: Descriptive name for detector zone 8 of module 1.";
CM_ SG_ 2633720830 VFSSModule1HeatZone1Name "VFSS Module 1 Heat Zone 1 Name: Descriptive name for heat zone 1 of module 1.";
CM_ SG_ 2633720830 VFSSModule1HeatZone2Name "VFSS Module 1 Heat Zone 2 Name: Descriptive name for heat zone 2 of module 1.";
CM_ SG_ 2633720830 VFSSModule1ReleaseZone1Name "VFSS Module 1 Release Zone 1 Name: Descriptive name for release zone 1 of module 1.";
CM_ SG_ 2633720830 VFSSModule1ReleaseZone2Name "VFSS Module 1 Release Zone 2 Name: Descriptive name for release zone 2 of module 1.";
CM_ BO_ 2633721086 "Vehicle Fire Suppression System Module 2 Names";
CM_ SG_ 2633721086 VFSSModule2Name "VFSS Module 2 Name: Descriptive name for the VFSS module/zone 2.";
CM_ SG_ 2633721086 VFSSModule2DetectorZone1Name "VFSS Module 2 Detector Zone 1 Name: Descriptive name for detector zone 1 of module 2.";
CM_ SG_ 2633721086 VFSSModule2DetectorZone2Name "VFSS Module 2 Detector Zone 2 Name: Descriptive name for detector zone 2 of module 2.";
CM_ SG_ 2633721086 VFSSModule2DetectorZone3Name "VFSS Module 2 Detector Zone 3 Name: Descriptive name for detector zone 3 of module 2.";
CM_ SG_ 2633721086 VFSSModule2DetectorZone4Name "VFSS Module 2 Detector Zone 4 Name: Descriptive name for detector zone 4 of module 2.";
CM_ SG_ 2633721086 VFSSModule2DetectorZone5Name "VFSS Module 2 Detector Zone 5 Name: Descriptive name for detector zone 5 of module 2.";
CM_ SG_ 2633721086 VFSSModule2DetectorZone6Name "VFSS Module 2 Detector Zone 6 Name: Descriptive name for detector zone 6 of module 2.";
CM_ SG_ 2633721086 VFSSModule2DetectorZone7Name "VFSS Module 2 Detector Zone 7 Name: Descriptive name for detector zone 7 of module 2.";
CM_ SG_ 2633721086 VFSSModule2DetectorZone8Name "VFSS Module 2 Detector Zone 8 Name: Descriptive name for detector zone 8 of module 2.";
CM_ SG_ 2633721086 VFSSModule2HeatZone1Name "VFSS Module 2 Heat Zone 1 Name: Descriptive name for heat zone 1 of module 2.";
CM_ SG_ 2633721086 VFSSModule2HeatZone2Name "VFSS Module 2 Heat Zone 2 Name: Descriptive name for heat zone 2 of module 2.";
CM_ SG_ 2633721086 VFSSModule2ReleaseZone1Name "VFSS Module 2 Release Zone 1 Name: Descriptive name for release zone 1 of module 2.";
CM_ SG_ 2633721086 VFSSModule2ReleaseZone2Name "VFSS Module 2 Release Zone 2 Name: Descriptive name for release zone 2 of module 2.";
CM_ BO_ 2633721342 "Vehicle Fire Suppression System Module 3 Names";
CM_ SG_ 2633721342 VFSSModule3Name "VFSS Module 3 Name: Descriptive name for the VFSS module/zone 3.";
CM_ SG_ 2633721342 VFSSModule3DetectorZone1Name "VFSS Module 3 Detector Zone 1 Name: Descriptive name for detector zone 1 of module 3.";
CM_ SG_ 2633721342 VFSSModule3DetectorZone2Name "VFSS Module 3 Detector Zone 2 Name: Descriptive name for detector zone 2 of module 3.";
CM_ SG_ 2633721342 VFSSModule3DetectorZone3Name "VFSS Module 3 Detector Zone 3 Name: Descriptive name for detector zone 3 of module 3.";
CM_ SG_ 2633721342 VFSSModule3DetectorZone4Name "VFSS Module 3 Detector Zone 4 Name: Descriptive name for detector zone 4 of module 3.";
CM_ SG_ 2633721342 VFSSModule3DetectorZone5Name "VFSS Module 3 Detector Zone 5 Name: Descriptive name for detector zone 5 of module 3.";
CM_ SG_ 2633721342 VFSSModule3DetectorZone6Name "VFSS Module 3 Detector Zone 6 Name: Descriptive name for detector zone 6 of module 3.";
CM_ SG_ 2633721342 VFSSModule3DetectorZone7Name "VFSS Module 3 Detector Zone 7 Name: Descriptive name for detector zone 7 of module 3.";
CM_ SG_ 2633721342 VFSSModule3DetectorZone8Name "VFSS Module 3 Detector Zone 8 Name: Descriptive name for detector zone 8 of module 3.";
CM_ SG_ 2633721342 VFSSModule3HeatZone1Name "VFSS Module 3 Heat Zone 1 Name: Descriptive name for heat zone 1 of module 3.";
CM_ SG_ 2633721342 VFSSModule3HeatZone2Name "VFSS Module 3 Heat Zone 2 Name: Descriptive name for heat zone 2 of module 3.";
CM_ SG_ 2633721342 VFSSModule3ReleaseZone1Name "VFSS Module 3 Release Zone 1 Name: Descriptive name for release zone 1 of module 3.";
CM_ SG_ 2633721342 VFSSModule3ReleaseZone2Name "VFSS Module 3 Release Zone 2 Name: Descriptive name for release zone 2 of module 3.";
CM_ BO_ 2633721598 "Vehicle Fire Suppression System Module 4 Names";
CM_ SG_ 2633721598 VFSSModule4Name "VFSS Module 4 Name: Descriptive name for the VFSS module/zone 4.";
CM_ SG_ 2633721598 VFSSModule4DetectorZone1Name "VFSS Module 4 Detector Zone 1 Name: Descriptive name for detector zone 1 of module 4.";
CM_ SG_ 2633721598 VFSSModule4DetectorZone2Name "VFSS Module 4 Detector Zone 2 Name: Descriptive name for detector zone 2 of module 4.";
CM_ SG_ 2633721598 VFSSModule4DetectorZone3Name "VFSS Module 4 Detector Zone 3 Name: Descriptive name for detector zone 3 of module 4.";
CM_ SG_ 2633721598 VFSSModule4DetectorZone4Name "VFSS Module 4 Detector Zone 4 Name: Descriptive name for detector zone 4 of module 4.";
CM_ SG_ 2633721598 VFSSModule4DetectorZone5Name "VFSS Module 4 Detector Zone 5 Name: Descriptive name for detector zone 5 of module 4.";
CM_ SG_ 2633721598 VFSSModule4DetectorZone6Name "VFSS Module 4 Detector Zone 6 Name: Descriptive name for detector zone 6 of module 4.";
CM_ SG_ 2633721598 VFSSModule4DetectorZone7Name "VFSS Module 4 Detector Zone 7 Name: Descriptive name for detector zone 7 of module 4.";
CM_ SG_ 2633721598 VFSSModule4DetectorZone8Name "VFSS Module 4 Detector Zone 8 Name: Descriptive name for detector zone 8 of module 4.";
CM_ SG_ 2633721598 VFSSModule4HeatZone1Name "VFSS Module 4 Heat Zone 1 Name: Descriptive name for heat zone 1 of module 4.";
CM_ SG_ 2633721598 VFSSModule4HeatZone2Name "VFSS Module 4 Heat Zone 2 Name: Descriptive name for heat zone 2 of module 4.";
CM_ SG_ 2633721598 VFSSModule4ReleaseZone1Name "VFSS Module 4 Release Zone 1 Name: Descriptive name for release zone 1 of module 4.";
CM_ SG_ 2633721598 VFSSModule4ReleaseZone2Name "VFSS Module 4 Release Zone 2 Name: Descriptive name for release zone 2 of module 4.";
CM_ BO_ 2566612990 "Motor/Generator 2 Inverter Active Power Limits";
CM_ SG_ 2566612990 MtGt2IvtPwLtddtUddRs "Motor/Generator 2 Inverter Power Limited due to Undefined Reason: Output power is being limited due to an undefined reason.00b = No power limit for this reason01b = Power limited for this reason10b = Error11b = Not Available";
CM_ SG_ 2566612990 MtGt2IvtPwLtddtDCSdCtMx "Motor/Generator 2 Inverter Power Limited due to DC Side Current Maximum: Output power is being limited due to SPN 10241 [Inverter DC Side Current] approaching or exceeding the SPN 10280 [Inverter Limits Active DC Side Current Maximum].00b = No power ...";
CM_ SG_ 2566612990 MtGt2IvtPwLtddtDCSdCtM "Motor/Generator 2 Inverter Power Limited due to DC Side Current Minimum: Output power is being limited due to SPN 10241 [Inverter DC Side Current] approaching or falling below the SPN 10281 [Inverter Limits Active DC Side Current Minimum].00b = No po...";
CM_ SG_ 2566612990 MtGt2IvtPwLtddtDCSdVtMx "Motor/Generator 2 Inverter Power Limited due to DC Side Voltage Maximum: Output power is being limited due to SPN 9102 [Inverter DC Side Voltage] approaching or exceeding the SPN 10278 [Inverter Limits Active DC Side Voltage Maximum].00b = No power l...";
CM_ SG_ 2566612990 MtGt2IvtPwLtddtDCSdVtM "Motor/Generator 2 Inverter Power Limited due to DC Side Voltage Minimum: Output power is being limited due to SPN 9102 [Inverter DC Side Voltage] approaching or falling below the SPN 10279 [Inverter Limits Active DC Side Voltage Minimum].00b = No pow...";
CM_ SG_ 2566612990 MtGt2IvtPwLtddtMPwMx "Motor/Generator 2 Inverter Power Limited due to Mechanical Power Maximum: Output power is being limited due to Mechanical Power (product of SPN 9062 [Torque] and SPN 9058 [Speed]) approaching or exceeding the SPN 10250 [Inverter Limits Active Mechani...";
CM_ SG_ 2566612990 MtGt2IvtPwLtddtMPwM "Motor/Generator 2 Inverter Power Limited due to Mechanical Power Minimum: Output power is being limited due to Mechanical Power (product of SPN 9062 [Torque] and SPN 9058 [Speed]) approaching or falling below the SPN 10251 [Inverter Limits Active Mec...";
CM_ SG_ 2566612990 MtGt2IvtPwLtddtDCSdPwMx "Motor/Generator 2 Inverter Power Limited due to DC Side Power Maximum: Output power is being limited due to DC Side Power (product of SPN 10241 [Inverter DC Side Current] and SPN 9102 [Inverter DC Side Voltage]) approaching or exceeding the SPN 10252...";
CM_ SG_ 2566612990 MtGt2IvtPwLtddtDCSdPwM "Motor/Generator 2 Inverter Power Limited due to DC Side Power Minimum: Output power is being limited due to DC Side Power (product of SPN 10241 [Inverter DC Side Current] and SPN 9102 [Inverter DC Side Voltage]) approaching or falling below the SPN 1...";
CM_ SG_ 2566612990 MtrGnrtr2InvrtrPwrLmtddtTrqMxmm "Motor/Generator 2 Inverter Power Limited due to Torque Maximum: Output power is being limited due to SPN 9062 [Torque] approaching or exceeding the SPN 10262 [Inverter Limits Active Torque Maximum].00b = No power limit for this reason01b = Power limi...";
CM_ SG_ 2566612990 MtrGnrtr2InvrtrPwrLmtddtTrqMnmm "Motor/Generator 2 Inverter Power Limited due to Torque Minimum: Output power is being limited due to SPN 9062 [Torque] approaching or falling below the SPN 10263 [Inverter Limits Active Torque Minimum].00b = No power limit for this reason01b = Power ...";
CM_ SG_ 2566612990 MtrGnrtr2InvrtrPwrLmtddtSpdMxmm "Motor/Generator 2 Inverter Power Limited due to Speed Maximum: Output power is being limited due to SPN 9058 [Speed] approaching or exceeding the SPN 10264 [Inverter Limits Active Speed Maximum].00b = No power limit for this reason01b = Power limited...";
CM_ SG_ 2566612990 MtrGnrtr2InvrtrPwrLmtddtSpdMnmm "Motor/Generator 2 Inverter Power Limited due to Speed Minimum: Output power is being limited due to SPN 9058 [Speed] approaching or falling below the SPN 10265 [Inverter Limits Active Speed Minimum].00b = No power limit for this reason01b = Power lim...";
CM_ SG_ 2566612990 MtGt2IvtPwLtddtIvtTpt "Motor/Generator 2 Inverter Power Limited due to Inverter Temperature: Output power is being limited due to one or more inverter temperature(s), see SPNs 10282 through 10285 [Inverter Temperature 1-4] approaching or exceeding internally defined limit(...";
CM_ SG_ 2566612990 MtGt2IvtPwLtddtMtTpt "Motor/Generator 2 Inverter Power Limited due to Motor Temperature: Output power is being limited due to one or more motor temperature(s), see SPNs 9060 and 10286 through 10288 [Motor Temperature 1-4] approaching or exceeding internally defined limit(...";
CM_ BO_ 2566613246 "Motor/Generator 2 Inverter Isolation Integrity";
CM_ SG_ 2566613246 MtrGnrtr2InvrtrIsltnIntgrtCRC "Motor/Generator 2 Inverter Isolation Integrity CRC: The CRC is defined as follows:• Length: 8 bits• Polynomial: x^8+x^5+x^3+x^2+x+1• Initial Value: FFh• Input Data Reflection: Not reflected• Result Data Reflection: Not reflected• XOR value: FFhSAE ma...";
CM_ SG_ 2566613246 MtrGnrtr2InvrtrIsltnIntgrtCntr "Motor/Generator 2 Inverter Isolation Integrity Counter: The message counter is used to detect situations where the transmitting ECU malfunction repeats the same frame all the time. The receiver of the information may use the counter parameter to dete...";
CM_ SG_ 2566613246 MtGt2IvtDCSdNtvtCsssGdVt "Motor/Generator 2 Inverter DC Side Negative to Chassis Ground Voltage: The voltage level of the high voltage DC side, as measured by the inverter between the negative side of the High Voltage DC Side input and the chassis of the inverter enclosure.  ...";
CM_ SG_ 2566613246 MtGt2IvtHVtBsAtvIstTstStts "Motor/Generator 2 Inverter High-Voltage Bus Active Isolation Test Status: Status of the high-voltage bus electrical active isolation test as performed by this instance of the motor/generator.0000b = No test requested / No test in process0001b = Test ...";
CM_ SG_ 2566613246 MtGt2IvtHVtBsPssvIstTstStts "Motor/Generator 2 Inverter High-Voltage Bus Passive Isolation Test Status: Status of the high-voltage bus electrical passive isolation test as performed by this instance of the Motor/Generator.0000b = No test requested / No test in process0001b = Tes...";
CM_ SG_ 2566613246 MtGt2IvtHVtBsAtvIstTstRsts "Motor/Generator 2 Inverter High-Voltage Bus Active Isolation Test Results: The isolation resistance that resulted from the High-Voltage Bus Active Isolation Test.See SPN 10813 [High-Voltage Bus Active Isolation Test Status] for test status and SPN 10...";
CM_ SG_ 2566613246 MtGt2IvtHVtBsPssvIstTstRsts "Motor/Generator 2 Inverter High-Voltage Bus Passive Isolation Test Results: The isolation resistance that resulted from the High-Voltage Bus Passive Isolation Test.See SPN 10814 [High-Voltage Bus Passive Isolation Test Status] for test status and SPN...";
CM_ BO_ 2566613502 "Motor/Generator 1 Inverter Active Power Limits";
CM_ SG_ 2566613502 MtGt1IvtPwLtddtUddRs "Motor/Generator 1 Inverter Power Limited due to Undefined Reason: Output power is being limited due to an undefined reason.00b = No power limit for this reason01b = Power limited for this reason10b = Error11b = Not Available";
CM_ SG_ 2566613502 MtGt1IvtPwLtddtDCSdCtMx "Motor/Generator 1 Inverter Power Limited due to DC Side Current Maximum: Output power is being limited due to SPN 10175 [Inverter DC Side Current] approaching or exceeding the SPN 10214 [Inverter Limits Active DC Side Current Maximum].00b = No power ...";
CM_ SG_ 2566613502 MtGt1IvtPwLtddtDCSdCtM "Motor/Generator 1 Inverter Power Limited due to DC Side Current Minimum: Output power is being limited due to SPN 10175 [Inverter DC Side Current] approaching or falling below the SPN 10215 [Inverter Limits Active DC Side Current Minimum].00b = No po...";
CM_ SG_ 2566613502 MtGt1IvtPwLtddtDCSdVtMx "Motor/Generator 1 Inverter Power Limited due to DC Side Voltage Maximum: Output power is being limited due to SPN 9101 [Inverter DC Side Voltage] approaching or exceeding the SPN 10212 [Inverter Limits Active DC Side Voltage Maximum].00b = No power l...";
CM_ SG_ 2566613502 MtGt1IvtPwLtddtDCSdVtM "Motor/Generator 1 Inverter Power Limited due to DC Side Voltage Minimum: Output power is being limited due to SPN 9101 [Inverter DC Side Voltage] approaching or falling below the SPN 10213 [Inverter Limits Active DC Side Voltage Minimum].00b = No pow...";
CM_ SG_ 2566613502 MtGt1IvtPwLtddtMPwMx "Motor/Generator 1 Inverter Power Limited due to Mechanical Power Maximum: Output power is being limited due to Mechanical Power (product of SPN 9061 [Torque] and SPN 9057 [Speed]) approaching or exceeding the SPN 10184 [Inverter Limits Active Mechani...";
CM_ SG_ 2566613502 MtGt1IvtPwLtddtMPwM "Motor/Generator 1 Inverter Power Limited due to Mechanical Power Minimum: Output power is being limited due to Mechanical Power (product of SPN 9061 [Torque] and SPN 9057 [Speed]) approaching or falling below the SPN 10185 [Inverter Limits Active Mec...";
CM_ SG_ 2566613502 MtGt1IvtPwLtddtDCSdPwMx "Motor/Generator 1 Inverter Power Limited due to DC Side Power Maximum: Output power is being limited due to DC Side Power (product of SPN 10175 [Inverter DC Side Current] and SPN 9101 [Inverter DC Side Voltage]) approaching or exceeding the SPN 10186...";
CM_ SG_ 2566613502 MtGt1IvtPwLtddtDCSdPwM "Motor/Generator 1 Inverter Power Limited due to DC Side Power Minimum: Output power is being limited due to DC Side Power (product of SPN 10175 [Inverter DC Side Current] and SPN 9101 [Inverter DC Side Voltage]) approaching or falling below the SPN 1...";
CM_ SG_ 2566613502 MtrGnrtr1InvrtrPwrLmtddtTrqMxmm "Motor/Generator 1 Inverter Power Limited due to Torque Maximum: Output power is being limited due to SPN 9061 [Torque] approaching or exceeding the SPN 10196 [Inverter Limits Active Torque Maximum].00b = No power limit for this reason01b = Power limi...";
CM_ SG_ 2566613502 MtrGnrtr1InvrtrPwrLmtddtTrqMnmm "Motor/Generator 1 Inverter Power Limited due to Torque Minimum: Output power is being limited due to SPN 9061 [Torque] approaching or falling below the SPN 10197 [Inverter Limits Active Torque Minimum].00b = No power limit for this reason01b = Power ...";
CM_ SG_ 2566613502 MtrGnrtr1InvrtrPwrLmtddtSpdMxmm "Motor/Generator 1 Inverter Power Limited due to Speed Maximum: Output power is being limited due to SPN 9057 [Speed] approaching or exceeding the SPN 10198 [Inverter Limits Active Speed Maximum].00b = No power limit for this reason01b = Power limited...";
CM_ SG_ 2566613502 MtrGnrtr1InvrtrPwrLmtddtSpdMnmm "Motor/Generator 1 Inverter Power Limited due to Speed Minimum: Output power is being limited due to SPN 9057 [Speed] approaching or falling below the SPN 10199 [Inverter Limits Active Speed Minimum].00b = No power limit for this reason01b = Power lim...";
CM_ SG_ 2566613502 MtGt1IvtPwLtddtIvtTpt "Motor/Generator 1 Inverter Power Limited due to Inverter Temperature: Output power is being limited due to one or more inverter temperature(s), see SPNs 10216 through 10219 [Inverter Temperature 1-4] approaching or exceeding internally defined limit(...";
CM_ SG_ 2566613502 MtGt1IvtPwLtddtMtTpt "Motor/Generator 1 Inverter Power Limited due to Motor Temperature: Output power is being limited due to one or more motor temperature(s), see SPNs 9059 and 10220 through 10222 [Motor Temperature 1-4] approaching or exceeding internally defined limit(...";
CM_ BO_ 2566613758 "Motor/Generator 1 Inverter Isolation Integrity";
CM_ SG_ 2566613758 MtrGnrtr1InvrtrIsltnIntgrtCRC "Motor/Generator 1 Inverter Isolation Integrity CRC: The CRC is defined as follows:• Length: 8 bits• Polynomial: x^8+x^5+x^3+x^2+x+1• Initial Value: FFh• Input Data Reflection: Not reflected• Result Data Reflection: Not reflected• XOR value: FFhSAE ma...";
CM_ SG_ 2566613758 MtrGnrtr1InvrtrIsltnIntgrtCntr "Motor/Generator 1 Inverter Isolation Integrity Counter: The message counter is used to detect situations where the transmitting ECU malfunction repeats the same frame all the time. The receiver of the information may use the counter parameter to dete...";
CM_ SG_ 2566613758 MtGt1IvtDCSdNtvtCsssGdVt "Motor/Generator 1 Inverter DC Side Negative to Chassis Ground Voltage: The voltage level of the high voltage DC side, as measured by the inverter between the negative side of the High Voltage DC Side input and the chassis of the inverter enclosure.  ...";
CM_ SG_ 2566613758 MtGt1IvtHVtBsAtvIstTstStts "Motor/Generator 1 Inverter High-Voltage Bus Active Isolation Test Status: Status of the high-voltage bus electrical active isolation test as performed by this instance of the Motor/Generator.0000b = No test requested / No test in process0001b = Test ...";
CM_ SG_ 2566613758 MtGt1IvtHVtBsPssvIstTstStts "Motor/Generator 1 Inverter High-Voltage Bus Passive Isolation Test Status: Status of the high-voltage bus electrical passive isolation test as performed by this instance of the Motor/Generator.0000b = No test requested / No test in process0001b = Tes...";
CM_ SG_ 2566613758 MtGt1IvtHVtBsAtvIstTstRsts "Motor/Generator 1 Inverter High-Voltage Bus Active Isolation Test Results: The isolation resistance that resulted from the High-Voltage Bus Active Isolation Test.See SPN 10775 [High-Voltage Bus Active Isolation Test Status] for test status and SPN 10...";
CM_ SG_ 2566613758 MtGt1IvtHVtBsPssvIstTstRsts "Motor/Generator 1 Inverter High-Voltage Bus Passive Isolation Test Results: The isolation resistance that resulted from the High-Voltage Bus Passive Isolation Test.See SPN 10776 [High-Voltage Bus Passive Isolation Test Status] for test status and SPN...";
CM_ BO_ 2566614014 "High Voltage Bus Information";
CM_ SG_ 2566614014 HighVoltageDCBusAvailability "High Voltage DC Bus Availability: This parameter indicates the availability of the high voltage bus to power components.  Power sources may include, but are not limited to batteries, fuel cells, generators, etc.  Note:  For batteries, SPN 8413 exists...";
BA_DEF_ SG_  "SPN" INT 0 524287;
BA_DEF_ BO_  "VFrameFormat" ENUM  "StandardCAN","ExtendedCAN","reserved","J1939PG";
BA_DEF_DEF_  "SPN" 0;
BA_DEF_DEF_  "VFrameFormat" "J1939PG";
BA_ "SPN" SG_ 2365272574 MtrGnrtr6InvrtrRfrn2CRC 12205;
BA_ "SPN" SG_ 2365272574 MtrGnrtr6InvrtrRfrn2Cntr 12206;
BA_ "SPN" SG_ 2365272574 MtrGnrtr6InvrtrRfrnCrrnt 12207;
BA_ "SPN" SG_ 2365272574 MtrGnrtr6InvrtrRfrnVltg 12208;
BA_ "SPN" SG_ 2566599422 MtrGnrtr6InvrtrTmprtr1 12221;
BA_ "SPN" SG_ 2566599422 MtrGnrtr6InvrtrTmprtr2 12222;
BA_ "SPN" SG_ 2566599422 MtrGnrtr6InvrtrTmprtr3 12223;
BA_ "SPN" SG_ 2566599422 MtrGnrtr6InvrtrTmprtr4 12224;
BA_ "SPN" SG_ 2566599678 MotorGenerator6Temperature1 12156;
BA_ "SPN" SG_ 2566599678 MotorGenerator6Temperature2 12225;
BA_ "SPN" SG_ 2566599678 MotorGenerator6Temperature3 12226;
BA_ "SPN" SG_ 2566599678 MotorGenerator6Temperature4 12227;
BA_ "SPN" SG_ 2566599934 MtrGnrtr6InvrtrIsltnIntgrtCRC 12236;
BA_ "SPN" SG_ 2566599934 MtrGnrtr6InvrtrIsltnIntgrtCntr 12237;
BA_ "SPN" SG_ 2566599934 MtGt6IvtDCSdNtvtCsssGdVt 12238;
BA_ "SPN" SG_ 2566599934 MtGt6IvtHVtBsAtvIstTstStts 12239;
BA_ "SPN" SG_ 2566599934 MtGt6IvtHVtBsPssvIstTstStts 12240;
BA_ "SPN" SG_ 2566599934 MtGt6IvtHVtBsAtvIstTstRsts 12241;
BA_ "SPN" SG_ 2566599934 MtGt6IvtHVtBsPssvIstTstRsts 12242;
BA_ "SPN" SG_ 2566600190 MtGt6IvtPwLtddtUddRs 12243;
BA_ "SPN" SG_ 2566600190 MtGt6IvtPwLtddtDCSdCtMx 12244;
BA_ "SPN" SG_ 2566600190 MtGt6IvtPwLtddtDCSdCtM 12245;
BA_ "SPN" SG_ 2566600190 MtGt6IvtPwLtddtDCSdVtMx 12246;
BA_ "SPN" SG_ 2566600190 MtGt6IvtPwLtddtDCSdVtM 12247;
BA_ "SPN" SG_ 2566600190 MtGt6IvtPwLtddtMPwMx 12248;
BA_ "SPN" SG_ 2566600190 MtGt6IvtPwLtddtMPwM 12249;
BA_ "SPN" SG_ 2566600190 MtGt6IvtPwLtddtDCSdPwMx 12250;
BA_ "SPN" SG_ 2566600190 MtGt6IvtPwLtddtDCSdPwM 12251;
BA_ "SPN" SG_ 2566600190 MtrGnrtr6InvrtrPwrLmtddtTrqMxmm 12252;
BA_ "SPN" SG_ 2566600190 MtrGnrtr6InvrtrPwrLmtddtTrqMnmm 12253;
BA_ "SPN" SG_ 2566600190 MtrGnrtr6InvrtrPwrLmtddtSpdMxmm 12254;
BA_ "SPN" SG_ 2566600190 MtrGnrtr6InvrtrPwrLmtddtSpdMnmm 12255;
BA_ "SPN" SG_ 2566600190 MtGt6IvtPwLtddtIvtTpt 12256;
BA_ "SPN" SG_ 2566600190 MtGt6IvtPwLtddtMtTpt 12257;
BA_ "SPN" SG_ 2365273854 MtrGnrtr5InvrtrRfrn1CRC 12055;
BA_ "SPN" SG_ 2365273854 MtrGnrtr5InvrtrRfrn1Cntr 12056;
BA_ "SPN" SG_ 2365273854 MtrGnrtr5InvrtrRfrnTrq 12057;
BA_ "SPN" SG_ 2365273854 MtrGnrtr5InvrtrRfrnSpd 12058;
BA_ "SPN" SG_ 2365273854 MtrGnrtr5InvrtrRfrnPwr 12059;
BA_ "SPN" SG_ 2365274110 MtrGnrtr5InvrtrStts1CRC 12060;
BA_ "SPN" SG_ 2365274110 MtrGnrtr5InvrtrStts1Cntr 12061;
BA_ "SPN" SG_ 2365274110 MotorGenerator5Torque 12039;
BA_ "SPN" SG_ 2365274110 MotorGenerator5Speed 12037;
BA_ "SPN" SG_ 2365274110 MtrGnrtr5InvrtrDCSdCrrnt 12062;
BA_ "SPN" SG_ 2365274110 MtrGnrtr5InvrtrDCSdVltg 12040;
BA_ "SPN" SG_ 2365274366 MtrGnrtr5InvrtrRfrn2CRC 12087;
BA_ "SPN" SG_ 2365274366 MtrGnrtr5InvrtrRfrn2Cntr 12088;
BA_ "SPN" SG_ 2365274366 MtrGnrtr5InvrtrRfrnCrrnt 12089;
BA_ "SPN" SG_ 2365274366 MtrGnrtr5InvrtrRfrnVltg 12090;
BA_ "SPN" SG_ 2566601214 MtrGnrtr5InvrtrTmprtr1 12103;
BA_ "SPN" SG_ 2566601214 MtrGnrtr5InvrtrTmprtr2 12104;
BA_ "SPN" SG_ 2566601214 MtrGnrtr5InvrtrTmprtr3 12105;
BA_ "SPN" SG_ 2566601214 MtrGnrtr5InvrtrTmprtr4 12106;
BA_ "SPN" SG_ 2566601470 MotorGenerator5Temperature1 12038;
BA_ "SPN" SG_ 2566601470 MotorGenerator5Temperature2 12107;
BA_ "SPN" SG_ 2566601470 MotorGenerator5Temperature3 12108;
BA_ "SPN" SG_ 2566601470 MotorGenerator5Temperature4 12109;
BA_ "SPN" SG_ 2566601726 MtrGnrtr5InvrtrIsltnIntgrtCRC 12118;
BA_ "SPN" SG_ 2566601726 MtrGnrtr5InvrtrIsltnIntgrtCntr 12119;
BA_ "SPN" SG_ 2566601726 MtGt5IvtDCSdNtvtCsssGdVt 12120;
BA_ "SPN" SG_ 2566601726 MtGt5IvtHVtBsAtvIstTstStts 12121;
BA_ "SPN" SG_ 2566601726 MtGt5IvtHVtBsPssvIstTstStts 12122;
BA_ "SPN" SG_ 2566601726 MtGt5IvtHVtBsAtvIstTstRsts 12123;
BA_ "SPN" SG_ 2566601726 MtGt5IvtHVtBsPssvIstTstRsts 12124;
BA_ "SPN" SG_ 2566601982 MtGt5IvtPwLtddtUddRs 12125;
BA_ "SPN" SG_ 2566601982 MtGt5IvtPwLtddtDCSdCtMx 12126;
BA_ "SPN" SG_ 2566601982 MtGt5IvtPwLtddtDCSdCtM 12127;
BA_ "SPN" SG_ 2566601982 MtGt5IvtPwLtddtDCSdVtMx 12128;
BA_ "SPN" SG_ 2566601982 MtGt5IvtPwLtddtDCSdVtM 12129;
BA_ "SPN" SG_ 2566601982 MtGt5IvtPwLtddtMPwMx 12130;
BA_ "SPN" SG_ 2566601982 MtGt5IvtPwLtddtMPwM 12131;
BA_ "SPN" SG_ 2566601982 MtGt5IvtPwLtddtDCSdPwMx 12132;
BA_ "SPN" SG_ 2566601982 MtGt5IvtPwLtddtDCSdPwM 12133;
BA_ "SPN" SG_ 2566601982 MtrGnrtr5InvrtrPwrLmtddtTrqMxmm 12134;
BA_ "SPN" SG_ 2566601982 MtrGnrtr5InvrtrPwrLmtddtTrqMnmm 12135;
BA_ "SPN" SG_ 2566601982 MtrGnrtr5InvrtrPwrLmtddtSpdMxmm 12136;
BA_ "SPN" SG_ 2566601982 MtrGnrtr5InvrtrPwrLmtddtSpdMnmm 12137;
BA_ "SPN" SG_ 2566601982 MtGt5IvtPwLtddtIvtTpt 12138;
BA_ "SPN" SG_ 2566601982 MtGt5IvtPwLtddtMtTpt 12139;
BA_ "SPN" SG_ 2365275646 MtrGnrtr4InvrtrRfrn1CRC 11937;
BA_ "SPN" SG_ 2365275646 MtrGnrtr4InvrtrRfrn1Cntr 11938;
BA_ "SPN" SG_ 2365275646 MtrGnrtr4InvrtrRfrnTrq 11939;
BA_ "SPN" SG_ 2365275646 MtrGnrtr4InvrtrRfrnSpd 11940;
BA_ "SPN" SG_ 2365275646 MtrGnrtr4InvrtrRfrnPwr 11941;
BA_ "SPN" SG_ 2365275902 MtrGnrtr4InvrtrStts1CRC 11942;
BA_ "SPN" SG_ 2365275902 MtrGnrtr4InvrtrStts1Cntr 11943;
BA_ "SPN" SG_ 2365275902 MotorGenerator4Torque 11921;
BA_ "SPN" SG_ 2365275902 MotorGenerator4Speed 11919;
BA_ "SPN" SG_ 2365275902 MtrGnrtr4InvrtrDCSdCrrnt 11944;
BA_ "SPN" SG_ 2365275902 MtrGnrtr4InvrtrDCSdVltg 11922;
BA_ "SPN" SG_ 2365276158 MtrGnrtr4InvrtrRfrn2CRC 11969;
BA_ "SPN" SG_ 2365276158 MtrGnrtr4InvrtrRfrn2Cntr 11970;
BA_ "SPN" SG_ 2365276158 MtrGnrtr4InvrtrRfrnCrrnt 11971;
BA_ "SPN" SG_ 2365276158 MtrGnrtr4InvrtrRfrnVltg 11972;
BA_ "SPN" SG_ 2566603006 MtrGnrtr4InvrtrTmprtr1 11985;
BA_ "SPN" SG_ 2566603006 MtrGnrtr4InvrtrTmprtr2 11986;
BA_ "SPN" SG_ 2566603006 MtrGnrtr4InvrtrTmprtr3 11987;
BA_ "SPN" SG_ 2566603006 MtrGnrtr4InvrtrTmprtr4 11988;
BA_ "SPN" SG_ 2566603262 MotorGenerator4Temperature1 11920;
BA_ "SPN" SG_ 2566603262 MotorGenerator4Temperature2 11989;
BA_ "SPN" SG_ 2566603262 MotorGenerator4Temperature3 11990;
BA_ "SPN" SG_ 2566603262 MotorGenerator4Temperature4 11991;
BA_ "SPN" SG_ 2566603518 MtrGnrtr4InvrtrIsltnIntgrtCRC 12000;
BA_ "SPN" SG_ 2566603518 MtrGnrtr4InvrtrIsltnIntgrtCntr 12001;
BA_ "SPN" SG_ 2566603518 MtGt4IvtDCSdNtvtCsssGdVt 12002;
BA_ "SPN" SG_ 2566603518 MtGt4IvtHVtBsAtvIstTstStts 12003;
BA_ "SPN" SG_ 2566603518 MtGt4IvtHVtBsPssvIstTstStts 12004;
BA_ "SPN" SG_ 2566603518 MtGt4IvtHVtBsAtvIstTstRsts 12005;
BA_ "SPN" SG_ 2566603518 MtGt4IvtHVtBsPssvIstTstRsts 12006;
BA_ "SPN" SG_ 2566603774 MtGt4IvtPwLtddtUddRs 12007;
BA_ "SPN" SG_ 2566603774 MtGt4IvtPwLtddtDCSdCtMx 12008;
BA_ "SPN" SG_ 2566603774 MtGt4IvtPwLtddtDCSdCtM 12009;
BA_ "SPN" SG_ 2566603774 MtGt4IvtPwLtddtDCSdVtMx 12010;
BA_ "SPN" SG_ 2566603774 MtGt4IvtPwLtddtDCSdVtM 12011;
BA_ "SPN" SG_ 2566603774 MtGt4IvtPwLtddtMPwMx 12012;
BA_ "SPN" SG_ 2566603774 MtGt4IvtPwLtddtMPwM 12013;
BA_ "SPN" SG_ 2566603774 MtGt4IvtPwLtddtDCSdPwMx 12014;
BA_ "SPN" SG_ 2566603774 MtGt4IvtPwLtddtDCSdPwM 12015;
BA_ "SPN" SG_ 2566603774 MtrGnrtr4InvrtrPwrLmtddtTrqMxmm 12016;
BA_ "SPN" SG_ 2566603774 MtrGnrtr4InvrtrPwrLmtddtTrqMnmm 12017;
BA_ "SPN" SG_ 2566603774 MtrGnrtr4InvrtrPwrLmtddtSpdMxmm 12018;
BA_ "SPN" SG_ 2566603774 MtrGnrtr4InvrtrPwrLmtddtSpdMnmm 12019;
BA_ "SPN" SG_ 2566603774 MtGt4IvtPwLtddtIvtTpt 12020;
BA_ "SPN" SG_ 2566603774 MtGt4IvtPwLtddtMtTpt 12021;
BA_ "SPN" SG_ 2365277438 MtrGnrtr3InvrtrRfrn1CRC 11819;
BA_ "SPN" SG_ 2365277438 MtrGnrtr3InvrtrRfrn1Cntr 11820;
BA_ "SPN" SG_ 2365277438 MtrGnrtr3InvrtrRfrnTrq 11821;
BA_ "SPN" SG_ 2365277438 MtrGnrtr3InvrtrRfrnSpd 11822;
BA_ "SPN" SG_ 2365277438 MtrGnrtr3InvrtrRfrnPwr 11823;
BA_ "SPN" SG_ 2365277694 MtrGnrtr3InvrtrStts1CRC 11824;
BA_ "SPN" SG_ 2365277694 MtrGnrtr3InvrtrStts1Cntr 11825;
BA_ "SPN" SG_ 2365277694 MotorGenerator3Torque 11803;
BA_ "SPN" SG_ 2365277694 MotorGenerator3Speed 11801;
BA_ "SPN" SG_ 2365277694 MtrGnrtr3InvrtrDCSdCrrnt 11826;
BA_ "SPN" SG_ 2365277694 MtrGnrtr3InvrtrDCSdVltg 11804;
BA_ "SPN" SG_ 2365277950 MtrGnrtr3InvrtrRfrn2CRC 11851;
BA_ "SPN" SG_ 2365277950 MtrGnrtr3InvrtrRfrn2Cntr 11852;
BA_ "SPN" SG_ 2365277950 MtrGnrtr3InvrtrRfrnCrrnt 11853;
BA_ "SPN" SG_ 2365277950 MtrGnrtr3InvrtrRfrnVltg 11854;
BA_ "SPN" SG_ 2566604798 MtrGnrtr3InvrtrTmprtr1 11867;
BA_ "SPN" SG_ 2566604798 MtrGnrtr3InvrtrTmprtr2 11868;
BA_ "SPN" SG_ 2566604798 MtrGnrtr3InvrtrTmprtr3 11869;
BA_ "SPN" SG_ 2566604798 MtrGnrtr3InvrtrTmprtr4 11870;
BA_ "SPN" SG_ 2566605054 MotorGenerator3Temperature1 11802;
BA_ "SPN" SG_ 2566605054 MotorGenerator3Temperature2 11871;
BA_ "SPN" SG_ 2566605054 MotorGenerator3Temperature3 11872;
BA_ "SPN" SG_ 2566605054 MotorGenerator3Temperature4 11873;
BA_ "SPN" SG_ 2566605310 MtrGnrtr3InvrtrIsltnIntgrtCRC 11882;
BA_ "SPN" SG_ 2566605310 MtrGnrtr3InvrtrIsltnIntgrtCntr 11883;
BA_ "SPN" SG_ 2566605310 MtGt3IvtDCSdNtvtCsssGdVt 11884;
BA_ "SPN" SG_ 2566605310 MtGt3IvtHVtBsAtvIstTstStts 11885;
BA_ "SPN" SG_ 2566605310 MtGt3IvtHVtBsPssvIstTstStts 11886;
BA_ "SPN" SG_ 2566605310 MtGt3IvtHVtBsAtvIstTstRsts 11887;
BA_ "SPN" SG_ 2566605310 MtGt3IvtHVtBsPssvIstTstRsts 11888;
BA_ "SPN" SG_ 2566605566 MtGt3IvtPwLtddtUddRs 11889;
BA_ "SPN" SG_ 2566605566 MtGt3IvtPwLtddtDCSdCtMx 11890;
BA_ "SPN" SG_ 2566605566 MtGt3IvtPwLtddtDCSdCtM 11891;
BA_ "SPN" SG_ 2566605566 MtGt3IvtPwLtddtDCSdVtMx 11892;
BA_ "SPN" SG_ 2566605566 MtGt3IvtPwLtddtDCSdVtM 11893;
BA_ "SPN" SG_ 2566605566 MtGt3IvtPwLtddtMPwMx 11894;
BA_ "SPN" SG_ 2566605566 MtGt3IvtPwLtddtMPwM 11895;
BA_ "SPN" SG_ 2566605566 MtGt3IvtPwLtddtDCSdPwMx 11896;
BA_ "SPN" SG_ 2566605566 MtGt3IvtPwLtddtDCSdPwM 11897;
BA_ "SPN" SG_ 2566605566 MtrGnrtr3InvrtrPwrLmtddtTrqMxmm 11898;
BA_ "SPN" SG_ 2566605566 MtrGnrtr3InvrtrPwrLmtddtTrqMnmm 11899;
BA_ "SPN" SG_ 2566605566 MtrGnrtr3InvrtrPwrLmtddtSpdMxmm 11900;
BA_ "SPN" SG_ 2566605566 MtrGnrtr3InvrtrPwrLmtddtSpdMnmm 11901;
BA_ "SPN" SG_ 2566605566 MtGt3IvtPwLtddtIvtTpt 11902;
BA_ "SPN" SG_ 2566605566 MtGt3IvtPwLtddtMtTpt 11903;
BA_ "SPN" SG_ 2566605822 SAddssCtDvTSC1CtPpsP7 11756;
BA_ "SPN" SG_ 2566605822 TSC1CntrlPrpsP7RdnssStts 11757;
BA_ "SPN" SG_ 2566606078 CabHeaterPower 11755;
BA_ "SPN" SG_ 2566606334 EngineAirFilter1LifeRemaining 11737;
BA_ "SPN" SG_ 2566606334 EngineAirFilter2LifeRemaining 11738;
BA_ "SPN" SG_ 2566606334 EngineAirFilter3LifeRemaining 11739;
BA_ "SPN" SG_ 2566606334 EngineAirFilter4LifeRemaining 11740;
BA_ "SPN" SG_ 2566606334 EngineFuelFilterLifeRemaining 11741;
BA_ "SPN" SG_ 2566606334 EngnFlFltrStnSdLfRmnng 11742;
BA_ "SPN" SG_ 2566606334 EngineOilFilterLifeRemaining 11743;
BA_ "SPN" SG_ 2566606334 TrnsmssnOIlFltrLfRmnng 11744;
BA_ "SPN" SG_ 2499497726 HoistLeverPosition 11727;
BA_ "SPN" SG_ 2499497726 HoistLeverDetentPositionStatus 11728;
BA_ "SPN" SG_ 2633715710 HVESP6StateofHealth 11721;
BA_ "SPN" SG_ 2633715710 HVESP6CnttrOpnUndrLdCnt 11722;
BA_ "SPN" SG_ 2633715710 HVESP6TotalEnergyThroughput 11723;
BA_ "SPN" SG_ 2633715710 HVESP6TotalAccumulatedCharge 11724;
BA_ "SPN" SG_ 2566607102 HVESP6NominalVoltage 11712;
BA_ "SPN" SG_ 2566607102 HVESP6RmmnddMnmmOprtngVltg 11713;
BA_ "SPN" SG_ 2566607102 HVESP6RmmnddMxmmOprtngVltg 11714;
BA_ "SPN" SG_ 2566607102 HVESP6RmmnddMnmmSttOfChrg 11715;
BA_ "SPN" SG_ 2566607102 HVESP6RmmnddMxmmSttOfChrg 11716;
BA_ "SPN" SG_ 2566607102 HVESP6RmmnddMxmmOprtngTmprtr 11717;
BA_ "SPN" SG_ 2566607102 HVESP6RmmnddMnmmOprtngTmprtr 11718;
BA_ "SPN" SG_ 2566607102 HVESP6CellMaximumVoltageLimit 11719;
BA_ "SPN" SG_ 2566607102 HVESP6CellMinimumVoltageLimit 11720;
BA_ "SPN" SG_ 2633716222 HVESP5StateofHealth 11605;
BA_ "SPN" SG_ 2633716222 HVESP5CnttrOpnUndrLdCnt 11606;
BA_ "SPN" SG_ 2633716222 HVESP5TotalEnergyThroughput 11607;
BA_ "SPN" SG_ 2633716222 HVESP5TotalAccumulatedCharge 11608;
BA_ "SPN" SG_ 2566607614 HVESP5NominalVoltage 11596;
BA_ "SPN" SG_ 2566607614 HVESP5RmmnddMnmmOprtngVltg 11597;
BA_ "SPN" SG_ 2566607614 HVESP5RmmnddMxmmOprtngVltg 11598;
BA_ "SPN" SG_ 2566607614 HVESP5RmmnddMnmmSttOfChrg 11599;
BA_ "SPN" SG_ 2566607614 HVESP5RmmnddMxmmSttOfChrg 11600;
BA_ "SPN" SG_ 2566607614 HVESP5RmmnddMxmmOprtngTmprtr 11601;
BA_ "SPN" SG_ 2566607614 HVESP5RmmnddMnmmOprtngTmprtr 11602;
BA_ "SPN" SG_ 2566607614 HVESP5CellMaximumVoltageLimit 11603;
BA_ "SPN" SG_ 2566607614 HVESP5CellMinimumVoltageLimit 11604;
BA_ "SPN" SG_ 2633716734 HVESP4StateofHealth 11489;
BA_ "SPN" SG_ 2633716734 HVESP4CnttrOpnUndrLdCnt 11490;
BA_ "SPN" SG_ 2633716734 HVESP4TotalEnergyThroughput 11491;
BA_ "SPN" SG_ 2633716734 HVESP4TotalAccumulatedCharge 11492;
BA_ "SPN" SG_ 2566608126 HVESP4NominalVoltage 11480;
BA_ "SPN" SG_ 2566608126 HVESP4RmmnddMnmmOprtngVltg 11481;
BA_ "SPN" SG_ 2566608126 HVESP4RmmnddMxmmOprtngVltg 11482;
BA_ "SPN" SG_ 2566608126 HVESP4RmmnddMnmmSttOfChrg 11483;
BA_ "SPN" SG_ 2566608126 HVESP4RmmnddMxmmSttOfChrg 11484;
BA_ "SPN" SG_ 2566608126 HVESP4RmmnddMxmmOprtngTmprtr 11485;
BA_ "SPN" SG_ 2566608126 HVESP4RmmnddMnmmOprtngTmprtr 11486;
BA_ "SPN" SG_ 2566608126 HVESP4CellMaximumVoltageLimit 11487;
BA_ "SPN" SG_ 2566608126 HVESP4CellMinimumVoltageLimit 11488;
BA_ "SPN" SG_ 2633717246 HVESP3StateofHealth 11373;
BA_ "SPN" SG_ 2633717246 HVESP3CnttrOpnUndrLdCnt 11374;
BA_ "SPN" SG_ 2633717246 HVESP3TotalEnergyThroughput 11375;
BA_ "SPN" SG_ 2633717246 HVESP3TotalAccumulatedCharge 11376;
BA_ "SPN" SG_ 2566608638 HVESP3NominalVoltage 11364;
BA_ "SPN" SG_ 2566608638 HVESP3RmmnddMnmmOprtngVltg 11365;
BA_ "SPN" SG_ 2566608638 HVESP3RmmnddMxmmOprtngVltg 11366;
BA_ "SPN" SG_ 2566608638 HVESP3RmmnddMnmmSttOfChrg 11367;
BA_ "SPN" SG_ 2566608638 HVESP3RmmnddMxmmSttOfChrg 11368;
BA_ "SPN" SG_ 2566608638 HVESP3RmmnddMxmmOprtngTmprtr 11369;
BA_ "SPN" SG_ 2566608638 HVESP3RmmnddMnmmOprtngTmprtr 11370;
BA_ "SPN" SG_ 2566608638 HVESP3CellMaximumVoltageLimit 11371;
BA_ "SPN" SG_ 2566608638 HVESP3CellMinimumVoltageLimit 11372;
BA_ "SPN" SG_ 2633717758 HVESP2StateofHealth 11257;
BA_ "SPN" SG_ 2633717758 HVESP2CnttrOpnUndrLdCnt 11258;
BA_ "SPN" SG_ 2633717758 HVESP2TotalEnergyThroughput 11259;
BA_ "SPN" SG_ 2633717758 HVESP2TotalAccumulatedCharge 11260;
BA_ "SPN" SG_ 2566609150 HVESP2NominalVoltage 11248;
BA_ "SPN" SG_ 2566609150 HVESP2RmmnddMnmmOprtngVltg 11249;
BA_ "SPN" SG_ 2566609150 HVESP2RmmnddMxmmOprtngVltg 11250;
BA_ "SPN" SG_ 2566609150 HVESP2RmmnddMnmmSttOfChrg 11251;
BA_ "SPN" SG_ 2566609150 HVESP2RmmnddMxmmSttOfChrg 11252;
BA_ "SPN" SG_ 2566609150 HVESP2RmmnddMxmmOprtngTmprtr 11253;
BA_ "SPN" SG_ 2566609150 HVESP2RmmnddMnmmOprtngTmprtr 11254;
BA_ "SPN" SG_ 2566609150 HVESP2CellMaximumVoltageLimit 11255;
BA_ "SPN" SG_ 2566609150 HVESP2CellMinimumVoltageLimit 11256;
BA_ "SPN" SG_ 2633718270 HVESP1StateofHealth 11141;
BA_ "SPN" SG_ 2633718270 HVESP1CnttrOpnUndrLdCnt 11142;
BA_ "SPN" SG_ 2633718270 HVESP1TotalEnergyThroughput 11143;
BA_ "SPN" SG_ 2633718270 HVESP1TotalAccumulatedCharge 11144;
BA_ "SPN" SG_ 2566609662 HVESP1NominalVoltage 11132;
BA_ "SPN" SG_ 2566609662 HVESP1RmmnddMnmmOprtngVltg 11133;
BA_ "SPN" SG_ 2566609662 HVESP1RmmnddMxmmOprtngVltg 11134;
BA_ "SPN" SG_ 2566609662 HVESP1RmmnddMnmmSttOfChrg 11135;
BA_ "SPN" SG_ 2566609662 HVESP1RmmnddMxmmSttOfChrg 11136;
BA_ "SPN" SG_ 2566609662 HVESP1RmmnddMxmmOprtngTmprtr 11137;
BA_ "SPN" SG_ 2566609662 HVESP1RmmnddMnmmOprtngTmprtr 11138;
BA_ "SPN" SG_ 2566609662 HVESP1CellMaximumVoltageLimit 11139;
BA_ "SPN" SG_ 2566609662 HVESP1CellMinimumVoltageLimit 11140;
BA_ "SPN" SG_ 2633718782 VFSSMdl1Dttr1DttrTp 10845;
BA_ "SPN" SG_ 2633718782 VFSSMdl1Dttr1DttrDtSLOT 10846;
BA_ "SPN" SG_ 2633718782 VFSSMdl1Dttr2DttrTp 10848;
BA_ "SPN" SG_ 2633718782 VFSSMdl1Dttr2DttrDtSLOT 10849;
BA_ "SPN" SG_ 2633718782 VFSSMdl1Dttr3DttrTp 10851;
BA_ "SPN" SG_ 2633718782 VFSSMdl1Dttr3DttrDtSLOT 10852;
BA_ "SPN" SG_ 2633718782 VFSSMdl1Dttr4DttrTp 10854;
BA_ "SPN" SG_ 2633718782 VFSSMdl1Dttr4DttrDtSLOT 10855;
BA_ "SPN" SG_ 2633718782 VFSSMdl1Dttr5DttrTp 10857;
BA_ "SPN" SG_ 2633718782 VFSSMdl1Dttr5DttrDtSLOT 10858;
BA_ "SPN" SG_ 2633718782 VFSSMdl1Dttr6DttrTp 10860;
BA_ "SPN" SG_ 2633718782 VFSSMdl1Dttr6DttrDtSLOT 10861;
BA_ "SPN" SG_ 2633718782 VFSSMdl1Dttr7DttrTp 10863;
BA_ "SPN" SG_ 2633718782 VFSSMdl1Dttr7DttrDtSLOT 10864;
BA_ "SPN" SG_ 2633718782 VFSSMdl1Dttr8DttrTp 10866;
BA_ "SPN" SG_ 2633718782 VFSSMdl1Dttr8DttrDtSLOT 10867;
BA_ "SPN" SG_ 2633719038 VFSSMdl2Dttr1DttrTp 10869;
BA_ "SPN" SG_ 2633719038 VFSSMdl2Dttr1DttrDtSLOT 10870;
BA_ "SPN" SG_ 2633719038 VFSSMdl2Dttr2DttrTp 10872;
BA_ "SPN" SG_ 2633719038 VFSSMdl2Dttr2DttrDtSLOT 10873;
BA_ "SPN" SG_ 2633719038 VFSSMdl2Dttr3DttrTp 10875;
BA_ "SPN" SG_ 2633719038 VFSSMdl2Dttr3DttrDtSLOT 10876;
BA_ "SPN" SG_ 2633719038 VFSSMdl2Dttr4DttrTp 10878;
BA_ "SPN" SG_ 2633719038 VFSSMdl2Dttr4DttrDtSLOT 10879;
BA_ "SPN" SG_ 2633719038 VFSSMdl2Dttr5DttrTp 10881;
BA_ "SPN" SG_ 2633719038 VFSSMdl2Dttr5DttrDtSLOT 10882;
BA_ "SPN" SG_ 2633719038 VFSSMdl2Dttr6DttrTp 10884;
BA_ "SPN" SG_ 2633719038 VFSSMdl2Dttr6DttrDtSLOT 10885;
BA_ "SPN" SG_ 2633719038 VFSSMdl2Dttr7DttrTp 10887;
BA_ "SPN" SG_ 2633719038 VFSSMdl2Dttr7DttrDtSLOT 10888;
BA_ "SPN" SG_ 2633719038 VFSSMdl2Dttr8DttrTp 10890;
BA_ "SPN" SG_ 2633719038 VFSSMdl2Dttr8DttrDtSLOT 10891;
BA_ "SPN" SG_ 2633719294 VFSSMdl3Dttr1DttrTp 10893;
BA_ "SPN" SG_ 2633719294 VFSSMdl3Dttr1DttrDtSLOT 10894;
BA_ "SPN" SG_ 2633719294 VFSSMdl3Dttr2DttrTp 10896;
BA_ "SPN" SG_ 2633719294 VFSSMdl3Dttr2DttrDtSLOT 10897;
BA_ "SPN" SG_ 2633719294 VFSSMdl3Dttr3DttrTp 10899;
BA_ "SPN" SG_ 2633719294 VFSSMdl3Dttr3DttrDtSLOT 10900;
BA_ "SPN" SG_ 2633719294 VFSSMdl3Dttr4DttrTp 10902;
BA_ "SPN" SG_ 2633719294 VFSSMdl3Dttr4DttrDtSLOT 10903;
BA_ "SPN" SG_ 2633719294 VFSSMdl3Dttr5DttrTp 10905;
BA_ "SPN" SG_ 2633719294 VFSSMdl3Dttr5DttrDtSLOT 10906;
BA_ "SPN" SG_ 2633719294 VFSSMdl3Dttr6DttrTp 10908;
BA_ "SPN" SG_ 2633719294 VFSSMdl3Dttr6DttrDtSLOT 10909;
BA_ "SPN" SG_ 2633719294 VFSSMdl3Dttr7DttrTp 10911;
BA_ "SPN" SG_ 2633719294 VFSSMdl3Dttr7DttrDtSLOT 10912;
BA_ "SPN" SG_ 2633719294 VFSSMdl3Dttr8DttrTp 10914;
BA_ "SPN" SG_ 2633719294 VFSSMdl3Dttr8DttrDtSLOT 10915;
BA_ "SPN" SG_ 2633719550 VFSSMdl4Dttr1DttrTp 10917;
BA_ "SPN" SG_ 2633719550 VFSSMdl4Dttr1DttrDtSLOT 10918;
BA_ "SPN" SG_ 2633719550 VFSSMdl4Dttr2DttrTp 10920;
BA_ "SPN" SG_ 2633719550 VFSSMdl4Dttr2DttrDtSLOT 10921;
BA_ "SPN" SG_ 2633719550 VFSSMdl4Dttr3DttrTp 10923;
BA_ "SPN" SG_ 2633719550 VFSSMdl4Dttr3DttrDtSLOT 10924;
BA_ "SPN" SG_ 2633719550 VFSSMdl4Dttr4DttrTp 10926;
BA_ "SPN" SG_ 2633719550 VFSSMdl4Dttr4DttrDtSLOT 10927;
BA_ "SPN" SG_ 2633719550 VFSSMdl4Dttr5DttrTp 10929;
BA_ "SPN" SG_ 2633719550 VFSSMdl4Dttr5DttrDtSLOT 10930;
BA_ "SPN" SG_ 2633719550 VFSSMdl4Dttr6DttrTp 10932;
BA_ "SPN" SG_ 2633719550 VFSSMdl4Dttr6DttrDtSLOT 10933;
BA_ "SPN" SG_ 2633719550 VFSSMdl4Dttr7DttrTp 10935;
BA_ "SPN" SG_ 2633719550 VFSSMdl4Dttr7DttrDtSLOT 10936;
BA_ "SPN" SG_ 2633719550 VFSSMdl4Dttr8DttrTp 10938;
BA_ "SPN" SG_ 2633719550 VFSSMdl4Dttr8DttrDtSLOT 10939;
BA_ "SPN" SG_ 2633719806 VFSSModule1HeatZone1Data 10941;
BA_ "SPN" SG_ 2633719806 VFSSModule1HeatZone2Data 10942;
BA_ "SPN" SG_ 2633719806 VFSSModule1ReleaseZone1Data 10943;
BA_ "SPN" SG_ 2633719806 VFSSModule1ReleaseZone2Data 10944;
BA_ "SPN" SG_ 2633719806 VFSSModule1PressureSwitch1Data 10945;
BA_ "SPN" SG_ 2633719806 VFSSModule1PressureSwitch2Data 10946;
BA_ "SPN" SG_ 2633719806 VFSSModule1PrimaryPowerVoltage 10947;
BA_ "SPN" SG_ 2633719806 VFSSMdl1SndrPwrVltg 10948;
BA_ "SPN" SG_ 2633720062 VFSSModule2HeatZone1Data 10949;
BA_ "SPN" SG_ 2633720062 VFSSModule2HeatZone2Data 10950;
BA_ "SPN" SG_ 2633720062 VFSSModule2ReleaseZone1Data 10951;
BA_ "SPN" SG_ 2633720062 VFSSModule2ReleaseZone2Data 10952;
BA_ "SPN" SG_ 2633720062 VFSSModule2PressureSwitch1Data 10953;
BA_ "SPN" SG_ 2633720062 VFSSModule2PressureSwitch2Data 10954;
BA_ "SPN" SG_ 2633720062 VFSSModule2PrimaryPowerVoltage 10955;
BA_ "SPN" SG_ 2633720062 VFSSMdl2SndrPwrVltg 10956;
BA_ "SPN" SG_ 2633720318 VFSSModule3HeatZone1Data 10957;
BA_ "SPN" SG_ 2633720318 VFSSModule3HeatZone2Data 10958;
BA_ "SPN" SG_ 2633720318 VFSSModule3ReleaseZone1Data 10959;
BA_ "SPN" SG_ 2633720318 VFSSModule3ReleaseZone2Data 10960;
BA_ "SPN" SG_ 2633720318 VFSSModule3PressureSwitch1Data 10961;
BA_ "SPN" SG_ 2633720318 VFSSModule3PressureSwitch2Data 10962;
BA_ "SPN" SG_ 2633720318 VFSSModule3PrimaryPowerVoltage 10963;
BA_ "SPN" SG_ 2633720318 VFSSMdl3SndrPwrVltg 10964;
BA_ "SPN" SG_ 2633720574 VFSSModule4HeatZone1Data 10965;
BA_ "SPN" SG_ 2633720574 VFSSModule4HeatZone2Data 10966;
BA_ "SPN" SG_ 2633720574 VFSSModule4ReleaseZone1Data 10967;
BA_ "SPN" SG_ 2633720574 VFSSModule4ReleaseZone2Data 10968;
BA_ "SPN" SG_ 2633720574 VFSSModule4PressureSwitch1Data 10969;
BA_ "SPN" SG_ 2633720574 VFSSModule4PressureSwitch2Data 10970;
BA_ "SPN" SG_ 2633720574 VFSSModule4PrimaryPowerVoltage 10971;
BA_ "SPN" SG_ 2633720574 VFSSMdl4SndrPwrVltg 10972;
BA_ "SPN" SG_ 2633720830 VFSSModule1Name 10973;
BA_ "SPN" SG_ 2633720830 VFSSModule1DetectorZone1Name 10974;
BA_ "SPN" SG_ 2633720830 VFSSModule1DetectorZone2Name 10975;
BA_ "SPN" SG_ 2633720830 VFSSModule1DetectorZone3Name 10976;
BA_ "SPN" SG_ 2633720830 VFSSModule1DetectorZone4Name 10977;
BA_ "SPN" SG_ 2633720830 VFSSModule1DetectorZone5Name 10978;
BA_ "SPN" SG_ 2633720830 VFSSModule1DetectorZone6Name 10979;
BA_ "SPN" SG_ 2633720830 VFSSModule1DetectorZone7Name 10980;
BA_ "SPN" SG_ 2633720830 VFSSModule1DetectorZone8Name 10981;
BA_ "SPN" SG_ 2633720830 VFSSModule1HeatZone1Name 10982;
BA_ "SPN" SG_ 2633720830 VFSSModule1HeatZone2Name 10983;
BA_ "SPN" SG_ 2633720830 VFSSModule1ReleaseZone1Name 10984;
BA_ "SPN" SG_ 2633720830 VFSSModule1ReleaseZone2Name 10985;
BA_ "SPN" SG_ 2633721086 VFSSModule2Name 10986;
BA_ "SPN" SG_ 2633721086 VFSSModule2DetectorZone1Name 10987;
BA_ "SPN" SG_ 2633721086 VFSSModule2DetectorZone2Name 10988;
BA_ "SPN" SG_ 2633721086 VFSSModule2DetectorZone3Name 10989;
BA_ "SPN" SG_ 2633721086 VFSSModule2DetectorZone4Name 10990;
BA_ "SPN" SG_ 2633721086 VFSSModule2DetectorZone5Name 10991;
BA_ "SPN" SG_ 2633721086 VFSSModule2DetectorZone6Name 10992;
BA_ "SPN" SG_ 2633721086 VFSSModule2DetectorZone7Name 10993;
BA_ "SPN" SG_ 2633721086 VFSSModule2DetectorZone8Name 10994;
BA_ "SPN" SG_ 2633721086 VFSSModule2HeatZone1Name 10995;
BA_ "SPN" SG_ 2633721086 VFSSModule2HeatZone2Name 10996;
BA_ "SPN" SG_ 2633721086 VFSSModule2ReleaseZone1Name 10997;
BA_ "SPN" SG_ 2633721086 VFSSModule2ReleaseZone2Name 10998;
BA_ "SPN" SG_ 2633721342 VFSSModule3Name 10999;
BA_ "SPN" SG_ 2633721342 VFSSModule3DetectorZone1Name 11000;
BA_ "SPN" SG_ 2633721342 VFSSModule3DetectorZone2Name 11001;
BA_ "SPN" SG_ 2633721342 VFSSModule3DetectorZone3Name 11002;
BA_ "SPN" SG_ 2633721342 VFSSModule3DetectorZone4Name 11003;
BA_ "SPN" SG_ 2633721342 VFSSModule3DetectorZone5Name 11004;
BA_ "SPN" SG_ 2633721342 VFSSModule3DetectorZone6Name 11005;
BA_ "SPN" SG_ 2633721342 VFSSModule3DetectorZone7Name 11006;
BA_ "SPN" SG_ 2633721342 VFSSModule3DetectorZone8Name 11007;
BA_ "SPN" SG_ 2633721342 VFSSModule3HeatZone1Name 11008;
BA_ "SPN" SG_ 2633721342 VFSSModule3HeatZone2Name 11009;
BA_ "SPN" SG_ 2633721342 VFSSModule3ReleaseZone1Name 11010;
BA_ "SPN" SG_ 2633721342 VFSSModule3ReleaseZone2Name 11011;
BA_ "SPN" SG_ 2633721598 VFSSModule4Name 11012;
BA_ "SPN" SG_ 2633721598 VFSSModule4DetectorZone1Name 11013;
BA_ "SPN" SG_ 2633721598 VFSSModule4DetectorZone2Name 11014;
BA_ "SPN" SG_ 2633721598 VFSSModule4DetectorZone3Name 11015;
BA_ "SPN" SG_ 2633721598 VFSSModule4DetectorZone4Name 11016;
BA_ "SPN" SG_ 2633721598 VFSSModule4DetectorZone5Name 11017;
BA_ "SPN" SG_ 2633721598 VFSSModule4DetectorZone6Name 11018;
BA_ "SPN" SG_ 2633721598 VFSSModule4DetectorZone7Name 11019;
BA_ "SPN" SG_ 2633721598 VFSSModule4DetectorZone8Name 11020;
BA_ "SPN" SG_ 2633721598 VFSSModule4HeatZone1Name 11021;
BA_ "SPN" SG_ 2633721598 VFSSModule4HeatZone2Name 11022;
BA_ "SPN" SG_ 2633721598 VFSSModule4ReleaseZone1Name 11023;
BA_ "SPN" SG_ 2633721598 VFSSModule4ReleaseZone2Name 11024;
BA_ "SPN" SG_ 2566612990 MtGt2IvtPwLtddtUddRs 10817;
BA_ "SPN" SG_ 2566612990 MtGt2IvtPwLtddtDCSdCtMx 10818;
BA_ "SPN" SG_ 2566612990 MtGt2IvtPwLtddtDCSdCtM 10819;
BA_ "SPN" SG_ 2566612990 MtGt2IvtPwLtddtDCSdVtMx 10820;
BA_ "SPN" SG_ 2566612990 MtGt2IvtPwLtddtDCSdVtM 10821;
BA_ "SPN" SG_ 2566612990 MtGt2IvtPwLtddtMPwMx 10822;
BA_ "SPN" SG_ 2566612990 MtGt2IvtPwLtddtMPwM 10823;
BA_ "SPN" SG_ 2566612990 MtGt2IvtPwLtddtDCSdPwMx 10824;
BA_ "SPN" SG_ 2566612990 MtGt2IvtPwLtddtDCSdPwM 10825;
BA_ "SPN" SG_ 2566612990 MtrGnrtr2InvrtrPwrLmtddtTrqMxmm 10826;
BA_ "SPN" SG_ 2566612990 MtrGnrtr2InvrtrPwrLmtddtTrqMnmm 10827;
BA_ "SPN" SG_ 2566612990 MtrGnrtr2InvrtrPwrLmtddtSpdMxmm 10828;
BA_ "SPN" SG_ 2566612990 MtrGnrtr2InvrtrPwrLmtddtSpdMnmm 10829;
BA_ "SPN" SG_ 2566612990 MtGt2IvtPwLtddtIvtTpt 10830;
BA_ "SPN" SG_ 2566612990 MtGt2IvtPwLtddtMtTpt 10831;
BA_ "SPN" SG_ 2566613246 MtrGnrtr2InvrtrIsltnIntgrtCRC 10810;
BA_ "SPN" SG_ 2566613246 MtrGnrtr2InvrtrIsltnIntgrtCntr 10811;
BA_ "SPN" SG_ 2566613246 MtGt2IvtDCSdNtvtCsssGdVt 10812;
BA_ "SPN" SG_ 2566613246 MtGt2IvtHVtBsAtvIstTstStts 10813;
BA_ "SPN" SG_ 2566613246 MtGt2IvtHVtBsPssvIstTstStts 10814;
BA_ "SPN" SG_ 2566613246 MtGt2IvtHVtBsAtvIstTstRsts 10815;
BA_ "SPN" SG_ 2566613246 MtGt2IvtHVtBsPssvIstTstRsts 10816;
BA_ "SPN" SG_ 2566613502 MtGt1IvtPwLtddtUddRs 10779;
BA_ "SPN" SG_ 2566613502 MtGt1IvtPwLtddtDCSdCtMx 10780;
BA_ "SPN" SG_ 2566613502 MtGt1IvtPwLtddtDCSdCtM 10781;
BA_ "SPN" SG_ 2566613502 MtGt1IvtPwLtddtDCSdVtMx 10782;
BA_ "SPN" SG_ 2566613502 MtGt1IvtPwLtddtDCSdVtM 10783;
BA_ "SPN" SG_ 2566613502 MtGt1IvtPwLtddtMPwMx 10784;
BA_ "SPN" SG_ 2566613502 MtGt1IvtPwLtddtMPwM 10785;
BA_ "SPN" SG_ 2566613502 MtGt1IvtPwLtddtDCSdPwMx 10786;
BA_ "SPN" SG_ 2566613502 MtGt1IvtPwLtddtDCSdPwM 10787;
BA_ "SPN" SG_ 2566613502 MtrGnrtr1InvrtrPwrLmtddtTrqMxmm 10788;
BA_ "SPN" SG_ 2566613502 MtrGnrtr1InvrtrPwrLmtddtTrqMnmm 10789;
BA_ "SPN" SG_ 2566613502 MtrGnrtr1InvrtrPwrLmtddtSpdMxmm 10790;
BA_ "SPN" SG_ 2566613502 MtrGnrtr1InvrtrPwrLmtddtSpdMnmm 10791;
BA_ "SPN" SG_ 2566613502 MtGt1IvtPwLtddtIvtTpt 10792;
BA_ "SPN" SG_ 2566613502 MtGt1IvtPwLtddtMtTpt 10793;
BA_ "SPN" SG_ 2566613758 MtrGnrtr1InvrtrIsltnIntgrtCRC 10772;
BA_ "SPN" SG_ 2566613758 MtrGnrtr1InvrtrIsltnIntgrtCntr 10773;
BA_ "SPN" SG_ 2566613758 MtGt1IvtDCSdNtvtCsssGdVt 10774;
BA_ "SPN" SG_ 2566613758 MtGt1IvtHVtBsAtvIstTstStts 10775;
BA_ "SPN" SG_ 2566613758 MtGt1IvtHVtBsPssvIstTstStts 10776;
BA_ "SPN" SG_ 2566613758 MtGt1IvtHVtBsAtvIstTstRsts 10777;
BA_ "SPN" SG_ 2566613758 MtGt1IvtHVtBsPssvIstTstRsts 10778;
BA_ "SPN" SG_ 2566614014 HighVoltageDCBusAvailability 10298;
